VERSION ""

NS_ :

BS_:

BU_: Bat1 OpticalSensor EMUS_BMS SCIMO_PE TelemetryNode Master SensorF SensorR BrakeF BrakeR PDU HVCU HVTU TestBench MDB1 MDB2 MDB3 MDB4 MDB5 MDB6 Track CLU

BO_ 302 MDB6_TX_CurrentDC: 4 Vector__XXX
 SG_ MDB6_TX_CurrentDC : 0|32@1- (0.0001,0) [-214748.3648|214748.3647] "A"  CLU

BO_ 299 MDB5_TX_CurrentDC: 4 Vector__XXX
 SG_ MDB5_TX_CurrentDC : 0|32@1- (0.0001,0) [-214748.3648|214748.3647] "A"  CLU

BO_ 286 MDB4_TX_CurrentDC: 4 Vector__XXX
 SG_ MDB4_TX_CurrentDC : 0|32@1- (0.0001,0) [-214748.3648|214748.3647] "A"  CLU

BO_ 283 MDB3_TX_CurrentDC: 4 Vector__XXX
 SG_ MDB3_TX_CurrentDC : 0|32@1- (0.0001,0) [-214748.3648|214748.3647] "A"  CLU

BO_ 270 MDB2_TX_CurrentDC: 4 Vector__XXX
 SG_ MDB2_TX_CurrentDC : 0|32@1- (0.0001,0) [-214748.3648|214748.3647] "A"  CLU

BO_ 267 MDB1_TX_CurrentDC: 4 Vector__XXX
 SG_ MDB1_TX_CurrentDC : 0|32@1- (0.0001,0) [-214748.3648|214748.3647] "A"  CLU

BO_ 269 MDB2_TX_CurrentTarget: 4 MDB2
 SG_ MDB2_CurrentTarget : 0|32@1- (0.0001,0) [-214748.3648|214748.3647] "A" Vector__XXX

BO_ 266 MDB1_TX_CurrentTarget: 4 MDB1
 SG_ MDB1_CurrentTarget : 0|32@1- (0.0001,0) [-214748.3648|214748.3647] "A" Vector__XXX

BO_ 155 CLU_RX_ConfigureAirGap: 4 Vector__XXX
 SG_ CLU_RX_ConfigureAirGap : 0|32@1- (0.0001,0) [-214748.3648|214748.3647] ""  CLU

BO_ 1072 SensorF_RX_IgnoreLevel: 2 Vector__XXX
 SG_ SensorF_EmergencyLevel : 8|8@1+ (1,0) [0|255] "" Vector__XXX
 SG_ SensorF_IgnoreLevel : 0|8@1+ (1,0) [0|255] ""  SensorF

BO_ 5 PDU_TX_Error: 8 PDU
 SG_ PDU_TX_ErrorPrio : 0|8@1+ (1,0) [0|255] ""  SensorF

BO_ 4 CLU_TX_Error: 8 CLU
 SG_ CLU_TX_ErrorPrio : 0|8@1+ (1,0) [0|255] ""  SensorF

BO_ 3 BrakeF_TX_Error: 8 BrakeF
 SG_ BrakeF_TX_ErrorPrio : 0|8@1+ (1,0) [0|255] ""  SensorF

BO_ 57 CLU_TX_ActionRequest: 5 CLU
 SG_ CLU_TX_TargetAirGap : 8|32@1- (0.0001,0) [-214748.3648|214748.3647] "mm" Vector__XXX
 SG_ CLU_TX_ActionRequest : 0|8@1+ (1,0) [0|255] "" Vector__XXX

BO_ 564 CLU_RX_ActionRequest: 1 SensorF
 SG_ CLU_RX_ActionRequest : 0|8@1+ (1,0) [0|255] ""  SensorF

BO_ 2165346838 BMS44_2_Frame: 8 Vector__XXX
 SG_ BMS44_2_FramePayload : 0|64@1+ (1,0) [0|0] ""  SensorF

BO_ 1792 CLU_RX_StatusLedControll: 1 SensorF
 SG_ CLU_RX_ErrorStatus : 0|1@1+ (1,0) [0|1] ""  CLU

BO_ 592 CLU_TX_LevitationState: 1 CLU
 SG_ CLU_LevitationState : 0|8@1+ (1,0) [0|255] ""  SensorF

BO_ 768 CLU_TX_CoolingState: 1 Vector__XXX
 SG_ CLU_RequiresCooling : 0|1@1+ (1,0) [0|1] ""  SensorF

BO_ 274 MDB3_TX_CurrentMagnet: 4 MDB3
 SG_ MDB3_Current : 0|32@1- (0.0001,0) [-214748.3648|214748.3647] "A"  CLU

BO_ 295 MDB6_TX_CurrentMagnet: 4 MDB6
 SG_ MDB6_Current : 0|32@1- (0.0001,0) [-214748.3648|214748.3647] "A"  CLU

BO_ 297 MDB6_TX_Temperature: 4 MDB6
 SG_ MDB6_Temperature : 0|32@1- (0.0001,0) [-214748.3648|214748.3647] "C"  CLU

BO_ 294 MDB6_TX_AirGap: 4 MDB6
 SG_ MDB6_AirGap : 0|32@1- (0.0001,0) [-214748.3648|214748.3647] "mm"  CLU

BO_ 293 MDB6_TX_State: 1 MDB6
 SG_ MDB6_State : 0|8@1+ (1,0) [0|255] ""  CLU

BO_ 292 MDB5_TX_Temperature: 4 MDB5
 SG_ MDB5_Temperature : 0|32@1- (0.0001,0) [-214748.3648|214748.3647] "C"  CLU

BO_ 290 MDB5_TX_CurrentMagnet: 4 MDB5
 SG_ MDB5_Current : 0|32@1- (0.0001,0) [-214748.3648|214748.3647] "A"  CLU

BO_ 289 MDB5_TX_AirGap: 4 MDB5
 SG_ MDB5_AirGap : 0|32@1- (0.0001,0) [-214748.3648|214748.3647] "mm"  CLU

BO_ 288 MDB5_TX_State: 1 MDB5
 SG_ MDB5_State : 0|8@1+ (1,0) [0|255] ""  CLU

BO_ 281 MDB4_TX_Temperature: 4 MDB4
 SG_ MDB4_Temperature : 0|32@1- (0.0001,0) [-214748.3648|214748.3647] "C"  CLU

BO_ 279 MDB4_TX_CurrentMagnet: 4 MDB4
 SG_ MDB4_Current : 0|32@1- (0.0001,0) [-214748.3648|214748.3647] "mm"  CLU

BO_ 278 MDB4_TX_AirGap: 4 MDB4
 SG_ MDB4_AirGap : 0|32@1- (0.0001,0) [-214748.3648|214748.3647] "mm"  CLU

BO_ 277 MDB4_TX_State: 1 MDB4
 SG_ MDB4_State : 0|8@1+ (1,0) [0|255] ""  CLU

BO_ 276 MDB3_TX_Temperature: 4 MDB3
 SG_ MDB3_Temperature : 0|32@1- (0.0001,0) [-214748.3648|214748.3647] "C"  CLU

BO_ 273 MDB3_TX_AirGap: 4 MDB3
 SG_ MDB3_AirGap : 0|32@1- (0.0001,0) [-214748.3648|214748.3647] "mm"  CLU

BO_ 272 MDB3_TX_State: 1 MDB3
 SG_ MDB3_State : 0|8@1+ (1,0) [0|255] ""  CLU

BO_ 265 MDB2_TX_Temperature: 4 MDB2
 SG_ MDB2_Temperature : 0|32@1- (0.0001,0) [-214748.3648|214748.3647] "C"  CLU

BO_ 263 MDB2_TX_CurrentMagnet: 4 MDB2
 SG_ MDB2_Current : 0|32@1- (0.0001,0) [-214748.3648|214748.3647] "A"  CLU

BO_ 262 MDB2_TX_AirGap: 4 MDB2
 SG_ MDB2_AirGap : 0|32@1- (0.0001,0) [-214748.3648|214748.3647] "mm"  CLU

BO_ 261 MDB2_TX_State: 1 MDB2
 SG_ MDB2_State : 0|8@1+ (1,0) [0|255] ""  CLU

BO_ 258 MDB1_TX_CurrentMagnet: 4 MDB1
 SG_ MDB1_Current : 0|32@1- (0.0001,0) [0|0] "A"  CLU

BO_ 260 MDB1_TX_Temperature: 4 MDB1
 SG_ MDB1_Temperature : 0|32@1- (0.0001,0) [-214748.3648|214748.3647] "C"  CLU,SensorF

BO_ 257 MDB1_TX_AirGap: 4 MDB1
 SG_ MDB1_AirGap : 0|32@1- (0.0001,0) [-214748.3648|214748.3647] "mm"  CLU

BO_ 1041 BrakeF_TX_PressureCooling: 2 BrakeF
 SG_ BrakeF_TX_Pressure_Reservoir : 0|12@1+ (0.005,-2) [-2|18.475] "bar"  SensorF

BO_ 523 PDU_RX_LP_Enable: 1 PDU
 SG_ PDU_RX_LPCh7_Enable : 3|1@1+ (1,0) [0|1] ""  PDU,SensorF
 SG_ PDU_RX_LPCh6_Enable : 2|1@1+ (1,0) [0|1] ""  PDU,SensorF
 SG_ PDU_RX_LPCh5_Enable : 1|1@1+ (1,0) [0|1] ""  PDU,SensorF
 SG_ PDU_RX_LPCh4_Enable : 0|1@1+ (1,0) [0|1] ""  PDU,SensorF

BO_ 2148592864 BMS44_1_Frame: 8 Bat1
 SG_ BMS44_1_FramePayload : 0|64@1+ (1,0) [0|0] ""  SensorF

BO_ 1 Track_TX_Respond: 1 Track
 SG_ Track_TX_Response : 0|8@1+ (1,0) [0|255] ""  SensorF

BO_ 0 Track_RX_Controll: 1 SensorF
 SG_ Track_RX_Command : 0|8@1+ (1,0) [0|255] "" Vector__XXX

BO_ 512 TEST_GROUND_STATION_CONTROLL: 1 Vector__XXX
 SG_ TEST_GROUND_STATION_COMMAND : 0|8@1+ (1,0) [0|255] ""  SensorF

BO_ 256 MDB1_TX_State: 1 MDB1
 SG_ MDB1_State : 0|8@1+ (1,0) [0|255] ""  CLU,SensorF

BO_ 450 SensorR_RX_POD1: 8 Vector__XXX

BO_ 2684354555 OpticalSensor_TX_DetailData: 6 OpticalSensor
 SG_ OpticalSensor_TX_Angle : 32|16@1- (0.01,0) [-45|45] "�" Vector__XXX
 SG_ OpticalSensor_TX_VelTrans : 16|16@1- (0.036,0) [-200|200] "km/h" Vector__XXX
 SG_ OpticalSensor_TX_VelLong : 0|16@1+ (0.036,0) [0|400] "km/h" Vector__XXX

BO_ 2684354554 OpticalSensor_TX_MainData: 8 OpticalSensor
 SG_ OpticalSensor_TX_Distance : 32|32@1+ (0.001,0) [0|4294970] "m"  SensorF,SensorR
 SG_ OpticalSensor_TX_Vel : 16|16@1+ (0.036,0) [0|400] "km/h"  SensorF,SensorR
 SG_ OpticalSensor_TX_Timestamp : 0|16@1+ (1,0) [0|65535] ""  SensorF,SensorR

BO_ 2684354556 OpticalSensor_TX_Status: 8 OpticalSensor
 SG_ OpticalSensor_TX_VddOK : 62|1@1+ (1,0) [0|0] ""  SensorF
 SG_ OpticalSensor_TX_VeeOK : 61|1@1+ (1,0) [0|0] ""  SensorF
 SG_ OpticalSensor_TX_V33OK : 60|1@1+ (1,0) [0|0] ""  SensorF
 SG_ OpticalSensor_TX_V25OK : 59|1@1+ (1,0) [0|0] ""  SensorF
 SG_ OpticalSensor_TX_LEDStatus : 57|2@1+ (1,0) [0|0] ""  SensorF
 SG_ OpticalSensor_TX_LED_Cal : 56|1@1+ (1,0) [0|0] ""  SensorF
 SG_ OpticalSensor_TX_PowerOK : 55|1@1+ (1,0) [0|0] ""  SensorF
 SG_ OpticalSensor_TX_CurrentOK : 54|1@1+ (1,0) [0|0] ""  SensorF
 SG_ OpticalSensor_TX_CurrentLowHigh : 53|1@1+ (1,0) [0|0] ""  SensorF
 SG_ OpticalSensor_TX_OpticOK : 52|1@1+ (1,0) [0|0] ""  SensorF
 SG_ OpticalSensor_TX_TempOK : 51|1@1+ (1,0) [0|0] ""  SensorF
 SG_ OpticalSensor_TX_SensorOK : 50|1@1+ (1,0) [0|0] ""  SensorF
 SG_ OpticalSensor_TX_SelfTest : 49|1@1+ (1,0) [0|0] ""  SensorF
 SG_ OpticalSensor_TX_STST : 48|1@1+ (1,0) [0|0] ""  SensorF
 SG_ OpticalSensor_TX_LEDCurrent : 40|8@1+ (0.01,0) [0|2.55] "A"  SensorF
 SG_ OpticalSensor_TX_Temp : 32|8@1- (1,0) [-128|127] "�C"  SensorF
 SG_ OpticalSensor_TX_SensorNo : 24|8@1+ (1,0) [0|0] ""  SensorF
 SG_ OpticalSensor_TX_SerialNo : 0|24@1+ (1,0) [0|0] ""  SensorF

BO_ 2 CANzero_NMT: 4 Master
 SG_ CANzero_NMT_Node : 16|16@1+ (1,0) [0|63] ""  SensorF,SensorR,BrakeF,BrakeR,PDU,HVCU,HVTU,TelemetryNode,MDB1,MDB2,MDB3,MDB4,MDB5,MDB6,Track,CLU
 SG_ CANzero_NMT_State : 0|16@1+ (1,0) [0|0] ""  SensorF,SensorR,BrakeF,BrakeR,PDU,HVCU,HVTU,TelemetryNode,MDB1,MDB2,MDB3,MDB4,MDB5,MDB6,Track,CLU

BO_ 122 CANzero_Sync: 0 Master

BO_ 123 CANzero_Timestamp: 0 Master

BO_ 129 SensorF_EMCY: 4 SensorF

BO_ 385 SensorF_TX_StatePod: 1 SensorF
 SG_ SensorF_TX_PodState : 0|8@1+ (1,0) [0|0] ""  CLU,Track,BrakeF,PDU

BO_ 449 SensorF_RX_PDO1: 0 Vector__XXX

BO_ 513 SensorF_TX_FSMTransitions: 4 SensorF
 SG_ SensorF_TX_PreopHVCUT : 24|1@1+ (1,0) [0|0] "" Vector__XXX
 SG_ SensorF_TX_PreopPDUT : 16|1@1+ (1,0) [0|0] "" Vector__XXX
 SG_ SensorF_TX_PreopBrakeRT : 15|1@1+ (1,0) [0|0] "" Vector__XXX
 SG_ SensorF_TX_PreopBrakeFT : 14|1@1+ (1,0) [0|0] "" Vector__XXX
 SG_ SensorF_TX_PreopSensorRT : 13|1@1+ (1,0) [0|0] "" Vector__XXX
 SG_ SensorF_TX_EnableSensorRT : 12|1@1+ (1,0) [0|0] "" Vector__XXX
 SG_ SensorF_TX_EnablePDUT : 11|1@1+ (1,0) [0|0] "" Vector__XXX
 SG_ SensorF_TX_EnableHVCUT : 10|1@1+ (1,0) [0|0] "" Vector__XXX
 SG_ SensorF_TX_EnableBrakeRT : 9|1@1+ (1,0) [0|0] "" Vector__XXX
 SG_ SensorF_TX_EnableBrakeFT : 8|1@1+ (1,0) [0|0] "" Vector__XXX
 SG_ SensorF_TX_SetHVTransition : 7|1@1+ (1,0) [0|0] "" Vector__XXX
 SG_ SensorF_TX_PreopTransition : 6|1@1+ (1,0) [0|0] "" Vector__XXX
 SG_ SensorF_TX_LaunchStartTransition : 5|1@1+ (1,0) [0|0] "" Vector__XXX
 SG_ SensorF_TX_LaunchSetupTransition : 4|1@1+ (1,0) [0|0] "" Vector__XXX
 SG_ SensorF_TX_HWEnableTransition : 3|1@1+ (1,0) [0|0] "" Vector__XXX
 SG_ SensorF_TX_ErrorResetTransition : 2|1@1+ (1,0) [0|0] "" Vector__XXX
 SG_ SensorF_TX_EnableTransition : 1|1@1+ (1,0) [0|0] "" Vector__XXX
 SG_ SensorF_TX_BrakesTransition : 0|1@1+ (1,0) [0|0] "" Vector__XXX

BO_ 577 SensorF_RX_PDO2: 0 Vector__XXX

BO_ 641 SensorF_TX_PDO3: 0 SensorF

BO_ 705 SensorF_RX_PDO3: 0 Vector__XXX

BO_ 769 SensorF_TX_PDO4: 0 SensorF

BO_ 833 SensorF_RX_PDO4: 0 Vector__XXX

BO_ 897 SensorF_TX_PDO5: 0 SensorF

BO_ 961 SensorF_TX_PDO6: 0 SensorF

BO_ 1025 SensorF_TX_EncoderFront: 7 SensorF
 SG_ SensorF_GyroFront_X : 40|16@1- (0.017,0) [-557.056|557.039] "°/s"  SensorR
 SG_ SensorF_Vel_EncoderFront : 24|16@1- (0.002,0) [-65.536|65.534] "m/s"  SensorR
 SG_ SensorF_Pos_EncoderFront : 0|18@1- (0.005,0) [-655.36|655.355] "m"  SensorR

BO_ 1089 SensorF_TX_BMS: 2 SensorF
 SG_ SensorF_TX_BatteryTemp : 0|12@1+ (0.05,-30) [-30|174.75] "C"  PDU

BO_ 1153 SensorF_TX_Temperature: 8 SensorF
 SG_ SensorF_Cooling_Temp : 48|12@1+ (0.05,-30) [-30|174.75] "C"  PDU
 SG_ SensorF_LIMT_Stator_4 : 36|12@1+ (0.075,-20) [-20|287.125] "�C" Vector__XXX
 SG_ SensorF_LIMT_Stator_3 : 24|12@1+ (0.075,-20) [-20|287.125] "�C" Vector__XXX
 SG_ SensorF_LIMT_Stator_2 : 12|12@1+ (0.075,-20) [-20|287.125] "�C" Vector__XXX
 SG_ SensorF_LIMT_Stator_1 : 0|12@1+ (0.075,-20) [-20|287.125] "�C" Vector__XXX

BO_ 1217 SensorF_TX_AccFront: 8 SensorF
 SG_ SensorF_GyroFront_Z : 48|16@1- (0.017,0) [-557.056|557.039] "°/s"  SensorR
 SG_ SensorF_AccFront_Z : 32|16@1- (0.00125,0) [-40.96|40.95875] "m/s^2"  SensorR
 SG_ SensorF_AccFront_Y : 16|16@1- (0.00125,0) [-40.96|40.95875] "m/s^2"  SensorR
 SG_ SensorF_AccFront_X : 0|16@1- (0.00125,0) [-40.96|40.95875] "m/s^2"  SensorR

BO_ 1281 SensorF_TX_PDO11: 0 SensorF

BO_ 1345 SensorF_TX_PDO12: 0 SensorF

BO_ 1409 SensorF_SDO_Resp: 8 SensorF
 SG_ SensorF_SDO_RespCode : 12|4@1+ (1,0) [0|0] ""  TelemetryNode
 SG_ SensorF_SDO_ID M : 0|12@1+ (1,0) [0|4095] ""  TelemetryNode

BO_ 1473 SensorF_SDO_Req_Up: 8 TelemetryNode
 SG_ SensorF_SDO_ID M : 0|12@1+ (1,0) [0|4095] ""  SensorF

BO_ 1537 SensorF_SDO_Req_Down: 2 TelemetryNode
 SG_ SensorF_SDO_ID M : 0|12@1+ (1,0) [0|4095] ""  SensorF

BO_ 1793 SensorF_Heartbeat: 1 SensorF
 SG_ SensorF_NodeState : 0|8@1+ (1,0) [0|0] ""  SensorF,Master,TelemetryNode

BO_ 1857 SensorF_BTL_TX: 8 SensorF

BO_ 1921 SensorF_BTL_RX: 8 TelemetryNode

BO_ 130 SensorR_EMCY: 4 SensorR

BO_ 386 SensorR_TX_AccFront: 8 SensorR
 SG_ SensorR_TX_GyroFront_Z : 48|16@1- (0.017,0) [-557.056|557.039] "°/s" Vector__XXX
 SG_ SensorR_TX_AccFront_Z : 32|16@1- (0.00125,0) [-40.96|40.95875] "m/s^2" Vector__XXX
 SG_ SensorR_TX_AccFront_Y : 16|16@1- (0.00125,0) [-40.96|40.95875] "m/s^2" Vector__XXX
 SG_ SensorR_TX_AccFront_X : 0|16@1- (0.00125,0) [-40.96|40.95875] "m/s^2" Vector__XXX

BO_ 514 SensorR_TX_RunStatus: 1 SensorR
 SG_ SensorR_TX_ErrorFlag : 6|1@1+ (1,0) [0|0] "" Vector__XXX
 SG_ SensorR_TX_Enabled : 5|1@1+ (1,0) [0|0] "" Vector__XXX
 SG_ SensorR_TX_TrajectorySet : 4|1@1+ (1,0) [0|0] "" Vector__XXX
 SG_ SensorR_TX_RunState : 0|2@1+ (1,0) [0|0] ""  PDU

BO_ 578 SensorR_RX_PDO2: 0 Vector__XXX

BO_ 642 SensorR_TX_SE: 7 SensorR
 SG_ SensorR_TX_Pos : 32|20@1- (0.001,0) [-524.288|524.287] "m"  PDU,TelemetryNode
 SG_ SensorR_TX_Vel : 16|16@1- (0.002,0) [-65.536|65.534] "m/s"  PDU,TelemetryNode
 SG_ SensorR_TX_Acc : 0|16@1- (0.00125,0) [-40.96|40.95875] "m/s^2"  PDU,TelemetryNode

BO_ 706 SensorR_RX_RunControl: 1 SensorF
 SG_ SensorR_RX_ErrorReset : 3|1@1+ (1,0) [0|0] "" Vector__XXX
 SG_ SensorR_RX_Enable : 2|1@1+ (1,0) [0|0] "" Vector__XXX
 SG_ SensorR_RX_LaunchComm : 0|2@1+ (1,0) [0|0] "" Vector__XXX

BO_ 770 SensorR_TX_Vel: 6 SensorR
 SG_ SensorR_TX_Vel_Optical : 32|16@1- (0.002,0) [-65.536|65.534] "m/s" Vector__XXX
 SG_ SensorR_TX_Vel_EncoderRear : 16|16@1- (0.002,0) [-65.536|65.534] "m/s" Vector__XXX
 SG_ SensorR_TX_Vel_EncoderFront : 0|16@1- (0.002,0) [-65.536|65.534] "m/s" Vector__XXX

BO_ 834 SensorR_RX_PDO4: 0 Vector__XXX

BO_ 898 SensorR_TX_Gyro_XY: 8 SensorR
 SG_ SensorR_TX_GyroRear_Y : 48|16@1- (0.017,0) [-557.056|557.039] "°/s" Vector__XXX
 SG_ SensorR_TX_GyroRear_X : 32|16@1- (0.017,0) [-557.056|557.039] "°/s" Vector__XXX
 SG_ SensorR_TX_GyroFront_Y : 16|16@1- (0.017,0) [-557.056|557.039] "°/s" Vector__XXX
 SG_ SensorR_TX_GyroFront_X : 0|16@1- (0.017,0) [-557.056|557.039] "°/s" Vector__XXX

BO_ 962 SensorR_TX_TargetValues: 2 SensorR
 SG_ SensorR_TX_TargetVelocity : 0|14@1- (0.01,0) [-81.92|81.91] "m/s" Vector__XXX

BO_ 1026 SensorR_TX_GapHeight: 4 SensorR
 SG_ SensorR_TX_GapHeight_Right : 12|12@1- (0.0125,0) [-25.6|25.5875] "mm" Vector__XXX
 SG_ SensorR_TX_GapHeight_Left : 0|12@1- (0.0125,0) [-25.6|25.5875] "mm" Vector__XXX

BO_ 1090 SensorR_TX_PDO8: 0 SensorR

BO_ 1154 SensorR_TX_Temperature: 6 SensorR
 SG_ SensorR_LIMT_Coil_3 : 32|11@1+ (0.1,-5) [-5|199.7] "�C"  PDU
 SG_ SensorR_LIMT_Coil_2 : 16|11@1+ (0.1,-5) [-5|199.7] "�C"  PDU
 SG_ SensorR_LIMT_Coil_1 : 0|11@1+ (0.1,-5) [-5|199.7] "�C"  PDU

BO_ 1218 SensorR_TX_AccRear: 8 SensorR
 SG_ SensorR_TX_GyroRear_Z : 48|16@1- (0.017,0) [-557.056|557.039] "°/s" Vector__XXX
 SG_ SensorR_TX_AccRear_Z : 32|16@1- (0.00125,0) [-40.96|40.95875] "m/s^2" Vector__XXX
 SG_ SensorR_TX_AccRear_Y : 16|16@1- (0.00125,0) [-40.96|40.95875] "m/s^2" Vector__XXX
 SG_ SensorR_TX_AccRear_X : 0|16@1- (0.00125,0) [-40.96|40.95875] "m/s^2" Vector__XXX

BO_ 1282 SensorR_TX_Pos: 8 SensorR
 SG_ SensorR_TX_StripeCounter_Right : 59|5@1+ (1,0) [0|31] "" Vector__XXX
 SG_ SensorR_TX_StripeCounter_Left : 54|5@1+ (1,0) [0|31] "" Vector__XXX
 SG_ SensorR_TX_Pos_Optical : 36|18@1- (0.005,0) [-655.36|655.355] "m" Vector__XXX
 SG_ SensorR_TX_Pos_EncoderRear : 18|18@1- (0.005,0) [-655.36|655.355] "m" Vector__XXX
 SG_ SensorR_TX_Pos_EncoderFront : 0|18@1- (0.005,0) [-655.36|655.355] "m" Vector__XXX

BO_ 1346 SensorR_TX_PDO12: 0 SensorR

BO_ 1410 SensorR_SDO_Resp: 8 SensorR
 SG_ SensorR_SDO_RespCode : 12|4@1+ (1,0) [0|0] ""  TelemetryNode
 SG_ SensorR_SDO_ID M : 0|12@1+ (1,0) [0|4095] ""  PDU,TelemetryNode

BO_ 1474 SensorR_SDO_Req_Up: 8 TelemetryNode
 SG_ SensorR_SDO_ID M : 0|12@1+ (1,0) [0|4095] ""  SensorR

BO_ 1538 SensorR_SDO_Req_Down: 2 TelemetryNode
 SG_ SensorR_SDO_ID M : 0|12@1+ (1,0) [0|4095] ""  SensorR

BO_ 1794 SensorR_Heartbeat: 1 SensorR
 SG_ SensorR_NodeState : 0|8@1+ (1,0) [0|0] ""  Master,TelemetryNode

BO_ 1858 SensorR_BTL_TX: 8 SensorR

BO_ 1922 SensorR_BTL_RX: 8 TelemetryNode

BO_ 145 BrakeF_EMCY: 4 BrakeF

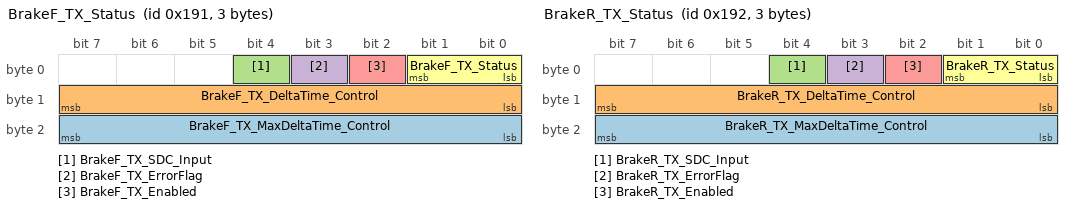
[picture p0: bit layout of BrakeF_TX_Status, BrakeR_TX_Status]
BO_ 401 BrakeF_TX_Status: 3 BrakeF
 SG_ BrakeF_TX_MaxDeltaTime_Control : 16|8@1+ (1,0) [0|255] "ms" Vector__XXX
 SG_ BrakeF_TX_DeltaTime_Control : 8|8@1+ (1,0) [0|255] "ms" Vector__XXX
 SG_ BrakeF_TX_SDC_Input : 4|1@1+ (1,0) [0|0] "" Vector__XXX
 SG_ BrakeF_TX_ErrorFlag : 3|1@1+ (1,0) [0|0] ""  SensorF
 SG_ BrakeF_TX_Enabled : 2|1@1+ (1,0) [0|0] ""  SensorF
 SG_ BrakeF_TX_Status : 0|2@1+ (1,0) [0|0] ""  SensorF

BO_ 465 BrakeF_RX_Control: 1 SensorF
 SG_ BrakeF_RX_Engage : 2|2@1+ (1,0) [0|0] "" Vector__XXX
 SG_ BrakeF_RX_Enable : 1|1@1+ (1,0) [0|0] "" Vector__XXX
 SG_ BrakeF_RX_ErrorReset : 0|1@1+ (1,0) [0|0] "" Vector__XXX

BO_ 529 BrakeF_TX_PDO2: 0 BrakeF

BO_ 593 BrakeF_RX_PDO2: 0 Vector__XXX

BO_ 657 BrakeF_TX_PDO3: 0 BrakeF

BO_ 721 BrakeF_RX_PDO3: 0 Vector__XXX

BO_ 785 BrakeF_TX_PDO4: 0 BrakeF

BO_ 849 BrakeF_RX_PDO4: 0 Vector__XXX

BO_ 913 BrakeF_TX_PDO5: 0 BrakeF

BO_ 977 BrakeF_TX_PDO6: 0 BrakeF

BO_ 1105 BrakeF_TX_PDO8: 0 BrakeF

BO_ 1169 BrakeF_TX_PDO9: 0 BrakeF

BO_ 1233 BrakeF_TX_PDO10: 0 BrakeF

BO_ 1297 BrakeF_TX_PDO11: 0 BrakeF

BO_ 1361 BrakeF_TX_PDO12: 0 BrakeF

BO_ 1425 BrakeF_SDO_Resp: 8 BrakeF
 SG_ BrakeF_SDO_RespCode : 12|4@1+ (1,0) [0|0] ""  TelemetryNode
 SG_ BrakeF_SDO_ID M : 0|12@1+ (1,0) [0|4095] ""  TelemetryNode

BO_ 1489 BrakeF_SDO_Req_Up: 8 TelemetryNode
 SG_ BrakeF_SDO_ID M : 0|12@1+ (1,0) [0|4095] ""  BrakeF

BO_ 1553 BrakeF_SDO_Req_Down: 2 TelemetryNode
 SG_ BrakeF_SDO_ID M : 0|12@1+ (1,0) [0|4095] ""  BrakeF

BO_ 1809 BrakeF_Heartbeat: 1 BrakeF
 SG_ BrakeF_NodeState : 0|8@1+ (1,0) [0|0] ""  SensorF,Master,TelemetryNode

BO_ 1873 BrakeF_BTL_TX: 8 BrakeF

BO_ 1937 BrakeF_BTL_RX: 8 TelemetryNode

BO_ 146 BrakeR_EMCY: 4 BrakeR

BO_ 402 BrakeR_TX_Status: 3 BrakeR
 SG_ BrakeR_TX_MaxDeltaTime_Control : 16|8@1+ (1,0) [0|255] "ms" Vector__XXX
 SG_ BrakeR_TX_DeltaTime_Control : 8|8@1+ (1,0) [0|255] "ms" Vector__XXX
 SG_ BrakeR_TX_SDC_Input : 4|1@1+ (1,0) [0|0] "" Vector__XXX
 SG_ BrakeR_TX_ErrorFlag : 3|1@1+ (1,0) [0|0] "" Vector__XXX
 SG_ BrakeR_TX_Enabled : 2|1@1+ (1,0) [0|0] "" Vector__XXX
 SG_ BrakeR_TX_Status : 0|2@1+ (1,0) [0|0] "" Vector__XXX

BO_ 466 BrakeR_RX_Control: 1 SensorF
 SG_ BrakeR_RX_Engage : 2|2@1+ (1,0) [0|0] "" Vector__XXX
 SG_ BrakeR_RX_Enable : 1|1@1+ (1,0) [0|0] "" Vector__XXX
 SG_ BrakeR_RX_ErrorReset : 0|1@1+ (1,0) [0|0] "" Vector__XXX

BO_ 530 BrakeR_TX_PDO2: 0 BrakeR

BO_ 594 BrakeR_RX_PDO2: 0 Vector__XXX

BO_ 658 BrakeR_TX_PDO3: 0 BrakeR

BO_ 722 BrakeR_RX_PDO3: 0 Vector__XXX

BO_ 786 BrakeR_TX_PDO4: 0 BrakeR

BO_ 850 BrakeR_RX_PDO4: 0 Vector__XXX

BO_ 914 BrakeR_TX_PDO5: 0 BrakeR

BO_ 978 BrakeR_TX_PDO6: 0 BrakeR

BO_ 1042 BrakeR_TX_PDO7: 0 BrakeR

BO_ 1106 BrakeR_TX_Pressure: 5 BrakeR
 SG_ BrakeR_TX_Pressure_Tank : 24|12@1+ (0.005,-2) [-2|18.475] "bar" Vector__XXX
 SG_ BrakeR_TX_Pressure_Retract : 12|12@1+ (0.005,-2) [-2|18.475] "bar" Vector__XXX
 SG_ BrakeR_TX_Pressure_Act : 0|12@1+ (0.005,-2) [-2|18.475] "bar" Vector__XXX

BO_ 1170 BrakeR_TX_PDO9: 0 BrakeR

BO_ 1234 BrakeR_TX_PDO10: 0 BrakeR

BO_ 1298 BrakeR_TX_PDO11: 0 BrakeR

BO_ 1362 BrakeR_TX_PDO12: 0 BrakeR

BO_ 1426 BrakeR_SDO_Resp: 8 BrakeR
 SG_ BrakeR_SDO_RespCode : 12|4@1+ (1,0) [0|0] ""  TelemetryNode
 SG_ BrakeR_SDO_ID M : 0|12@1+ (1,0) [0|4095] ""  TelemetryNode

BO_ 1490 BrakeR_SDO_Req_Up: 8 TelemetryNode
 SG_ BrakeR_SDO_ID M : 0|12@1+ (1,0) [0|4095] ""  BrakeR

BO_ 1554 BrakeR_SDO_Req_Down: 2 TelemetryNode
 SG_ BrakeR_SDO_ID M : 0|12@1+ (1,0) [0|4095] ""  BrakeR

BO_ 1810 BrakeR_Heartbeat: 1 BrakeR
 SG_ BrakeR_NodeState : 0|8@1+ (1,0) [0|0] ""  Master,TelemetryNode

BO_ 1874 BrakeR_BTL_TX: 8 BrakeR

BO_ 1938 BrakeR_BTL_RX: 8 TelemetryNode

BO_ 154 PDU_EMCY: 4 PDU

BO_ 410 PDU_TX_Status: 1 PDU
 SG_ PDU_TX_PEHWEnabled : 2|1@1+ (1,0) [0|0] ""  SensorF
 SG_ PDU_TX_ErrorFlag : 1|1@1+ (1,0) [0|0] ""  SensorF
 SG_ PDU_TX_Enabled : 0|1@1+ (1,0) [0|0] ""  SensorF

BO_ 474 PDU_RX_Control: 1 SensorF
 SG_ PDU_RX_PEHWEnable : 2|1@1+ (1,0) [0|0] ""  PDU
 SG_ PDU_RX_ErrorReset : 1|1@1+ (1,0) [0|0] ""  PDU
 SG_ PDU_RX_Enable : 0|1@1+ (1,0) [0|0] ""  PDU

BO_ 538 PDU_TX_HP_Current: 8 PDU
 SG_ PDU_HPCh4_Current : 48|12@1+ (0.004,0) [0|16.38] "A"  SensorF
 SG_ PDU_HPCh3_Current : 32|12@1+ (0.004,0) [0|16.38] "A"  SensorF
 SG_ PDU_HPCh2_Current : 16|12@1+ (0.004,0) [0|16.38] "A"  SensorF
 SG_ PDU_HPCh1_Current : 0|12@1+ (0.004,0) [0|16.38] "A"  SensorF

BO_ 602 PDU_RX_LP_Dutycycle: 6 SensorF
 SG_ PDU_LPCh9_Dutycycle : 40|8@1+ (0.5,0) [0|100] "%" Vector__XXX
 SG_ PDU_LPCh8_Dutycycle : 32|8@1+ (0.5,0) [0|100] "%" Vector__XXX
 SG_ PDU_LPCh3_Dutycycle : 24|8@1+ (0.5,0) [0|100] "%" Vector__XXX
 SG_ PDU_LPCh2_Dutycycle : 16|8@1+ (0.5,0) [0|100] "%" Vector__XXX
 SG_ PDU_LPCh10_Dutycycle : 8|8@1+ (0.5,0) [0|100] "%" Vector__XXX
 SG_ PDU_LPCh1_Dutycycle : 0|8@1+ (0.5,0) [0|100] "%" Vector__XXX

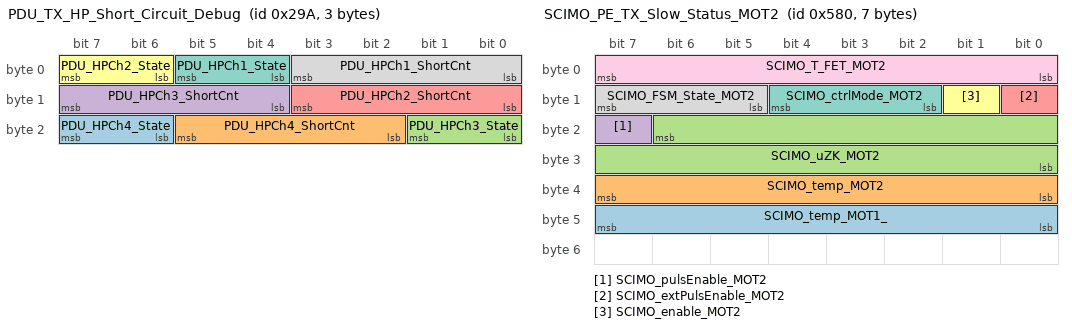
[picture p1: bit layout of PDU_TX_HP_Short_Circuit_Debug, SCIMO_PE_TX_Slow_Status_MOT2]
BO_ 666 PDU_TX_HP_Short_Circuit_Debug: 3 PDU
 SG_ PDU_HPCh4_State : 22|2@1+ (1,0) [0|3] "" Vector__XXX
 SG_ PDU_HPCh4_ShortCnt : 18|4@1+ (1,0) [0|15] "" Vector__XXX
 SG_ PDU_HPCh3_State : 16|2@1+ (1,0) [0|3] "" Vector__XXX
 SG_ PDU_HPCh3_ShortCnt : 12|4@1+ (1,0) [0|15] "" Vector__XXX
 SG_ PDU_HPCh2_ShortCnt : 8|4@1+ (1,0) [0|15] "" Vector__XXX
 SG_ PDU_HPCh2_State : 6|2@1+ (1,0) [0|3] "" Vector__XXX
 SG_ PDU_HPCh1_State : 4|2@1+ (1,0) [0|3] "" Vector__XXX
 SG_ PDU_HPCh1_ShortCnt : 0|4@1+ (1,0) [0|15] "" Vector__XXX

BO_ 730 PDU_RX_HP_Dutycycle: 4 SensorF
 SG_ PDU_HPCh4_Dutycycle : 24|8@1+ (0.5,0) [0|100] "%" Vector__XXX
 SG_ PDU_HPCh3_Dutycycle : 16|8@1+ (0.5,0) [0|100] "%" Vector__XXX
 SG_ PDU_HPCh2_Dutycycle : 8|8@1+ (0.5,0) [0|100] "%"  PDU
 SG_ PDU_HPCh1_Dutycycle : 0|8@1+ (0.5,0) [0|100] "%"  PDU

BO_ 794 PDU_TX_PDO4: 0 PDU

BO_ 858 PDU_RX_Manual_Control: 3 Vector__XXX
 SG_ PDU_SDC_Enable : 18|1@1+ (1,0) [0|0] "" Vector__XXX
 SG_ PDU_D4_Enable : 17|1@1+ (1,0) [0|1] "" Vector__XXX
 SG_ PDU_D3_Enable : 16|1@1+ (1,0) [0|1] "" Vector__XXX
 SG_ PDU_D2_Enable : 15|1@1+ (1,0) [0|1] "" Vector__XXX
 SG_ PDU_D1_Enable : 14|1@1+ (1,0) [0|1] "" Vector__XXX
 SG_ PDU_HPCh4_Enable : 13|1@1+ (1,0) [0|1] "" Vector__XXX
 SG_ PDU_HPCh3_Enable : 12|1@1+ (1,0) [0|1] "" Vector__XXX
 SG_ PDU_HPCh2_Enable : 11|1@1+ (1,0) [0|1] "" Vector__XXX
 SG_ PDU_HPCh1_Enable : 10|1@1+ (1,0) [0|1] "" Vector__XXX
 SG_ PDU_LPCh10_Enable : 9|1@1+ (1,0) [0|1] "" Vector__XXX
 SG_ PDU_LPCh9_Enable : 8|1@1+ (1,0) [0|1] "" Vector__XXX
 SG_ PDU_LPCh8_Enable : 7|1@1+ (1,0) [0|1] "" Vector__XXX
 SG_ PDU_LPCh7_Enable : 6|1@1+ (1,0) [0|1] "" Vector__XXX
 SG_ PDU_LPCh6_Enable : 5|1@1+ (1,0) [0|1] "" Vector__XXX
 SG_ PDU_LPCh5_Enable : 4|1@1+ (1,0) [0|1] "" Vector__XXX
 SG_ PDU_LPCh4_Enable : 3|1@1+ (1,0) [0|1] "" Vector__XXX
 SG_ PDU_LPCh3_Enable : 2|1@1+ (1,0) [0|1] "" Vector__XXX
 SG_ PDU_LPCh2_Enable : 1|1@1+ (1,0) [0|1] "" Vector__XXX
 SG_ PDU_LPCh1_Enable : 0|1@1+ (1,0) [0|1] "" Vector__XXX

BO_ 922 PDU_TX_PDO5: 0 PDU

BO_ 986 PDU_TX_PDO6: 0 PDU

BO_ 1050 PDU_TX_PDO7: 0 PDU

BO_ 1114 PDU_TX_PDO8: 0 PDU

BO_ 1178 PDU_TX_LP_Short_Circuit_Debug: 8 PDU
 SG_ PDU_LPCh9_State : 58|2@1+ (1,0) [0|3] "" Vector__XXX
 SG_ PDU_LPCh8_State : 56|2@1+ (1,0) [0|3] "" Vector__XXX
 SG_ PDU_LPCh7_State : 54|2@1+ (1,0) [0|3] "" Vector__XXX
 SG_ PDU_LPCh6_State : 52|2@1+ (1,0) [0|3] "" Vector__XXX
 SG_ PDU_LPCh5_State : 50|2@1+ (1,0) [0|3] "" Vector__XXX
 SG_ PDU_LPCh4_State : 48|2@1+ (1,0) [0|3] "" Vector__XXX
 SG_ PDU_LPCh3_State : 46|2@1+ (1,0) [0|3] "" Vector__XXX
 SG_ PDU_LPCh2_State : 44|2@1+ (1,0) [0|3] "" Vector__XXX
 SG_ PDU_LPCh1_State : 42|2@1+ (1,0) [0|3] "" Vector__XXX
 SG_ PDU_LPCh10_State : 40|2@1+ (1,0) [0|3] "" Vector__XXX
 SG_ PDU_LPCh9_ShortCnt : 36|4@1+ (1,0) [0|15] "" Vector__XXX
 SG_ PDU_LPCh8_ShortCnt : 32|4@1+ (1,0) [0|15] "" Vector__XXX
 SG_ PDU_LPCh7_ShortCnt : 28|4@1+ (1,0) [0|15] "" Vector__XXX
 SG_ PDU_LPCh6_ShortCnt : 24|4@1+ (1,0) [0|15] "" Vector__XXX
 SG_ PDU_LPCh5_ShortCnt : 20|4@1+ (1,0) [0|15] "" Vector__XXX
 SG_ PDU_LPCh4_ShortCnt : 16|4@1+ (1,0) [0|15] "" Vector__XXX
 SG_ PDU_LPCh3_ShortCnt : 12|4@1+ (1,0) [0|15] "" Vector__XXX
 SG_ PDU_LPCh2_ShortCnt : 8|4@1+ (1,0) [0|15] "" Vector__XXX
 SG_ PDU_LPCh1_ShortCnt : 4|4@1+ (1,0) [0|15] "" Vector__XXX
 SG_ PDU_LPCh10_ShortCnt : 0|4@1+ (1,0) [0|15] "" Vector__XXX

BO_ 1242 PDU_TX_LV_BMS: 4 PDU
 SG_ PDU_LV_SOC : 24|8@1- (1,0) [0|100] "%" Vector__XXX
 SG_ PDU_LV_Voltage : 12|12@1+ (0.01,0) [0|40.95] "V" Vector__XXX
 SG_ PDU_LV_Current : 0|12@1+ (0.01,0) [0|40.95] "A" Vector__XXX

BO_ 1306 PDU_TX_LP_Current1: 8 PDU
 SG_ PDU_LPCh5_Current : 48|12@1+ (0.002,0) [0|8.19] "A"  SensorF
 SG_ PDU_LPCh4_Current : 36|12@1+ (0.002,0) [0|8.19] "A"  SensorF
 SG_ PDU_LPCh3_Current : 24|12@1+ (0.002,0) [0|8.19] "A"  SensorF
 SG_ PDU_LPCh2_Current : 12|12@1+ (0.002,0) [0|8.19] "A"  SensorF
 SG_ PDU_LPCh1_Current : 0|12@1+ (0.002,0) [0|8.19] "A"  SensorF

BO_ 1370 PDU_TX_LP_Current2: 8 PDU
 SG_ PDU_LPCh9_Current : 48|12@1+ (0.002,0) [0|8.19] "A"  SensorF
 SG_ PDU_LPCh8_Current : 36|12@1+ (0.002,0) [0|8.19] "A"  SensorF
 SG_ PDU_LPCh7_Current : 24|12@1+ (0.002,0) [0|8.19] "A"  SensorF
 SG_ PDU_LPCh6_Current : 12|12@1+ (0.002,0) [0|8.19] "A"  SensorF
 SG_ PDU_LPCh10_Current : 0|12@1+ (0.002,0) [0|8.19] "A"  SensorF

BO_ 1434 PDU_SDO_Resp: 8 PDU
 SG_ PDU_SDO_RespCode : 12|4@1+ (1,0) [0|0] ""  TelemetryNode
 SG_ PDU_SDO_ID M : 0|12@1+ (1,0) [0|4095] ""  TelemetryNode

BO_ 1498 PDU_SDO_Req_Up: 8 TelemetryNode
 SG_ PDU_SDO_ID M : 0|12@1+ (1,0) [0|4095] ""  PDU

BO_ 1562 PDU_SDO_Req_Down: 2 TelemetryNode
 SG_ PDU_SDO_ID M : 0|12@1+ (1,0) [0|4095] ""  PDU

BO_ 1818 PDU_Heartbeat: 1 PDU
 SG_ PDU_NodeState : 0|8@1+ (1,0) [0|0] ""  SensorF,Master,TelemetryNode

BO_ 1882 PDU_BTL_TX: 8 PDU

BO_ 1946 PDU_BTL_RX: 8 TelemetryNode

BO_ 138 HVCU_EMCY: 4 HVCU

BO_ 394 HVCU_TX_Status: 1 HVCU
 SG_ HVCU_TX_Enabled : 7|1@1+ (1,0) [0|0] "" Vector__XXX
 SG_ HVCU_TX_ErrorFlag : 6|1@1+ (1,0) [0|0] "" Vector__XXX
 SG_ HVCU_TX_Status : 3|3@1+ (1,0) [0|0] "" Vector__XXX
 SG_ HVCU_TX_InternalStatus : 0|3@1+ (1,0) [0|0] "" Vector__XXX

BO_ 458 HVCU_RX_Control: 1 SensorF
 SG_ HVCU_RX_Charging : 3|1@1+ (1,0) [0|0] "" Vector__XXX
 SG_ HVCU_RX_ErrorReset : 2|1@1+ (1,0) [0|0] "" Vector__XXX
 SG_ HVCU_RX_Activate : 1|1@1+ (1,0) [0|0] "" Vector__XXX
 SG_ HVCU_RX_Enable : 0|1@1+ (1,0) [0|0] "" Vector__XXX

BO_ 522 HVCU_TX_PDO2: 0 HVCU

BO_ 586 HVCU_RX_PDO2: 0 Vector__XXX

BO_ 650 HVCU_TX_IMD: 4 HVCU
 SG_ HVCU_IMD_Isolation_Resistance : 16|16@1+ (1,0) [0|65535] "kOhm" Vector__XXX
 SG_ HVCU_IMD_Frequency : 8|8@1+ (1,0) [0|60] "Hz" Vector__XXX
 SG_ HVCU_IMD_DutyCycle : 0|8@1+ (1,0) [0|100] "%" Vector__XXX

BO_ 714 HVCU_RX_PDO3: 0 Vector__XXX

BO_ 778 HVCU_TX_PDO4: 0 HVCU

BO_ 842 HVCU_RX_PDO4: 0 Vector__XXX

BO_ 906 HVCU_TX_PDO5: 0 HVCU

BO_ 970 HVCU_TX_PDO6: 0 HVCU

BO_ 1034 HVCU_TX_PDO7: 0 HVCU

BO_ 1098 HVCU_TX_PDO8: 0 HVCU

BO_ 1162 HVCU_TX_PDO9: 0 HVCU

BO_ 1226 HVCU_TX_PDO10: 0 HVCU

BO_ 1290 HVCU_TX_PDO11: 0 HVCU

BO_ 1354 HVCU_TX_PDO12: 0 HVCU

BO_ 1418 HVCU_SDO_Resp: 8 HVCU
 SG_ HVCU_SDO_RespCode : 12|4@1+ (1,0) [0|0] ""  TelemetryNode
 SG_ HVCU_SDO_ID M : 0|12@1+ (1,0) [0|4095] ""  TelemetryNode

BO_ 1482 HVCU_SDO_Req_Up: 8 TelemetryNode
 SG_ HVCU_SDO_ID M : 0|12@1+ (1,0) [0|4095] ""  HVCU

BO_ 1546 HVCU_SDO_Req_Down: 2 TelemetryNode
 SG_ HVCU_SDO_ID M : 0|12@1+ (1,0) [0|4095] ""  HVCU

BO_ 1802 HVCU_Heartbeat: 1 HVCU
 SG_ HVCU_NodeState : 0|8@1+ (1,0) [0|0] ""  Master,TelemetryNode

BO_ 1866 HVCU_BTL_TX: 8 HVCU

BO_ 1930 HVCU_BTL_RX: 8 TelemetryNode

BO_ 153 HVTU_EMCY: 4 HVTU

BO_ 2684289024 EMUS_Internal_01: 8 EMUS_BMS

BO_ 2684289025 EMUS_Internal_02: 8 EMUS_BMS

BO_ 2684289026 EMUS_Internal_03: 8 EMUS_BMS

BO_ 2684289027 EMUS_Internal_04: 8 EMUS_BMS

BO_ 2684289028 EMUS_Internal_05: 8 EMUS_BMS

BO_ 2684289029 EMUS_Internal_06: 8 EMUS_BMS

BO_ 2684289030 EMUS_Internal_07: 8 EMUS_BMS

BO_ 2684289031 EMUS_Internal_08: 8 EMUS_BMS

BO_ 2684289032 EMUS_Internal_09: 8 EMUS_BMS

BO_ 2684289033 EMUS_Internal_10: 8 EMUS_BMS

BO_ 2684289034 EMUS_Internal_11: 8 EMUS_BMS

BO_ 2684289035 EMUS_Internal_12: 8 EMUS_BMS

BO_ 2684289036 EMUS_Internal_13: 8 EMUS_BMS

BO_ 2684289037 EMUS_Internal_14: 8 EMUS_BMS

BO_ 2684289038 EMUS_Internal_15: 8 EMUS_BMS

BO_ 2684289039 EMUS_Internal_16: 8 EMUS_BMS

BO_ 2684289040 EMUS_Internal_17: 8 EMUS_BMS

BO_ 2684289041 EMUS_Internal_18: 8 EMUS_BMS

BO_ 2684289042 EMUS_Internal_19: 8 EMUS_BMS

BO_ 2684289043 EMUS_Internal_20: 8 EMUS_BMS

BO_ 2684289044 EMUS_Internal_21: 8 EMUS_BMS

BO_ 2684289045 EMUS_Internal_22: 8 EMUS_BMS

BO_ 2684289046 EMUS_Internal_23: 8 EMUS_BMS

BO_ 2684289047 EMUS_Internal_24: 8 EMUS_BMS

BO_ 2684289048 EMUS_Internal_25: 8 EMUS_BMS

BO_ 2684289049 EMUS_Internal_26: 8 EMUS_BMS

BO_ 2684289050 EMUS_Internal_27: 8 EMUS_BMS

BO_ 2684289051 EMUS_Internal_28: 8 EMUS_BMS

BO_ 2684289052 EMUS_Internal_29: 8 EMUS_BMS

BO_ 2684289053 EMUS_Internal_30: 8 EMUS_BMS

BO_ 2684289054 EMUS_Internal_31: 8 EMUS_BMS

BO_ 2684289055 EMUS_Internal_32: 8 EMUS_BMS

BO_ 2684289056 EMUS_Internal_33: 8 EMUS_BMS

BO_ 2684289057 EMUS_Internal_34: 8 EMUS_BMS

BO_ 2684289058 EMUS_Internal_35: 8 EMUS_BMS

BO_ 2684289059 EMUS_Internal_36: 8 EMUS_BMS

BO_ 2684289060 EMUS_Internal_37: 8 EMUS_BMS

BO_ 2684289061 EMUS_Internal_38: 8 EMUS_BMS

BO_ 2684289062 EMUS_Internal_39: 8 EMUS_BMS

BO_ 2684289063 EMUS_Internal_40: 8 EMUS_BMS

BO_ 2684289064 EMUS_Internal_41: 8 EMUS_BMS

BO_ 2684289065 EMUS_Internal_42: 8 EMUS_BMS

BO_ 2684289066 EMUS_Internal_43: 8 EMUS_BMS

BO_ 2684289067 EMUS_Internal_44: 8 EMUS_BMS

BO_ 2684289068 EMUS_Internal_45: 8 EMUS_BMS

BO_ 2684289069 EMUS_Internal_46: 8 EMUS_BMS

BO_ 2684289070 EMUS_Internal_47: 8 EMUS_BMS

BO_ 2684289071 EMUS_Internal_48: 8 EMUS_BMS

BO_ 1509 SCIMO_PE_TX_Electric_MZ_V_FAST: 6 SCIMO_PE
 SG_ SCIMO_V_SET_W_MOT2 : 39|16@0- (0.02,0) [-655.36|655.34] "" Vector__XXX
 SG_ SCIMO_V_SET_V_MOT2 : 23|16@0- (0.02,0) [-655.36|655.34] "" Vector__XXX
 SG_ SCIMO_V_SET_U_MOT2 : 7|16@0- (0.02,0) [-655.36|655.34] "" Vector__XXX

BO_ 1508 SCIMO_PE_TX_Electric_MZ_I_FAST: 6 SCIMO_PE
 SG_ SCIMO_I_MES_W_MOT2 : 39|16@0- (0.02,0) [-655.36|655.34] "" Vector__XXX
 SG_ SCIMO_I_MES_V_MOT2 : 23|16@0- (0.02,0) [-655.36|655.34] "" Vector__XXX
 SG_ SCIMO_I_MES_U_MOT2 : 7|16@0- (0.02,0) [-655.36|655.34] "" Vector__XXX

BO_ 1488 SCIMO_PE_TX_AmbientTemp_MOT2: 8 SensorR
 SG_ SCIMO_Temp_ThermocoupleJ_MOT2 : 55|16@0- (0.005,150) [-13.84|313.835] ""  TestBench
 SG_ SCIMO_Temp_ThermocoupleK_MOT2 : 39|16@0- (0.005,150) [-13.84|313.835] ""  TestBench
 SG_ SCIMO_Temp_ADS_Ambient_MOT2 : 23|16@0- (0.005,150) [-13.84|313.835] ""  TestBench
 SG_ SCIMO_Temp_RotorAmbient_MOT2 : 7|16@0- (0.005,150) [-13.84|313.835] ""  TestBench

BO_ 1472 SCIMO_PE_TX_AmbientTemp_MOT1: 8 SensorR
 SG_ SCIMO_Temp_ThermocoupleJ_MOT1 : 55|16@0- (0.005,150) [-13.84|313.835] ""  TestBench
 SG_ SCIMO_Temp_ThermocoupleK_MOT1 : 39|16@0- (0.005,150) [-13.84|313.835] ""  TestBench
 SG_ SCIMO_Temp_ADS_Ambient_MOT1 : 23|16@0- (0.005,150) [-13.84|313.835] ""  TestBench
 SG_ SCIMO_Temp_RotorAmbient_MOT1 : 7|16@0- (0.005,150) [-13.84|313.835] ""  TestBench

BO_ 1456 SCIMO_MS_RX_RequestData: 2 SensorR
 SG_ SCIMO_NumOfSamples : 7|16@0+ (1,0) [0|65535] ""  TestBench

BO_ 1440 SCIMO_MS_TX_Electric: 8 SCIMO_PE
 SG_ SCIMO_U_Q_MOT : 55|16@0- (0.025,0) [-819.2|819.175] ""  TestBench
 SG_ SCIMO_U_D_MOT : 39|16@0- (0.025,0) [-819.2|819.175] ""  TestBench
 SG_ SCIMO_I_Q_MOT : 23|16@0- (0.025,0) [-819.2|819.175] ""  TestBench
 SG_ SCIMO_I_D_MOT : 7|16@0- (0.025,0) [-819.2|819.175] ""  TestBench

BO_ 1344 SCIMO_PE_TX_MotorTemp_MOT2: 6 SensorR
 SG_ SCIMO_Temp_PT100B_MOT2 : 39|16@0- (0.005,150) [-13.84|313.835] ""  TestBench
 SG_ SCIMO_Temp_PT100A_MOT2 : 23|16@0- (0.005,150) [-13.84|313.835] ""  TestBench
 SG_ SCIMO_Temp_Rotor_MOT2 : 7|16@0- (0.005,150) [-13.84|313.835] ""  TestBench

BO_ 1328 SCIMO_PE_TX_MotorTemp_MOT1: 6 SensorR
 SG_ SCIMO_Temp_PT100B_MOT1 : 39|16@0- (0.005,150) [-13.84|313.835] ""  TestBench
 SG_ SCIMO_Temp_PT100A_MOT1 : 23|16@0- (0.005,150) [-13.84|313.835] ""  TestBench
 SG_ SCIMO_Temp_Rotor_MOT1 : 7|16@0- (0.005,150) [-13.84|313.835] ""  TestBench

BO_ 1520 SCIMO_PE_TX_Status: 6 SCIMO_PE
 SG_ SCIMO_tempCPU : 47|8@0+ (0.5,0) [0|127.5] ""  TestBench,SensorR
 SG_ SCIMO_VCC_LV : 39|8@0+ (0.25,6) [6|69.75] ""  TestBench,SensorR
 SG_ SCIMO_I_LV : 31|8@0+ (0.01,0) [0|2.55] ""  TestBench,SensorR
 SG_ SCIMO_tempAUX2 : 23|8@0+ (1,0) [0|255] ""  TestBench,SensorR
 SG_ SCIMO_tempAUX1 : 15|8@0+ (1,0) [0|255] ""  TestBench,SensorR
 SG_ SCIMO_tempPCB : 7|8@0+ (1,0) [0|255] ""  TestBench,SensorR

BO_ 1408 SCIMO_PE_TX_Slow_Status_MOT2: 7 SCIMO_PE
 SG_ SCIMO_temp_MOT1_ : 47|8@0+ (1,0) [0|0] ""  TestBench,SensorR
 SG_ SCIMO_temp_MOT2 : 39|8@0+ (1,0) [0|0] ""  TestBench,SensorR
 SG_ SCIMO_uZK_MOT2 : 22|15@0- (0.1,0) [0|0] ""  TestBench,SensorR
 SG_ SCIMO_pulsEnable_MOT2 : 23|1@0+ (1,0) [0|0] ""  TestBench,SensorR
 SG_ SCIMO_extPulsEnable_MOT2 : 8|1@0+ (1,0) [0|0] ""  TestBench,SensorR
 SG_ SCIMO_enable_MOT2 : 9|1@0+ (1,0) [0|0] ""  TestBench,SensorR
 SG_ SCIMO_ctrlMode_MOT2 : 12|3@0+ (1,0) [0|0] ""  TestBench,SensorR
 SG_ SCIMO_FSM_State_MOT2 : 15|3@0+ (1,0) [0|0] ""  TestBench,SensorR
 SG_ SCIMO_T_FET_MOT2 : 7|8@0+ (1,0) [0|0] ""  TestBench,SensorR

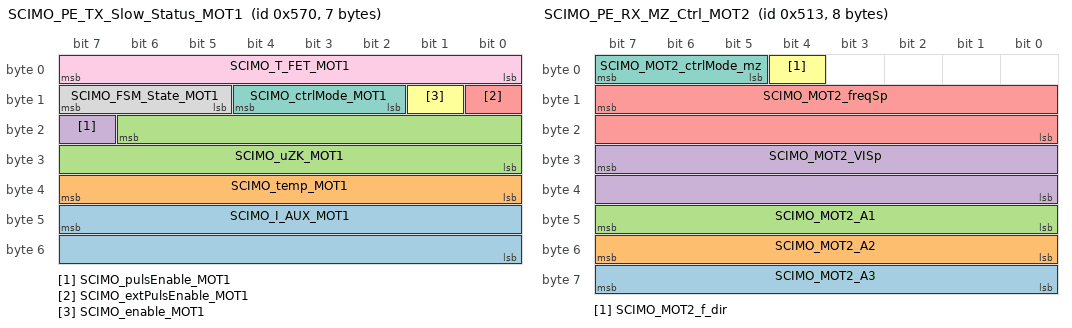
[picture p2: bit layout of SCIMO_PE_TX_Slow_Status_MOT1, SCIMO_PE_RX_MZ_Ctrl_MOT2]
BO_ 1392 SCIMO_PE_TX_Slow_Status_MOT1: 7 SCIMO_PE
 SG_ SCIMO_I_AUX_MOT1 : 47|16@0- (1,0) [-32768|32767] ""  TestBench
 SG_ SCIMO_temp_MOT1 : 39|8@0+ (1,0) [0|0] ""  TestBench,SensorR
 SG_ SCIMO_uZK_MOT1 : 22|15@0- (0.1,0) [0|0] ""  TestBench,SensorR
 SG_ SCIMO_pulsEnable_MOT1 : 23|1@0+ (1,0) [0|0] ""  TestBench,SensorR
 SG_ SCIMO_extPulsEnable_MOT1 : 8|1@0+ (1,0) [0|0] ""  TestBench,SensorR
 SG_ SCIMO_enable_MOT1 : 9|1@0+ (1,0) [0|0] ""  TestBench,SensorR
 SG_ SCIMO_ctrlMode_MOT1 : 12|3@0+ (1,0) [0|0] ""  TestBench,SensorR
 SG_ SCIMO_FSM_State_MOT1 : 15|3@0+ (1,0) [0|0] ""  TestBench,SensorR
 SG_ SCIMO_T_FET_MOT1 : 7|8@0+ (1,0) [0|0] ""  TestBench,SensorR

BO_ 1504 SCIMO_PE_TX_Electric: 8 SCIMO_PE
 SG_ I_Q_MOT2 : 55|16@0- (1,0) [0|0] ""  TestBench,SensorR
 SG_ I_D_MOT2 : 39|16@0- (1,0) [0|0] ""  TestBench,SensorR
 SG_ I_Q_MOT1 : 23|16@0- (1,0) [0|0] ""  TestBench,SensorR
 SG_ I_D_MOT1 : 7|16@0- (1,0) [0|0] ""  TestBench,SensorR

BO_ 1510 SCIMO_PE_TX_MZ_Electric: 8 SCIMO_PE
 SG_ SCIMO_I_Q_MOT2 : 55|16@0- (0.05,0) [-1638.4|1638.35] ""  TestBench,SensorR
 SG_ SCIMO_I_D_MOT2 : 39|16@0- (0.05,0) [-1638.4|1638.35] ""  TestBench,SensorR
 SG_ SCIMO_f_REQ_LOWPASS_MOT2 : 23|13@0+ (0.05,0) [0|409.55] ""  TestBench,SensorR
 SG_ SCIMO_I_REQ_LOWPASS_MOT2 : 7|13@0+ (0.05,0) [0|409.55] ""  TestBench,SensorR

BO_ 1312 SCIMO_PE_TX_Errors: 5 SCIMO_PE
 SG_ SCIMO_warnNum_MOT2 : 25|10@0+ (1,0) [0|0] ""  TestBench,SensorR
 SG_ SCIMO_warnNum_MOT1 : 19|10@0+ (1,0) [0|1023] ""  TestBench,SensorR
 SG_ SCIMO_errNum_MOT2 : 15|8@0+ (1,0) [0|0] ""  TestBench,SensorR
 SG_ SCIMO_errNum_MOT1 : 7|8@0+ (1,0) [0|0] ""  TestBench,SensorR

BO_ 1360 SCIMO_PE_TX_Mech_fast: 8 SCIMO_PE
 SG_ SCIMO_M_ist_gw_MOT2 : 55|16@0- (1,0) [0|0] ""  TestBench,SensorR
 SG_ SCIMO_n_gw_MOT2 : 39|16@0- (1,0) [0|0] ""  TestBench,SensorR
 SG_ SCIMO_M_ist_gw_MOT1 : 23|16@0- (1,0) [0|0] ""  TestBench,SensorR
 SG_ SCIMO_n_gw_MOT1 : 7|16@0- (1,0) [0|0] ""  TestBench,SensorR

BO_ 1299 SCIMO_PE_RX_MZ_Ctrl_MOT2: 8 SensorR
 SG_ SCIMO_MOT2_A3 : 56|8@1+ (0.01,0) [0|2.55] ""  SCIMO_PE
 SG_ SCIMO_MOT2_A2 : 48|8@1+ (0.01,0) [0|2.55] ""  SCIMO_PE
 SG_ SCIMO_MOT2_A1 : 40|8@1+ (0.01,0) [0|2.55] ""  SCIMO_PE
 SG_ SCIMO_MOT2_VISp : 31|16@0+ (0.01,0) [0|655.35] ""  TestBench,SCIMO_PE
 SG_ SCIMO_MOT2_freqSp : 15|16@0+ (0.02,0) [0|1310.7] ""  TestBench,SCIMO_PE
 SG_ SCIMO_MOT2_f_dir : 4|1@0+ (1,0) [0|0] ""  SCIMO_PE
 SG_ SCIMO_MOT2_ctrlMode_mz : 7|3@0+ (1,0) [0|0] ""  TestBench,SCIMO_PE

BO_ 1280 SCIMO_PE_RX_Ctrl_MOT1: 5 SensorR
 SG_ SCIMO_MOT1_limitSp : 31|16@0- (1,0) [0|0] ""  TestBench,SCIMO_PE
 SG_ SCIMO_MOT1_targetSp : 15|16@0- (1,0) [0|0] ""  TestBench,SCIMO_PE
 SG_ SCIMO_MOT1_reset : 3|1@0+ (1,0) [0|0] ""  TestBench,SCIMO_PE
 SG_ SCIMO_MOT1_ctrlMode : 6|3@0+ (1,0) [0|0] ""  TestBench,SCIMO_PE
 SG_ SCIMO_MOT1_enable : 7|1@0+ (1,0) [0|0] ""  TestBench,SCIMO_PE

BO_ 1296 SCIMO_PE_RX_Ctrl_MOT2: 5 SensorR
 SG_ SCIMO_MOT2_limitSp : 31|16@0- (1,0) [0|0] ""  TestBench,SCIMO_PE
 SG_ SCIMO_MOT2_targetSp : 15|16@0- (1,0) [0|0] ""  TestBench,SCIMO_PE
 SG_ SCIMO_MOT2_reset : 3|1@0+ (1,0) [0|0] ""  TestBench,SCIMO_PE
 SG_ SCIMO_MOT2_ctrlMode : 6|3@0+ (1,0) [0|0] ""  TestBench,SCIMO_PE
 SG_ SCIMO_MOT2_enable : 7|1@0+ (1,0) [0|0] ""  TestBench,SCIMO_PE

BO_ 2578776065 EMUS_Battery_Volt_Overall_Param_: 8 EMUS_BMS
 SG_ EMUS_VoltOverallParams_TVoltThir : 48|8@1+ (1,0) [0|255] ""  HVCU,HVTU
 SG_ EMUS_VoltOverallParams_TVoltMSB : 40|8@1+ (1,0) [0|255] ""  HVCU,HVTU
 SG_ EMUS_VoltOverallParams_TVoltLSB : 32|8@1+ (1,0) [0|255] ""  HVCU,HVTU
 SG_ EMUS_VoltOverallParams_TVoltSecB : 24|8@1+ (1,0) [0|255] ""  HVCU,HVTU
 SG_ EMUS_VoltOverallParam_AvrgCellVo : 16|8@1+ (0.01,2) [2|4.55] "V"  HVCU,HVTU
 SG_ EMUS_VoltOverallParam_MaxCellVol : 8|8@1+ (0.01,2) [2|4.55] "V"  HVCU,HVTU
 SG_ EMUS_VoltOverallParam_MinCellVol : 0|8@1+ (0.01,2) [2|4.55] "V"  HVCU,HVTU

BO_ 2578776064 EMUS_Overall_Parameters_Ext: 8 EMUS_BMS
 SG_ EMUS_OverallParams_NumberOf_0000 : 56|8@1+ (1,0) [0|255] ""  HVCU
 SG_ EMUS_OverallParams_LastChargingE : 48|8@1+ (1,0) [0|255] ""  HVCU
 SG_ EMUS_OverallParams_ChrgStag_0000 : 40|8@1+ (1,0) [0|255] ""  HVCU
 SG_ EMUS_OverallParams_ChrgStageDura : 32|8@1+ (1,0) [0|255] ""  HVCU
 SG_ EMUS_OverallParams_ChargingStage : 24|8@1+ (1,0) [0|255] ""  HVCU
 SG_ EMUS_OverallParams_NumberOfCells : 16|8@1+ (1,0) [0|255] ""  HVCU
 SG_ EMUS_OverallParams_ContactorPreC : 15|1@1+ (1,0) [0|1] ""  HVCU
 SG_ EMUS_OverallParams_DCDC_Control : 14|1@1+ (1,0) [0|1] ""  HVCU
 SG_ EMUS_OverallParams_ChargingInter : 13|1@1+ (1,0) [0|1] ""  HVCU
 SG_ EMUS_OverallParams_PowerReductio : 12|1@1+ (1,0) [0|1] ""  HVCU
 SG_ EMUS_OverallParams_BatteryFan : 11|1@1+ (1,0) [0|1] ""  HVCU
 SG_ EMUS_OverallParams_BatteryContac : 10|1@1+ (1,0) [0|1] ""  HVCU
 SG_ EMUS_OverallParams_HeaterEnable : 9|1@1+ (1,0) [0|1] ""  HVCU
 SG_ EMUS_OverallParams_ChargerEnable : 8|1@1+ (1,0) [0|1] ""  HVCU
 SG_ EMUS_OverallParams_LeakageSensor : 3|1@1+ (1,0) [0|1] ""  HVCU
 SG_ EMUS_OverallParams_FastCharge : 2|1@1+ (1,0) [0|1] ""  HVCU
 SG_ EMUS_OverallParams_ChargerMains : 1|1@1+ (1,0) [0|1] ""  HVCU
 SG_ EMUS_OverallParams_IgnitionKey : 0|1@1+ (1,0) [0|1] ""  HVCU

BO_ 2578776071 EMUS_Diagnostic_Codes_Ext: 8 EMUS_BMS
 SG_ EMUS_DiagnosticCodes_CellTempVal : 29|1@1+ (1,0) [0|1] ""  HVCU,HVTU
 SG_ EMUS_DiagnosticCodes_BatChrgFini : 28|1@1+ (1,0) [0|1] ""  HVCU,HVTU
 SG_ EMUS_DiagnosticCodes_NumOfCellsV : 27|1@1+ (1,0) [0|1] ""  HVCU,HVTU
 SG_ EMUS_DiagnosticCodes_CellBalancV : 26|1@1+ (1,0) [0|1] ""  HVCU,HVTU
 SG_ EMUS_DiagnosticCodes_CellModTemp : 25|1@1+ (1,0) [0|1] ""  HVCU,HVTU
 SG_ EMUS_DiagnosticCodes_CellVoltVal : 24|1@1+ (1,0) [0|1] ""  HVCU,HVTU
 SG_ EMUS_DiagnosticCodes_PackUnderVo : 21|1@1+ (1,0) [0|1] ""  HVCU,HVTU
 SG_ EMUS_DiagnosticCodes_NoCurrentSe : 20|1@1+ (1,0) [0|1] ""  HVCU,HVTU
 SG_ EMUS_DiagnosticCodes_CellOverHea : 19|1@1+ (1,0) [0|1] ""  HVCU,HVTU
 SG_ EMUS_DiagnosticCodes_HighTempera : 10|1@1+ (1,0) [0|1] ""  HVCU,HVTU
 SG_ EMUS_DiagnosticCodes_HighCurrent : 9|1@1+ (1,0) [0|1] ""  HVCU,HVTU
 SG_ EMUS_DiagnosticCodes_LowVoltage : 8|1@1+ (1,0) [0|1] ""  HVCU,HVTU
 SG_ EMUS_DiagnosticCodes_NoCellComm : 6|1@1+ (1,0) [0|1] ""  HVCU,HVTU
 SG_ EMUS_DiagnosticCodes_Leakage : 5|1@1+ (1,0) [0|1] ""  HVCU,HVTU
 SG_ EMUS_DiagnosticCodes_CellModOver : 4|1@1+ (1,0) [0|1] ""  HVCU,HVTU
 SG_ EMUS_DiagnosticCodes_ChrgOverCur : 3|1@1+ (1,0) [0|1] ""  HVCU,HVTU
 SG_ EMUS_DiagnosticCodes_DchrgOvrCur : 2|1@1+ (1,0) [0|1] ""  HVCU,HVTU
 SG_ EMUS_DiagnosticCodes_OverVoltage : 1|1@1+ (1,0) [0|1] ""  HVCU,HVTU
 SG_ EMUS_DiagnosticCodes_UnderVoltag : 0|1@1+ (1,0) [0|1] ""  HVCU,HVTU

BO_ 2578776066 EMUS_Cell_Mod_Temp_Overall_Param: 8 EMUS_BMS
 SG_ EMUS_CellModOverallPar_AvgCellMo : 16|8@1+ (1,-100) [-100|155] "°C"  HVTU
 SG_ EMUS_CellModOverallPar_MaxCellMo : 8|8@1+ (1,-100) [-100|155] "°C"  HVTU
 SG_ EMUS_CellModOverallPar_MinCellMo : 0|8@1+ (1,-100) [-100|155] "°C"  HVTU

BO_ 2578776072 EMUS_Cell_Temp_Overall_Params_Ex: 8 EMUS_BMS
 SG_ EMUS_CellOverallPar_AvgCellTemp : 16|8@1+ (1,-100) [-100|155] "°C"  HVTU
 SG_ EMUS_CellOverallPar_MaxCellTemp : 8|8@1+ (1,-100) [-100|155] "°C"  HVTU
 SG_ EMUS_CellOverallPar_MinCellTemp : 0|8@1+ (1,-100) [-100|155] "°C"  HVTU

BO_ 2578776067 EMUS_Cell_Balanc_Rate_Overall_Pa: 8 EMUS_BMS
 SG_ EMUS_CellBalancPar_AvgCellBalanc : 16|8@1+ (0.392156862745098,0) [0|100] "%"  HVTU
 SG_ EMUS_CellBalancPar_MaxCellBalanc : 8|8@1+ (0.392156862745098,0) [0|100] "%"  HVTU
 SG_ EMUS_CellBalancPar_MinCellBalanc : 0|8@1+ (0.392156862745098,0) [0|100] "%"  HVTU

BO_ 2578777088 EMUS_Configuration_Parameters_Ex: 8 EMUS_BMS
 SG_ EMUS_ConfigParams_Parameter_0000 : 48|8@1+ (1,0) [0|255] "" Vector__XXX
 SG_ EMUS_ConfigParams_ParamData_SecB : 40|8@1+ (1,0) [0|255] "" Vector__XXX
 SG_ EMUS_ConfigParams_ParamData_Thir : 32|8@1+ (1,0) [0|255] "" Vector__XXX
 SG_ EMUS_ConfigParams_ParameterData_ : 24|8@1+ (1,0) [0|255] "" Vector__XXX
 SG_ EMUS_ConfigParams_ParameterSize : 16|8@1+ (1,0) [0|255] "" Vector__XXX
 SG_ EMUS_ConfigParams_ParameterID_LS : 8|8@1+ (1,0) [0|255] "" Vector__XXX
 SG_ EMUS_ConfigParams_ParameterID_MS : 0|8@1+ (1,0) [0|255] "" Vector__XXX

BO_ 2578777090 EMUS_Login_Level_Ext: 8 EMUS_BMS
 SG_ EMUS_LoginLevel : 0|8@1+ (1,0) [0|255] "" Vector__XXX

BO_ 2578777089 EMUS_Contactor_Control_Ext: 1 HVCU
 SG_ EMUS_ContactorControl_ContactorS : 0|8@1+ (1,0) [0|255] ""  HVTU,EMUS_BMS

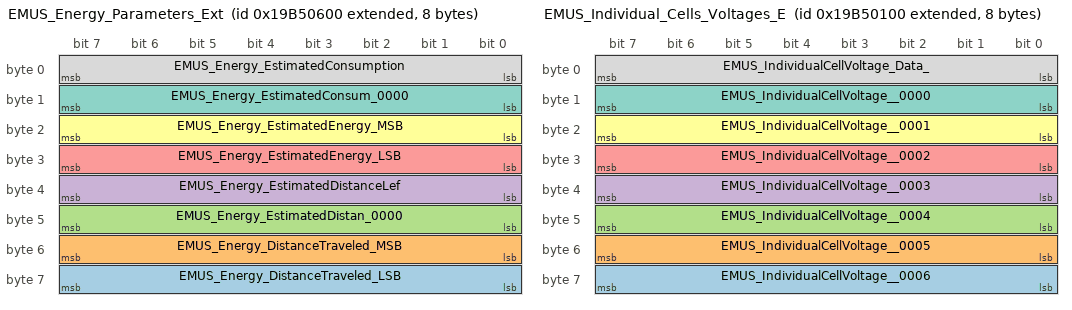
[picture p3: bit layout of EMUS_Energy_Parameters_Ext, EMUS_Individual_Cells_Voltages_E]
BO_ 2578777600 EMUS_Energy_Parameters_Ext: 8 EMUS_BMS
 SG_ EMUS_Energy_DistanceTraveled_LSB : 56|8@1+ (1,0) [0|255] "" Vector__XXX
 SG_ EMUS_Energy_DistanceTraveled_MSB : 48|8@1+ (1,0) [0|255] "" Vector__XXX
 SG_ EMUS_Energy_EstimatedDistan_0000 : 40|8@1+ (1,0) [0|255] "" Vector__XXX
 SG_ EMUS_Energy_EstimatedDistanceLef : 32|8@1+ (1,0) [0|255] "" Vector__XXX
 SG_ EMUS_Energy_EstimatedEnergy_LSB : 24|8@1+ (1,0) [0|255] "" Vector__XXX
 SG_ EMUS_Energy_EstimatedEnergy_MSB : 16|8@1+ (1,0) [0|255] "" Vector__XXX
 SG_ EMUS_Energy_EstimatedConsum_0000 : 8|8@1+ (1,0) [0|255] "" Vector__XXX
 SG_ EMUS_Energy_EstimatedConsumption : 0|8@1+ (1,0) [0|255] "" Vector__XXX

BO_ 2578777344 EMUS_State_Of_Charge_Param_Ext: 8 EMUS_BMS
 SG_ EMUS_SOCParams_EstimatedSOC : 48|8@1+ (1,0) [0|255] ""  HVTU
 SG_ EMUS_SOCParams_EstimatedCharge_L : 24|8@1+ (1,0) [0|255] ""  HVTU
 SG_ EMUS_SOCParams_EstimatedCharge_M : 16|8@1+ (1,0) [0|255] ""  HVTU
 SG_ EMUS_SOCParams_Current_LSB : 8|8@1+ (1,0) [0|255] ""  HVTU
 SG_ EMUS_SOCParams_Current_MSB : 0|8@1+ (1,0) [0|255] ""  HVTU

BO_ 2578777092 EMUS_Statistics_Ext: 8 EMUS_BMS
 SG_ EMUS_Statistics_Data_LSB : 40|8@1+ (1,0) [0|255] "" Vector__XXX
 SG_ EMUS_Statistics_Data_SecondByte : 32|8@1+ (1,0) [0|255] "" Vector__XXX
 SG_ EMUS_Statistics_Data_ThirdByte : 24|8@1+ (1,0) [0|255] "" Vector__XXX
 SG_ EMUS_Statistics_Data_MSB : 16|8@1+ (1,0) [0|255] "" Vector__XXX
 SG_ EMUS_Statistics_DataType : 8|8@1+ (1,0) [0|255] "" Vector__XXX
 SG_ EMUS_Statistics_Identifier : 0|8@1+ (1,0) [0|255] "" Vector__XXX

BO_ 2578777093 EMUS_Events_Ext: 8 EMUS_BMS
 SG_ EMUS_Events_Data_LSB : 40|8@1+ (1,0) [0|255] "" Vector__XXX
 SG_ EMUS_Events_Data_SecondByte : 32|8@1+ (1,0) [0|255] "" Vector__XXX
 SG_ EMUS_Events_Data_ThirdByte : 24|8@1+ (1,0) [0|255] "" Vector__XXX
 SG_ EMUS_Events_Data_MSB : 16|8@1+ (1,0) [0|255] "" Vector__XXX
 SG_ EMUS_Events_DataType : 8|8@1+ (1,0) [0|255] "" Vector__XXX
 SG_ EMUS_Events_EntryNumber : 0|8@1+ (1,0) [0|255] "" Vector__XXX

BO_ 2578776320 EMUS_Individual_Cells_Voltages_E: 8 EMUS_BMS
 SG_ EMUS_IndividualCellVoltage__0006 : 56|8@1+ (0.01,2) [2|4.55] "V" Vector__XXX
 SG_ EMUS_IndividualCellVoltage__0005 : 48|8@1+ (0.01,2) [2|4.55] "V" Vector__XXX
 SG_ EMUS_IndividualCellVoltage__0004 : 40|8@1+ (0.01,2) [2|4.55] "V" Vector__XXX
 SG_ EMUS_IndividualCellVoltage__0003 : 32|8@1+ (0.01,2) [2|4.55] "V" Vector__XXX
 SG_ EMUS_IndividualCellVoltage__0002 : 24|8@1+ (0.01,2) [2|4.55] "V" Vector__XXX
 SG_ EMUS_IndividualCellVoltage__0001 : 16|8@1+ (0.01,2) [2|4.55] "V" Vector__XXX
 SG_ EMUS_IndividualCellVoltage__0000 : 8|8@1+ (0.01,2) [2|4.55] "V" Vector__XXX
 SG_ EMUS_IndividualCellVoltage_Data_ : 0|8@1+ (0.01,2) [2|4.55] "V" Vector__XXX

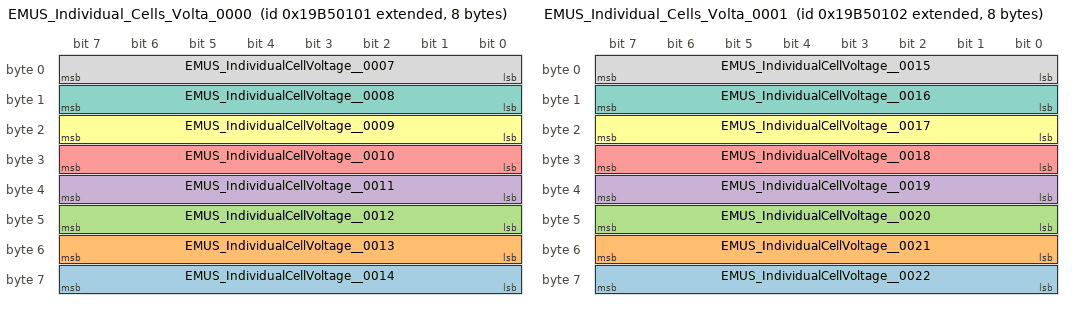
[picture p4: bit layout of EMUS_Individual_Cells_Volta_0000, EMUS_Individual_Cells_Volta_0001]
BO_ 2578776321 EMUS_Individual_Cells_Volta_0000: 8 EMUS_BMS
 SG_ EMUS_IndividualCellVoltage__0014 : 56|8@1+ (0.01,2) [2|4.55] "V" Vector__XXX
 SG_ EMUS_IndividualCellVoltage__0013 : 48|8@1+ (0.01,2) [2|4.55] "V" Vector__XXX
 SG_ EMUS_IndividualCellVoltage__0012 : 40|8@1+ (0.01,2) [2|4.55] "V" Vector__XXX
 SG_ EMUS_IndividualCellVoltage__0011 : 32|8@1+ (0.01,2) [2|4.55] "V" Vector__XXX
 SG_ EMUS_IndividualCellVoltage__0010 : 24|8@1+ (0.01,2) [2|4.55] "V" Vector__XXX
 SG_ EMUS_IndividualCellVoltage__0009 : 16|8@1+ (0.01,2) [2|4.55] "V" Vector__XXX
 SG_ EMUS_IndividualCellVoltage__0008 : 8|8@1+ (0.01,2) [2|4.55] "V" Vector__XXX
 SG_ EMUS_IndividualCellVoltage__0007 : 0|8@1+ (0.01,2) [2|4.55] "V" Vector__XXX

BO_ 2578776322 EMUS_Individual_Cells_Volta_0001: 8 EMUS_BMS
 SG_ EMUS_IndividualCellVoltage__0022 : 56|8@1+ (0.01,2) [2|4.55] "V" Vector__XXX
 SG_ EMUS_IndividualCellVoltage__0021 : 48|8@1+ (0.01,2) [2|4.55] "V" Vector__XXX
 SG_ EMUS_IndividualCellVoltage__0020 : 40|8@1+ (0.01,2) [2|4.55] "V" Vector__XXX
 SG_ EMUS_IndividualCellVoltage__0019 : 32|8@1+ (0.01,2) [2|4.55] "V" Vector__XXX
 SG_ EMUS_IndividualCellVoltage__0018 : 24|8@1+ (0.01,2) [2|4.55] "V" Vector__XXX
 SG_ EMUS_IndividualCellVoltage__0017 : 16|8@1+ (0.01,2) [2|4.55] "V" Vector__XXX
 SG_ EMUS_IndividualCellVoltage__0016 : 8|8@1+ (0.01,2) [2|4.55] "V" Vector__XXX
 SG_ EMUS_IndividualCellVoltage__0015 : 0|8@1+ (0.01,2) [2|4.55] "V" Vector__XXX

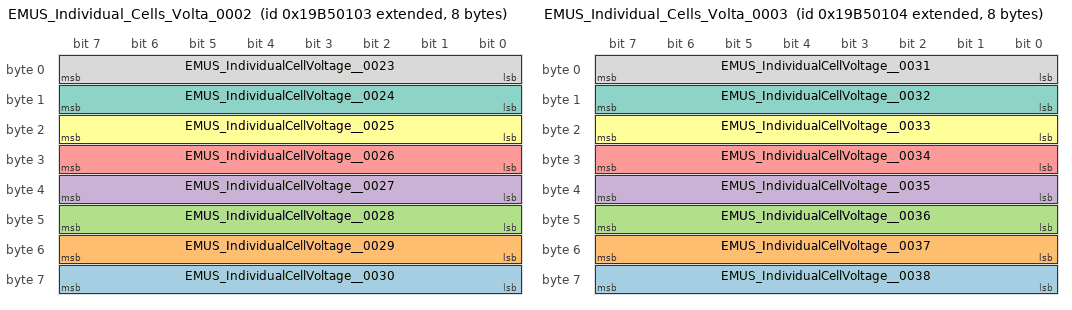
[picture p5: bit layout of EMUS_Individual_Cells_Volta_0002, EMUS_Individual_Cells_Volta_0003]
BO_ 2578776323 EMUS_Individual_Cells_Volta_0002: 8 EMUS_BMS
 SG_ EMUS_IndividualCellVoltage__0030 : 56|8@1+ (0.01,2) [2|4.55] "V" Vector__XXX
 SG_ EMUS_IndividualCellVoltage__0029 : 48|8@1+ (0.01,2) [2|4.55] "V" Vector__XXX
 SG_ EMUS_IndividualCellVoltage__0028 : 40|8@1+ (0.01,2) [2|4.55] "V" Vector__XXX
 SG_ EMUS_IndividualCellVoltage__0027 : 32|8@1+ (0.01,2) [2|4.55] "V" Vector__XXX
 SG_ EMUS_IndividualCellVoltage__0026 : 24|8@1+ (0.01,2) [2|4.55] "V" Vector__XXX
 SG_ EMUS_IndividualCellVoltage__0025 : 16|8@1+ (0.01,2) [2|4.55] "V" Vector__XXX
 SG_ EMUS_IndividualCellVoltage__0024 : 8|8@1+ (0.01,2) [2|4.55] "V" Vector__XXX
 SG_ EMUS_IndividualCellVoltage__0023 : 0|8@1+ (0.01,2) [2|4.55] "V" Vector__XXX

BO_ 2578776324 EMUS_Individual_Cells_Volta_0003: 8 EMUS_BMS
 SG_ EMUS_IndividualCellVoltage__0038 : 56|8@1+ (0.01,2) [2|4.55] "V" Vector__XXX
 SG_ EMUS_IndividualCellVoltage__0037 : 48|8@1+ (0.01,2) [2|4.55] "V" Vector__XXX
 SG_ EMUS_IndividualCellVoltage__0036 : 40|8@1+ (0.01,2) [2|4.55] "V" Vector__XXX
 SG_ EMUS_IndividualCellVoltage__0035 : 32|8@1+ (0.01,2) [2|4.55] "V" Vector__XXX
 SG_ EMUS_IndividualCellVoltage__0034 : 24|8@1+ (0.01,2) [2|4.55] "V" Vector__XXX
 SG_ EMUS_IndividualCellVoltage__0033 : 16|8@1+ (0.01,2) [2|4.55] "V" Vector__XXX
 SG_ EMUS_IndividualCellVoltage__0032 : 8|8@1+ (0.01,2) [2|4.55] "V" Vector__XXX
 SG_ EMUS_IndividualCellVoltage__0031 : 0|8@1+ (0.01,2) [2|4.55] "V" Vector__XXX

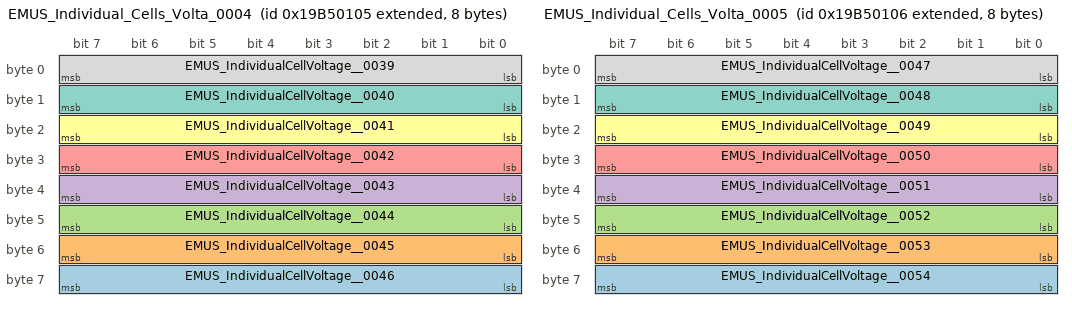
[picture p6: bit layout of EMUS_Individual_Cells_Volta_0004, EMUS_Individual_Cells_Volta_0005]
BO_ 2578776325 EMUS_Individual_Cells_Volta_0004: 8 EMUS_BMS
 SG_ EMUS_IndividualCellVoltage__0046 : 56|8@1+ (0.01,2) [2|4.55] "V" Vector__XXX
 SG_ EMUS_IndividualCellVoltage__0045 : 48|8@1+ (0.01,2) [2|4.55] "V" Vector__XXX
 SG_ EMUS_IndividualCellVoltage__0044 : 40|8@1+ (0.01,2) [2|4.55] "V" Vector__XXX
 SG_ EMUS_IndividualCellVoltage__0043 : 32|8@1+ (0.01,2) [2|4.55] "V" Vector__XXX
 SG_ EMUS_IndividualCellVoltage__0042 : 24|8@1+ (0.01,2) [2|4.55] "V" Vector__XXX
 SG_ EMUS_IndividualCellVoltage__0041 : 16|8@1+ (0.01,2) [2|4.55] "V" Vector__XXX
 SG_ EMUS_IndividualCellVoltage__0040 : 8|8@1+ (0.01,2) [2|4.55] "V" Vector__XXX
 SG_ EMUS_IndividualCellVoltage__0039 : 0|8@1+ (0.01,2) [2|4.55] "V" Vector__XXX

BO_ 2578776326 EMUS_Individual_Cells_Volta_0005: 8 EMUS_BMS
 SG_ EMUS_IndividualCellVoltage__0054 : 56|8@1+ (0.01,2) [2|4.55] "V" Vector__XXX
 SG_ EMUS_IndividualCellVoltage__0053 : 48|8@1+ (0.01,2) [2|4.55] "V" Vector__XXX
 SG_ EMUS_IndividualCellVoltage__0052 : 40|8@1+ (0.01,2) [2|4.55] "V" Vector__XXX
 SG_ EMUS_IndividualCellVoltage__0051 : 32|8@1+ (0.01,2) [2|4.55] "V" Vector__XXX
 SG_ EMUS_IndividualCellVoltage__0050 : 24|8@1+ (0.01,2) [2|4.55] "V" Vector__XXX
 SG_ EMUS_IndividualCellVoltage__0049 : 16|8@1+ (0.01,2) [2|4.55] "V" Vector__XXX
 SG_ EMUS_IndividualCellVoltage__0048 : 8|8@1+ (0.01,2) [2|4.55] "V" Vector__XXX
 SG_ EMUS_IndividualCellVoltage__0047 : 0|8@1+ (0.01,2) [2|4.55] "V" Vector__XXX

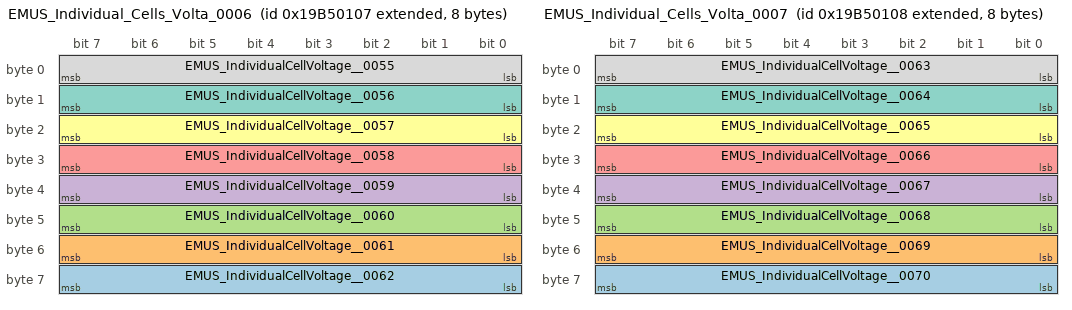
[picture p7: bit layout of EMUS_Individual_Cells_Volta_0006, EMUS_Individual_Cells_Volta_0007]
BO_ 2578776327 EMUS_Individual_Cells_Volta_0006: 8 EMUS_BMS
 SG_ EMUS_IndividualCellVoltage__0062 : 56|8@1+ (0.01,2) [2|4.55] "V" Vector__XXX
 SG_ EMUS_IndividualCellVoltage__0061 : 48|8@1+ (0.01,2) [2|4.55] "V" Vector__XXX
 SG_ EMUS_IndividualCellVoltage__0060 : 40|8@1+ (0.01,2) [2|4.55] "V" Vector__XXX
 SG_ EMUS_IndividualCellVoltage__0059 : 32|8@1+ (0.01,2) [2|4.55] "V" Vector__XXX
 SG_ EMUS_IndividualCellVoltage__0058 : 24|8@1+ (0.01,2) [2|4.55] "V" Vector__XXX
 SG_ EMUS_IndividualCellVoltage__0057 : 16|8@1+ (0.01,2) [2|4.55] "V" Vector__XXX
 SG_ EMUS_IndividualCellVoltage__0056 : 8|8@1+ (0.01,2) [2|4.55] "V" Vector__XXX
 SG_ EMUS_IndividualCellVoltage__0055 : 0|8@1+ (0.01,2) [2|4.55] "V" Vector__XXX

BO_ 2578776328 EMUS_Individual_Cells_Volta_0007: 8 EMUS_BMS
 SG_ EMUS_IndividualCellVoltage__0070 : 56|8@1+ (0.01,2) [2|4.55] "V" Vector__XXX
 SG_ EMUS_IndividualCellVoltage__0069 : 48|8@1+ (0.01,2) [2|4.55] "V" Vector__XXX
 SG_ EMUS_IndividualCellVoltage__0068 : 40|8@1+ (0.01,2) [2|4.55] "V" Vector__XXX
 SG_ EMUS_IndividualCellVoltage__0067 : 32|8@1+ (0.01,2) [2|4.55] "V" Vector__XXX
 SG_ EMUS_IndividualCellVoltage__0066 : 24|8@1+ (0.01,2) [2|4.55] "V" Vector__XXX
 SG_ EMUS_IndividualCellVoltage__0065 : 16|8@1+ (0.01,2) [2|4.55] "V" Vector__XXX
 SG_ EMUS_IndividualCellVoltage__0064 : 8|8@1+ (0.01,2) [2|4.55] "V" Vector__XXX
 SG_ EMUS_IndividualCellVoltage__0063 : 0|8@1+ (0.01,2) [2|4.55] "V" Vector__XXX

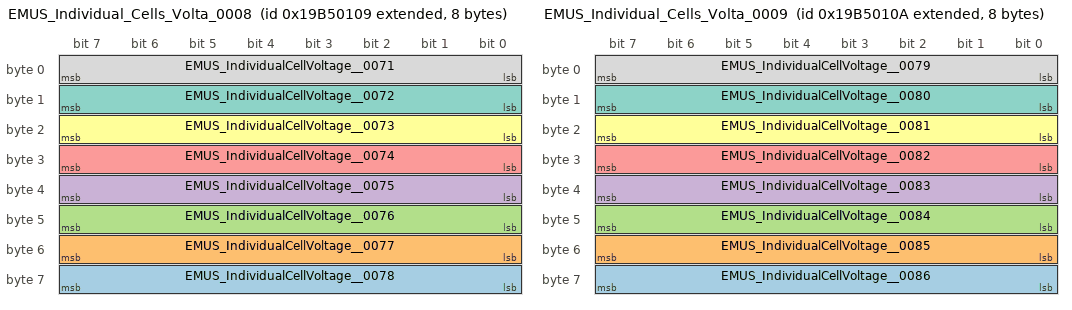
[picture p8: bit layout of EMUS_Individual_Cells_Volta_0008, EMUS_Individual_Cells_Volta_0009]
BO_ 2578776329 EMUS_Individual_Cells_Volta_0008: 8 EMUS_BMS
 SG_ EMUS_IndividualCellVoltage__0078 : 56|8@1+ (0.01,2) [2|4.55] "V" Vector__XXX
 SG_ EMUS_IndividualCellVoltage__0077 : 48|8@1+ (0.01,2) [2|4.55] "V" Vector__XXX
 SG_ EMUS_IndividualCellVoltage__0076 : 40|8@1+ (0.01,2) [2|4.55] "V" Vector__XXX
 SG_ EMUS_IndividualCellVoltage__0075 : 32|8@1+ (0.01,2) [2|4.55] "V" Vector__XXX
 SG_ EMUS_IndividualCellVoltage__0074 : 24|8@1+ (0.01,2) [2|4.55] "V" Vector__XXX
 SG_ EMUS_IndividualCellVoltage__0073 : 16|8@1+ (0.01,2) [2|4.55] "V" Vector__XXX
 SG_ EMUS_IndividualCellVoltage__0072 : 8|8@1+ (0.01,2) [2|4.55] "V" Vector__XXX
 SG_ EMUS_IndividualCellVoltage__0071 : 0|8@1+ (0.01,2) [2|4.55] "V" Vector__XXX

BO_ 2578776330 EMUS_Individual_Cells_Volta_0009: 8 EMUS_BMS
 SG_ EMUS_IndividualCellVoltage__0086 : 56|8@1+ (0.01,2) [2|4.55] "V" Vector__XXX
 SG_ EMUS_IndividualCellVoltage__0085 : 48|8@1+ (0.01,2) [2|4.55] "V" Vector__XXX
 SG_ EMUS_IndividualCellVoltage__0084 : 40|8@1+ (0.01,2) [2|4.55] "V" Vector__XXX
 SG_ EMUS_IndividualCellVoltage__0083 : 32|8@1+ (0.01,2) [2|4.55] "V" Vector__XXX
 SG_ EMUS_IndividualCellVoltage__0082 : 24|8@1+ (0.01,2) [2|4.55] "V" Vector__XXX
 SG_ EMUS_IndividualCellVoltage__0081 : 16|8@1+ (0.01,2) [2|4.55] "V" Vector__XXX
 SG_ EMUS_IndividualCellVoltage__0080 : 8|8@1+ (0.01,2) [2|4.55] "V" Vector__XXX
 SG_ EMUS_IndividualCellVoltage__0079 : 0|8@1+ (0.01,2) [2|4.55] "V" Vector__XXX

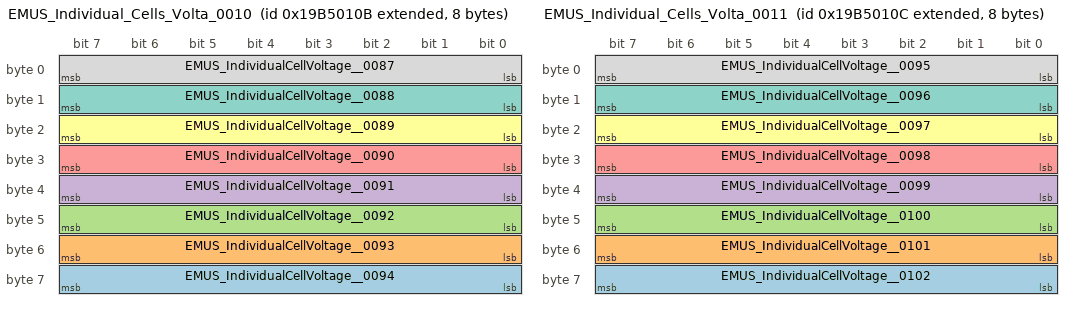
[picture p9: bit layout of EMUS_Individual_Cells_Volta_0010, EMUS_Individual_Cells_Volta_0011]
BO_ 2578776331 EMUS_Individual_Cells_Volta_0010: 8 EMUS_BMS
 SG_ EMUS_IndividualCellVoltage__0094 : 56|8@1+ (0.01,2) [2|4.55] "V" Vector__XXX
 SG_ EMUS_IndividualCellVoltage__0093 : 48|8@1+ (0.01,2) [2|4.55] "V" Vector__XXX
 SG_ EMUS_IndividualCellVoltage__0092 : 40|8@1+ (0.01,2) [2|4.55] "V" Vector__XXX
 SG_ EMUS_IndividualCellVoltage__0091 : 32|8@1+ (0.01,2) [2|4.55] "V" Vector__XXX
 SG_ EMUS_IndividualCellVoltage__0090 : 24|8@1+ (0.01,2) [2|4.55] "V" Vector__XXX
 SG_ EMUS_IndividualCellVoltage__0089 : 16|8@1+ (0.01,2) [2|4.55] "V" Vector__XXX
 SG_ EMUS_IndividualCellVoltage__0088 : 8|8@1+ (0.01,2) [2|4.55] "V" Vector__XXX
 SG_ EMUS_IndividualCellVoltage__0087 : 0|8@1+ (0.01,2) [2|4.55] "V" Vector__XXX

BO_ 2578776332 EMUS_Individual_Cells_Volta_0011: 8 EMUS_BMS
 SG_ EMUS_IndividualCellVoltage__0102 : 56|8@1+ (0.01,2) [2|4.55] "V" Vector__XXX
 SG_ EMUS_IndividualCellVoltage__0101 : 48|8@1+ (0.01,2) [2|4.55] "V" Vector__XXX
 SG_ EMUS_IndividualCellVoltage__0100 : 40|8@1+ (0.01,2) [2|4.55] "V" Vector__XXX
 SG_ EMUS_IndividualCellVoltage__0099 : 32|8@1+ (0.01,2) [2|4.55] "V" Vector__XXX
 SG_ EMUS_IndividualCellVoltage__0098 : 24|8@1+ (0.01,2) [2|4.55] "V" Vector__XXX
 SG_ EMUS_IndividualCellVoltage__0097 : 16|8@1+ (0.01,2) [2|4.55] "V" Vector__XXX
 SG_ EMUS_IndividualCellVoltage__0096 : 8|8@1+ (0.01,2) [2|4.55] "V" Vector__XXX
 SG_ EMUS_IndividualCellVoltage__0095 : 0|8@1+ (0.01,2) [2|4.55] "V" Vector__XXX

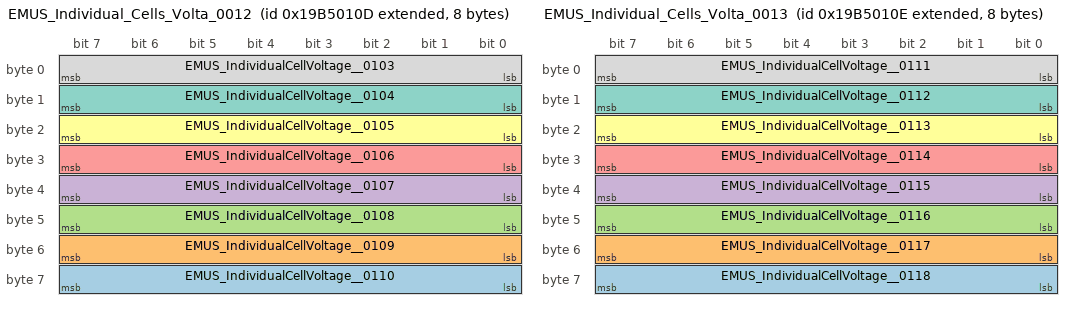
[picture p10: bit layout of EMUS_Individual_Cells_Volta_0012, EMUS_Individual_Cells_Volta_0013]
BO_ 2578776333 EMUS_Individual_Cells_Volta_0012: 8 EMUS_BMS
 SG_ EMUS_IndividualCellVoltage__0110 : 56|8@1+ (0.01,2) [2|4.55] "V" Vector__XXX
 SG_ EMUS_IndividualCellVoltage__0109 : 48|8@1+ (0.01,2) [2|4.55] "V" Vector__XXX
 SG_ EMUS_IndividualCellVoltage__0108 : 40|8@1+ (0.01,2) [2|4.55] "V" Vector__XXX
 SG_ EMUS_IndividualCellVoltage__0107 : 32|8@1+ (0.01,2) [2|4.55] "V" Vector__XXX
 SG_ EMUS_IndividualCellVoltage__0106 : 24|8@1+ (0.01,2) [2|4.55] "V" Vector__XXX
 SG_ EMUS_IndividualCellVoltage__0105 : 16|8@1+ (0.01,2) [2|4.55] "V" Vector__XXX
 SG_ EMUS_IndividualCellVoltage__0104 : 8|8@1+ (0.01,2) [2|4.55] "V" Vector__XXX
 SG_ EMUS_IndividualCellVoltage__0103 : 0|8@1+ (0.01,2) [2|4.55] "V" Vector__XXX

BO_ 2578776334 EMUS_Individual_Cells_Volta_0013: 8 EMUS_BMS
 SG_ EMUS_IndividualCellVoltage__0118 : 56|8@1+ (0.01,2) [2|4.55] "V" Vector__XXX
 SG_ EMUS_IndividualCellVoltage__0117 : 48|8@1+ (0.01,2) [2|4.55] "V" Vector__XXX
 SG_ EMUS_IndividualCellVoltage__0116 : 40|8@1+ (0.01,2) [2|4.55] "V" Vector__XXX
 SG_ EMUS_IndividualCellVoltage__0115 : 32|8@1+ (0.01,2) [2|4.55] "V" Vector__XXX
 SG_ EMUS_IndividualCellVoltage__0114 : 24|8@1+ (0.01,2) [2|4.55] "V" Vector__XXX
 SG_ EMUS_IndividualCellVoltage__0113 : 16|8@1+ (0.01,2) [2|4.55] "V" Vector__XXX
 SG_ EMUS_IndividualCellVoltage__0112 : 8|8@1+ (0.01,2) [2|4.55] "V" Vector__XXX
 SG_ EMUS_IndividualCellVoltage__0111 : 0|8@1+ (0.01,2) [2|4.55] "V" Vector__XXX

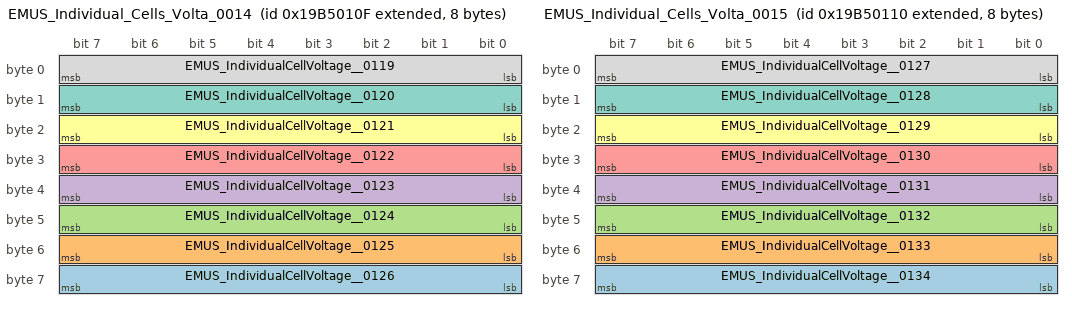
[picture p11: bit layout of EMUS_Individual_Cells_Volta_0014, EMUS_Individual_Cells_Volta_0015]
BO_ 2578776335 EMUS_Individual_Cells_Volta_0014: 8 EMUS_BMS
 SG_ EMUS_IndividualCellVoltage__0126 : 56|8@1+ (0.01,2) [2|4.55] "V" Vector__XXX
 SG_ EMUS_IndividualCellVoltage__0125 : 48|8@1+ (0.01,2) [2|4.55] "V" Vector__XXX
 SG_ EMUS_IndividualCellVoltage__0124 : 40|8@1+ (0.01,2) [2|4.55] "V" Vector__XXX
 SG_ EMUS_IndividualCellVoltage__0123 : 32|8@1+ (0.01,2) [2|4.55] "V" Vector__XXX
 SG_ EMUS_IndividualCellVoltage__0122 : 24|8@1+ (0.01,2) [2|4.55] "V" Vector__XXX
 SG_ EMUS_IndividualCellVoltage__0121 : 16|8@1+ (0.01,2) [2|4.55] "V" Vector__XXX
 SG_ EMUS_IndividualCellVoltage__0120 : 8|8@1+ (0.01,2) [2|4.55] "V" Vector__XXX
 SG_ EMUS_IndividualCellVoltage__0119 : 0|8@1+ (0.01,2) [2|4.55] "V" Vector__XXX

BO_ 2578776336 EMUS_Individual_Cells_Volta_0015: 8 EMUS_BMS
 SG_ EMUS_IndividualCellVoltage__0134 : 56|8@1+ (0.01,2) [2|4.55] "V" Vector__XXX
 SG_ EMUS_IndividualCellVoltage__0133 : 48|8@1+ (0.01,2) [2|4.55] "V" Vector__XXX
 SG_ EMUS_IndividualCellVoltage__0132 : 40|8@1+ (0.01,2) [2|4.55] "V" Vector__XXX
 SG_ EMUS_IndividualCellVoltage__0131 : 32|8@1+ (0.01,2) [2|4.55] "V" Vector__XXX
 SG_ EMUS_IndividualCellVoltage__0130 : 24|8@1+ (0.01,2) [2|4.55] "V" Vector__XXX
 SG_ EMUS_IndividualCellVoltage__0129 : 16|8@1+ (0.01,2) [2|4.55] "V" Vector__XXX
 SG_ EMUS_IndividualCellVoltage__0128 : 8|8@1+ (0.01,2) [2|4.55] "V" Vector__XXX
 SG_ EMUS_IndividualCellVoltage__0127 : 0|8@1+ (0.01,2) [2|4.55] "V" Vector__XXX

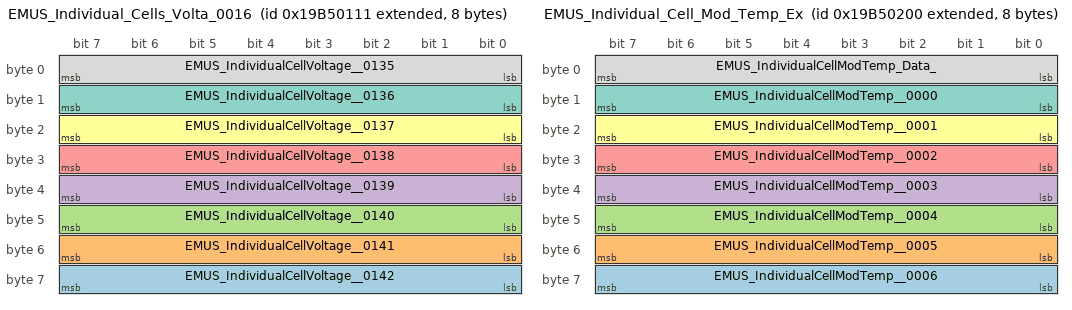
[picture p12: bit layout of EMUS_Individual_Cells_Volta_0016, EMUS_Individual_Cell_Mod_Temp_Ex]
BO_ 2578776337 EMUS_Individual_Cells_Volta_0016: 8 EMUS_BMS
 SG_ EMUS_IndividualCellVoltage__0142 : 56|8@1+ (0.01,2) [2|4.55] "V" Vector__XXX
 SG_ EMUS_IndividualCellVoltage__0141 : 48|8@1+ (0.01,2) [2|4.55] "V" Vector__XXX
 SG_ EMUS_IndividualCellVoltage__0140 : 40|8@1+ (0.01,2) [2|4.55] "V" Vector__XXX
 SG_ EMUS_IndividualCellVoltage__0139 : 32|8@1+ (0.01,2) [2|4.55] "V" Vector__XXX
 SG_ EMUS_IndividualCellVoltage__0138 : 24|8@1+ (0.01,2) [2|4.55] "V" Vector__XXX
 SG_ EMUS_IndividualCellVoltage__0137 : 16|8@1+ (0.01,2) [2|4.55] "V" Vector__XXX
 SG_ EMUS_IndividualCellVoltage__0136 : 8|8@1+ (0.01,2) [2|4.55] "V" Vector__XXX
 SG_ EMUS_IndividualCellVoltage__0135 : 0|8@1+ (0.01,2) [2|4.55] "V" Vector__XXX

BO_ 2578776576 EMUS_Individual_Cell_Mod_Temp_Ex: 8 EMUS_BMS
 SG_ EMUS_IndividualCellModTemp__0006 : 56|8@1+ (1,-100) [-100|155] "%" Vector__XXX
 SG_ EMUS_IndividualCellModTemp__0005 : 48|8@1+ (1,-100) [-100|155] "%" Vector__XXX
 SG_ EMUS_IndividualCellModTemp__0004 : 40|8@1+ (1,-100) [-100|155] "%" Vector__XXX
 SG_ EMUS_IndividualCellModTemp__0003 : 32|8@1+ (1,-100) [-100|155] "%" Vector__XXX
 SG_ EMUS_IndividualCellModTemp__0002 : 24|8@1+ (1,-100) [-100|155] "%" Vector__XXX
 SG_ EMUS_IndividualCellModTemp__0001 : 16|8@1+ (1,-100) [-100|155] "%" Vector__XXX
 SG_ EMUS_IndividualCellModTemp__0000 : 8|8@1+ (1,-100) [-100|155] "%" Vector__XXX
 SG_ EMUS_IndividualCellModTemp_Data_ : 0|8@1+ (1,-100) [-100|155] "%" Vector__XXX

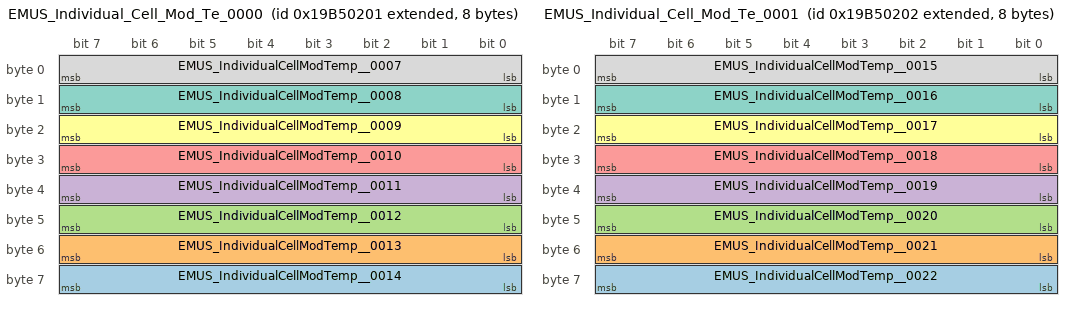
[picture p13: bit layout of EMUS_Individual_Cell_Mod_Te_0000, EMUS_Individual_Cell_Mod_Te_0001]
BO_ 2578776577 EMUS_Individual_Cell_Mod_Te_0000: 8 EMUS_BMS
 SG_ EMUS_IndividualCellModTemp__0014 : 56|8@1+ (1,-100) [-100|155] "%" Vector__XXX
 SG_ EMUS_IndividualCellModTemp__0013 : 48|8@1+ (1,-100) [-100|155] "%" Vector__XXX
 SG_ EMUS_IndividualCellModTemp__0012 : 40|8@1+ (1,-100) [-100|155] "%" Vector__XXX
 SG_ EMUS_IndividualCellModTemp__0011 : 32|8@1+ (1,-100) [-100|155] "%" Vector__XXX
 SG_ EMUS_IndividualCellModTemp__0010 : 24|8@1+ (1,-100) [-100|155] "%" Vector__XXX
 SG_ EMUS_IndividualCellModTemp__0009 : 16|8@1+ (1,-100) [-100|155] "%" Vector__XXX
 SG_ EMUS_IndividualCellModTemp__0008 : 8|8@1+ (1,-100) [-100|155] "%" Vector__XXX
 SG_ EMUS_IndividualCellModTemp__0007 : 0|8@1+ (1,-100) [-100|155] "%" Vector__XXX

BO_ 2578776578 EMUS_Individual_Cell_Mod_Te_0001: 8 EMUS_BMS
 SG_ EMUS_IndividualCellModTemp__0022 : 56|8@1+ (1,-100) [-100|155] "%" Vector__XXX
 SG_ EMUS_IndividualCellModTemp__0021 : 48|8@1+ (1,-100) [-100|155] "%" Vector__XXX
 SG_ EMUS_IndividualCellModTemp__0020 : 40|8@1+ (1,-100) [-100|155] "%" Vector__XXX
 SG_ EMUS_IndividualCellModTemp__0019 : 32|8@1+ (1,-100) [-100|155] "%" Vector__XXX
 SG_ EMUS_IndividualCellModTemp__0018 : 24|8@1+ (1,-100) [-100|155] "%" Vector__XXX
 SG_ EMUS_IndividualCellModTemp__0017 : 16|8@1+ (1,-100) [-100|155] "%" Vector__XXX
 SG_ EMUS_IndividualCellModTemp__0016 : 8|8@1+ (1,-100) [-100|155] "%" Vector__XXX
 SG_ EMUS_IndividualCellModTemp__0015 : 0|8@1+ (1,-100) [-100|155] "%" Vector__XXX

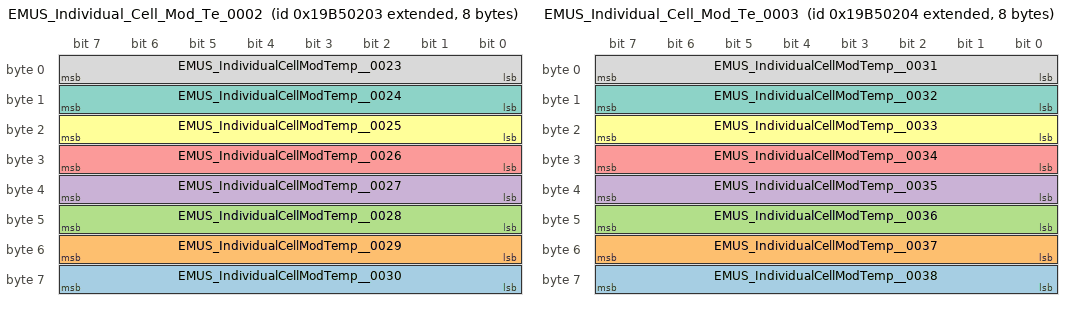
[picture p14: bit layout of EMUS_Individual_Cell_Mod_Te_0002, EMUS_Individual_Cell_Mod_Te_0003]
BO_ 2578776579 EMUS_Individual_Cell_Mod_Te_0002: 8 EMUS_BMS
 SG_ EMUS_IndividualCellModTemp__0030 : 56|8@1+ (1,-100) [-100|155] "%" Vector__XXX
 SG_ EMUS_IndividualCellModTemp__0029 : 48|8@1+ (1,-100) [-100|155] "%" Vector__XXX
 SG_ EMUS_IndividualCellModTemp__0028 : 40|8@1+ (1,-100) [-100|155] "%" Vector__XXX
 SG_ EMUS_IndividualCellModTemp__0027 : 32|8@1+ (1,-100) [-100|155] "%" Vector__XXX
 SG_ EMUS_IndividualCellModTemp__0026 : 24|8@1+ (1,-100) [-100|155] "%" Vector__XXX
 SG_ EMUS_IndividualCellModTemp__0025 : 16|8@1+ (1,-100) [-100|155] "%" Vector__XXX
 SG_ EMUS_IndividualCellModTemp__0024 : 8|8@1+ (1,-100) [-100|155] "%" Vector__XXX
 SG_ EMUS_IndividualCellModTemp__0023 : 0|8@1+ (1,-100) [-100|155] "%" Vector__XXX

BO_ 2578776580 EMUS_Individual_Cell_Mod_Te_0003: 8 EMUS_BMS
 SG_ EMUS_IndividualCellModTemp__0038 : 56|8@1+ (1,-100) [-100|155] "%" Vector__XXX
 SG_ EMUS_IndividualCellModTemp__0037 : 48|8@1+ (1,-100) [-100|155] "%" Vector__XXX
 SG_ EMUS_IndividualCellModTemp__0036 : 40|8@1+ (1,-100) [-100|155] "%" Vector__XXX
 SG_ EMUS_IndividualCellModTemp__0035 : 32|8@1+ (1,-100) [-100|155] "%" Vector__XXX
 SG_ EMUS_IndividualCellModTemp__0034 : 24|8@1+ (1,-100) [-100|155] "%" Vector__XXX
 SG_ EMUS_IndividualCellModTemp__0033 : 16|8@1+ (1,-100) [-100|155] "%" Vector__XXX
 SG_ EMUS_IndividualCellModTemp__0032 : 8|8@1+ (1,-100) [-100|155] "%" Vector__XXX
 SG_ EMUS_IndividualCellModTemp__0031 : 0|8@1+ (1,-100) [-100|155] "%" Vector__XXX

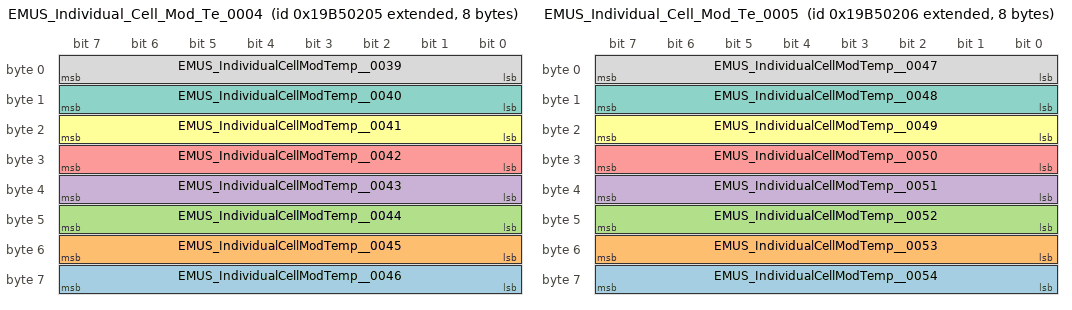
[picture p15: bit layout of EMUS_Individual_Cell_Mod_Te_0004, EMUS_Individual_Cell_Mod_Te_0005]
BO_ 2578776581 EMUS_Individual_Cell_Mod_Te_0004: 8 EMUS_BMS
 SG_ EMUS_IndividualCellModTemp__0046 : 56|8@1+ (1,-100) [-100|155] "%" Vector__XXX
 SG_ EMUS_IndividualCellModTemp__0045 : 48|8@1+ (1,-100) [-100|155] "%" Vector__XXX
 SG_ EMUS_IndividualCellModTemp__0044 : 40|8@1+ (1,-100) [-100|155] "%" Vector__XXX
 SG_ EMUS_IndividualCellModTemp__0043 : 32|8@1+ (1,-100) [-100|155] "%" Vector__XXX
 SG_ EMUS_IndividualCellModTemp__0042 : 24|8@1+ (1,-100) [-100|155] "%" Vector__XXX
 SG_ EMUS_IndividualCellModTemp__0041 : 16|8@1+ (1,-100) [-100|155] "%" Vector__XXX
 SG_ EMUS_IndividualCellModTemp__0040 : 8|8@1+ (1,-100) [-100|155] "%" Vector__XXX
 SG_ EMUS_IndividualCellModTemp__0039 : 0|8@1+ (1,-100) [-100|155] "%" Vector__XXX

BO_ 2578776582 EMUS_Individual_Cell_Mod_Te_0005: 8 EMUS_BMS
 SG_ EMUS_IndividualCellModTemp__0054 : 56|8@1+ (1,-100) [-100|155] "%" Vector__XXX
 SG_ EMUS_IndividualCellModTemp__0053 : 48|8@1+ (1,-100) [-100|155] "%" Vector__XXX
 SG_ EMUS_IndividualCellModTemp__0052 : 40|8@1+ (1,-100) [-100|155] "%" Vector__XXX
 SG_ EMUS_IndividualCellModTemp__0051 : 32|8@1+ (1,-100) [-100|155] "%" Vector__XXX
 SG_ EMUS_IndividualCellModTemp__0050 : 24|8@1+ (1,-100) [-100|155] "%" Vector__XXX
 SG_ EMUS_IndividualCellModTemp__0049 : 16|8@1+ (1,-100) [-100|155] "%" Vector__XXX
 SG_ EMUS_IndividualCellModTemp__0048 : 8|8@1+ (1,-100) [-100|155] "%" Vector__XXX
 SG_ EMUS_IndividualCellModTemp__0047 : 0|8@1+ (1,-100) [-100|155] "%" Vector__XXX

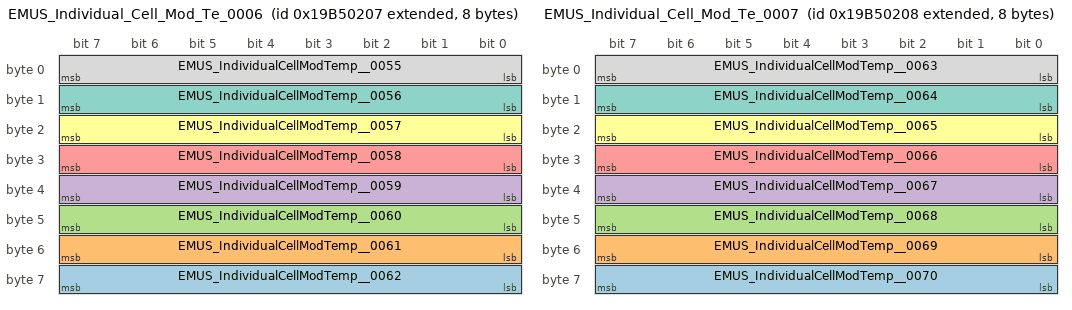
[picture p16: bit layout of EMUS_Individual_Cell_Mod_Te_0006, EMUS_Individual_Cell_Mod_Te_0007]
BO_ 2578776583 EMUS_Individual_Cell_Mod_Te_0006: 8 EMUS_BMS
 SG_ EMUS_IndividualCellModTemp__0062 : 56|8@1+ (1,-100) [-100|155] "%" Vector__XXX
 SG_ EMUS_IndividualCellModTemp__0061 : 48|8@1+ (1,-100) [-100|155] "%" Vector__XXX
 SG_ EMUS_IndividualCellModTemp__0060 : 40|8@1+ (1,-100) [-100|155] "%" Vector__XXX
 SG_ EMUS_IndividualCellModTemp__0059 : 32|8@1+ (1,-100) [-100|155] "%" Vector__XXX
 SG_ EMUS_IndividualCellModTemp__0058 : 24|8@1+ (1,-100) [-100|155] "%" Vector__XXX
 SG_ EMUS_IndividualCellModTemp__0057 : 16|8@1+ (1,-100) [-100|155] "%" Vector__XXX
 SG_ EMUS_IndividualCellModTemp__0056 : 8|8@1+ (1,-100) [-100|155] "%" Vector__XXX
 SG_ EMUS_IndividualCellModTemp__0055 : 0|8@1+ (1,-100) [-100|155] "%" Vector__XXX

BO_ 2578776584 EMUS_Individual_Cell_Mod_Te_0007: 8 EMUS_BMS
 SG_ EMUS_IndividualCellModTemp__0070 : 56|8@1+ (1,-100) [-100|155] "%" Vector__XXX
 SG_ EMUS_IndividualCellModTemp__0069 : 48|8@1+ (1,-100) [-100|155] "%" Vector__XXX
 SG_ EMUS_IndividualCellModTemp__0068 : 40|8@1+ (1,-100) [-100|155] "%" Vector__XXX
 SG_ EMUS_IndividualCellModTemp__0067 : 32|8@1+ (1,-100) [-100|155] "%" Vector__XXX
 SG_ EMUS_IndividualCellModTemp__0066 : 24|8@1+ (1,-100) [-100|155] "%" Vector__XXX
 SG_ EMUS_IndividualCellModTemp__0065 : 16|8@1+ (1,-100) [-100|155] "%" Vector__XXX
 SG_ EMUS_IndividualCellModTemp__0064 : 8|8@1+ (1,-100) [-100|155] "%" Vector__XXX
 SG_ EMUS_IndividualCellModTemp__0063 : 0|8@1+ (1,-100) [-100|155] "%" Vector__XXX

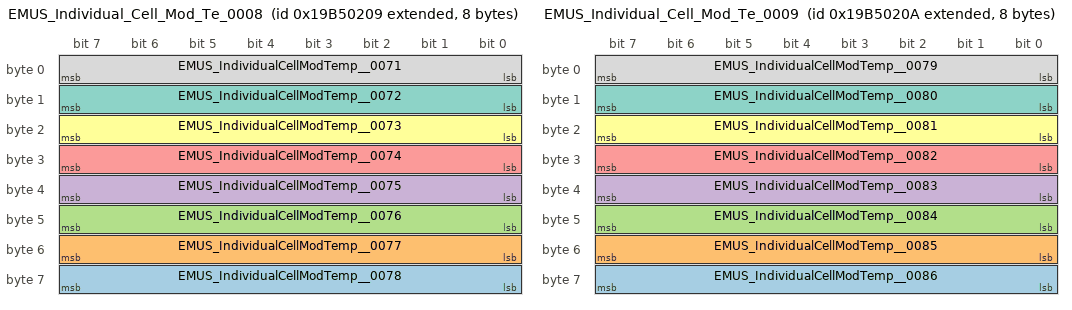
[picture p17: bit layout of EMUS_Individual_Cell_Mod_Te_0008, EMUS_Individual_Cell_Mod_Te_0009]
BO_ 2578776585 EMUS_Individual_Cell_Mod_Te_0008: 8 EMUS_BMS
 SG_ EMUS_IndividualCellModTemp__0078 : 56|8@1+ (1,-100) [-100|155] "%" Vector__XXX
 SG_ EMUS_IndividualCellModTemp__0077 : 48|8@1+ (1,-100) [-100|155] "%" Vector__XXX
 SG_ EMUS_IndividualCellModTemp__0076 : 40|8@1+ (1,-100) [-100|155] "%" Vector__XXX
 SG_ EMUS_IndividualCellModTemp__0075 : 32|8@1+ (1,-100) [-100|155] "%" Vector__XXX
 SG_ EMUS_IndividualCellModTemp__0074 : 24|8@1+ (1,-100) [-100|155] "%" Vector__XXX
 SG_ EMUS_IndividualCellModTemp__0073 : 16|8@1+ (1,-100) [-100|155] "%" Vector__XXX
 SG_ EMUS_IndividualCellModTemp__0072 : 8|8@1+ (1,-100) [-100|155] "%" Vector__XXX
 SG_ EMUS_IndividualCellModTemp__0071 : 0|8@1+ (1,-100) [-100|155] "%" Vector__XXX

BO_ 2578776586 EMUS_Individual_Cell_Mod_Te_0009: 8 EMUS_BMS
 SG_ EMUS_IndividualCellModTemp__0086 : 56|8@1+ (1,-100) [-100|155] "%" Vector__XXX
 SG_ EMUS_IndividualCellModTemp__0085 : 48|8@1+ (1,-100) [-100|155] "%" Vector__XXX
 SG_ EMUS_IndividualCellModTemp__0084 : 40|8@1+ (1,-100) [-100|155] "%" Vector__XXX
 SG_ EMUS_IndividualCellModTemp__0083 : 32|8@1+ (1,-100) [-100|155] "%" Vector__XXX
 SG_ EMUS_IndividualCellModTemp__0082 : 24|8@1+ (1,-100) [-100|155] "%" Vector__XXX
 SG_ EMUS_IndividualCellModTemp__0081 : 16|8@1+ (1,-100) [-100|155] "%" Vector__XXX
 SG_ EMUS_IndividualCellModTemp__0080 : 8|8@1+ (1,-100) [-100|155] "%" Vector__XXX
 SG_ EMUS_IndividualCellModTemp__0079 : 0|8@1+ (1,-100) [-100|155] "%" Vector__XXX

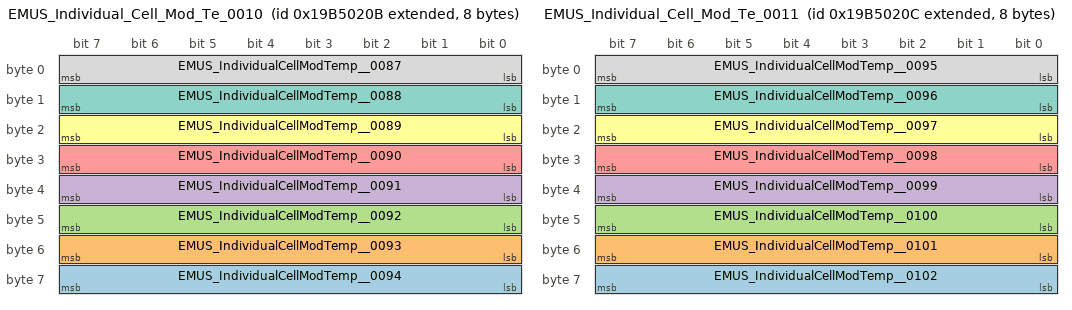
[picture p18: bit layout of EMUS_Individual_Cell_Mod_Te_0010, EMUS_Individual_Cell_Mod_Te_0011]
BO_ 2578776587 EMUS_Individual_Cell_Mod_Te_0010: 8 EMUS_BMS
 SG_ EMUS_IndividualCellModTemp__0094 : 56|8@1+ (1,-100) [-100|155] "%" Vector__XXX
 SG_ EMUS_IndividualCellModTemp__0093 : 48|8@1+ (1,-100) [-100|155] "%" Vector__XXX
 SG_ EMUS_IndividualCellModTemp__0092 : 40|8@1+ (1,-100) [-100|155] "%" Vector__XXX
 SG_ EMUS_IndividualCellModTemp__0091 : 32|8@1+ (1,-100) [-100|155] "%" Vector__XXX
 SG_ EMUS_IndividualCellModTemp__0090 : 24|8@1+ (1,-100) [-100|155] "%" Vector__XXX
 SG_ EMUS_IndividualCellModTemp__0089 : 16|8@1+ (1,-100) [-100|155] "%" Vector__XXX
 SG_ EMUS_IndividualCellModTemp__0088 : 8|8@1+ (1,-100) [-100|155] "%" Vector__XXX
 SG_ EMUS_IndividualCellModTemp__0087 : 0|8@1+ (1,-100) [-100|155] "%" Vector__XXX

BO_ 2578776588 EMUS_Individual_Cell_Mod_Te_0011: 8 EMUS_BMS
 SG_ EMUS_IndividualCellModTemp__0102 : 56|8@1+ (1,-100) [-100|155] "%" Vector__XXX
 SG_ EMUS_IndividualCellModTemp__0101 : 48|8@1+ (1,-100) [-100|155] "%" Vector__XXX
 SG_ EMUS_IndividualCellModTemp__0100 : 40|8@1+ (1,-100) [-100|155] "%" Vector__XXX
 SG_ EMUS_IndividualCellModTemp__0099 : 32|8@1+ (1,-100) [-100|155] "%" Vector__XXX
 SG_ EMUS_IndividualCellModTemp__0098 : 24|8@1+ (1,-100) [-100|155] "%" Vector__XXX
 SG_ EMUS_IndividualCellModTemp__0097 : 16|8@1+ (1,-100) [-100|155] "%" Vector__XXX
 SG_ EMUS_IndividualCellModTemp__0096 : 8|8@1+ (1,-100) [-100|155] "%" Vector__XXX
 SG_ EMUS_IndividualCellModTemp__0095 : 0|8@1+ (1,-100) [-100|155] "%" Vector__XXX

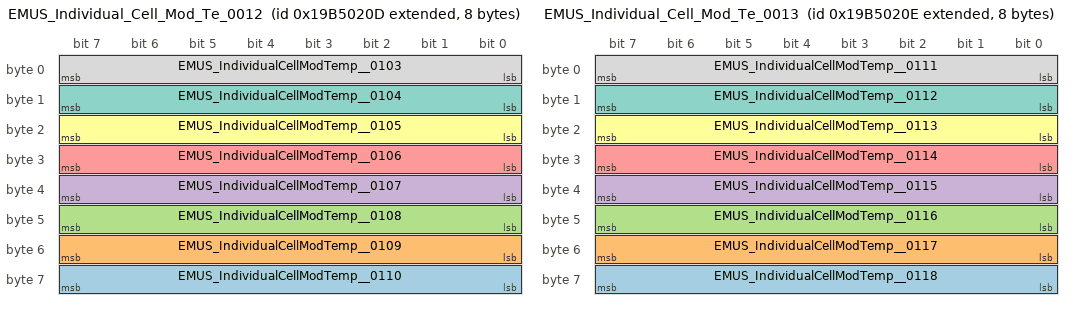
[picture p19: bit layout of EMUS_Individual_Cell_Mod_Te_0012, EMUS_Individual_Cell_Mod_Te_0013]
BO_ 2578776589 EMUS_Individual_Cell_Mod_Te_0012: 8 EMUS_BMS
 SG_ EMUS_IndividualCellModTemp__0110 : 56|8@1+ (1,-100) [-100|155] "%" Vector__XXX
 SG_ EMUS_IndividualCellModTemp__0109 : 48|8@1+ (1,-100) [-100|155] "%" Vector__XXX
 SG_ EMUS_IndividualCellModTemp__0108 : 40|8@1+ (1,-100) [-100|155] "%" Vector__XXX
 SG_ EMUS_IndividualCellModTemp__0107 : 32|8@1+ (1,-100) [-100|155] "%" Vector__XXX
 SG_ EMUS_IndividualCellModTemp__0106 : 24|8@1+ (1,-100) [-100|155] "%" Vector__XXX
 SG_ EMUS_IndividualCellModTemp__0105 : 16|8@1+ (1,-100) [-100|155] "%" Vector__XXX
 SG_ EMUS_IndividualCellModTemp__0104 : 8|8@1+ (1,-100) [-100|155] "%" Vector__XXX
 SG_ EMUS_IndividualCellModTemp__0103 : 0|8@1+ (1,-100) [-100|155] "%" Vector__XXX

BO_ 2578776590 EMUS_Individual_Cell_Mod_Te_0013: 8 EMUS_BMS
 SG_ EMUS_IndividualCellModTemp__0118 : 56|8@1+ (1,-100) [-100|155] "%" Vector__XXX
 SG_ EMUS_IndividualCellModTemp__0117 : 48|8@1+ (1,-100) [-100|155] "%" Vector__XXX
 SG_ EMUS_IndividualCellModTemp__0116 : 40|8@1+ (1,-100) [-100|155] "%" Vector__XXX
 SG_ EMUS_IndividualCellModTemp__0115 : 32|8@1+ (1,-100) [-100|155] "%" Vector__XXX
 SG_ EMUS_IndividualCellModTemp__0114 : 24|8@1+ (1,-100) [-100|155] "%" Vector__XXX
 SG_ EMUS_IndividualCellModTemp__0113 : 16|8@1+ (1,-100) [-100|155] "%" Vector__XXX
 SG_ EMUS_IndividualCellModTemp__0112 : 8|8@1+ (1,-100) [-100|155] "%" Vector__XXX
 SG_ EMUS_IndividualCellModTemp__0111 : 0|8@1+ (1,-100) [-100|155] "%" Vector__XXX

BO_ 2578776591 EMUS_Individual_Cell_Mod_Te_0014: 8 EMUS_BMS
 SG_ EMUS_IndividualCellModTemp__0126 : 56|8@1+ (1,-100) [-100|155] "%" Vector__XXX
 SG_ EMUS_IndividualCellModTemp__0125 : 48|8@1+ (1,-100) [-100|155] "%" Vector__XXX
 SG_ EMUS_IndividualCellModTemp__0124 : 40|8@1+ (1,-100) [-100|155] "%" Vector__XXX
 SG_ EMUS_IndividualCellModTemp__0123 : 32|8@1+ (1,-100) [-100|155] "%" Vector__XXX
 SG_ EMUS_IndividualCellModTemp__0122 : 24|8@1+ (1,-100) [-100|155] "%" Vector__XXX
 SG_ EMUS_IndividualCellModTemp__0121 : 16|8@1+ (1,-100) [-100|155] "%" Vector__XXX
 SG_ EMUS_IndividualCellModTemp__0120 : 8|8@1+ (1,-100) [-100|155] "%" Vector__XXX
 SG_ EMUS_IndividualCellModTemp__0119 : 0|8@1+ (1,-100) [-100|155] "%" Vector__XXX

BO_ 2578776592 EMUS_Individual_Cell_Mod_Te_0015: 8 EMUS_BMS
 SG_ EMUS_IndividualCellModTemp__0134 : 56|8@1+ (1,-100) [-100|155] "%" Vector__XXX
 SG_ EMUS_IndividualCellModTemp__0133 : 48|8@1+ (1,-100) [-100|155] "%" Vector__XXX
 SG_ EMUS_IndividualCellModTemp__0132 : 40|8@1+ (1,-100) [-100|155] "%" Vector__XXX
 SG_ EMUS_IndividualCellModTemp__0131 : 32|8@1+ (1,-100) [-100|155] "%" Vector__XXX
 SG_ EMUS_IndividualCellModTemp__0130 : 24|8@1+ (1,-100) [-100|155] "%" Vector__XXX
 SG_ EMUS_IndividualCellModTemp__0129 : 16|8@1+ (1,-100) [-100|155] "%" Vector__XXX
 SG_ EMUS_IndividualCellModTemp__0128 : 8|8@1+ (1,-100) [-100|155] "%" Vector__XXX
 SG_ EMUS_IndividualCellModTemp__0127 : 0|8@1+ (1,-100) [-100|155] "%" Vector__XXX

BO_ 2578776593 EMUS_Individual_Cell_Mod_Te_0016: 8 EMUS_BMS
 SG_ EMUS_IndividualCellModTemp__0142 : 56|8@1+ (1,-100) [-100|155] "%" Vector__XXX
 SG_ EMUS_IndividualCellModTemp__0141 : 48|8@1+ (1,-100) [-100|155] "%" Vector__XXX
 SG_ EMUS_IndividualCellModTemp__0140 : 40|8@1+ (1,-100) [-100|155] "%" Vector__XXX
 SG_ EMUS_IndividualCellModTemp__0139 : 32|8@1+ (1,-100) [-100|155] "%" Vector__XXX
 SG_ EMUS_IndividualCellModTemp__0138 : 24|8@1+ (1,-100) [-100|155] "%" Vector__XXX
 SG_ EMUS_IndividualCellModTemp__0137 : 16|8@1+ (1,-100) [-100|155] "%" Vector__XXX
 SG_ EMUS_IndividualCellModTemp__0136 : 8|8@1+ (1,-100) [-100|155] "%" Vector__XXX
 SG_ EMUS_IndividualCellModTemp__0135 : 0|8@1+ (1,-100) [-100|155] "%" Vector__XXX

BO_ 2578778112 EMUS_Individual_Cell_Temp_Ext_A0: 8 EMUS_BMS
 SG_ EMUS_IndividualCellTemperat_0006 : 56|8@1+ (1,-100) [-100|155] "%" Vector__XXX
 SG_ EMUS_IndividualCellTemperat_0005 : 48|8@1+ (1,-100) [-100|155] "%" Vector__XXX
 SG_ EMUS_IndividualCellTemperat_0004 : 40|8@1+ (1,-100) [-100|155] "%" Vector__XXX
 SG_ EMUS_IndividualCellTemperat_0003 : 32|8@1+ (1,-100) [-100|155] "%" Vector__XXX
 SG_ EMUS_IndividualCellTemperat_0002 : 24|8@1+ (1,-100) [-100|155] "%" Vector__XXX
 SG_ EMUS_IndividualCellTemperat_0001 : 16|8@1+ (1,-100) [-100|155] "%" Vector__XXX
 SG_ EMUS_IndividualCellTemperat_0000 : 8|8@1+ (1,-100) [-100|155] "%" Vector__XXX
 SG_ EMUS_IndividualCellTemperature_D : 0|8@1+ (1,-100) [-100|155] "%" Vector__XXX

BO_ 2578778113 EMUS_Individual_Cell_Temp_E_0000: 8 EMUS_BMS
 SG_ EMUS_IndividualCellTemperat_0014 : 56|8@1+ (1,-100) [-100|155] "%" Vector__XXX
 SG_ EMUS_IndividualCellTemperat_0013 : 48|8@1+ (1,-100) [-100|155] "%" Vector__XXX
 SG_ EMUS_IndividualCellTemperat_0012 : 40|8@1+ (1,-100) [-100|155] "%" Vector__XXX
 SG_ EMUS_IndividualCellTemperat_0011 : 32|8@1+ (1,-100) [-100|155] "%" Vector__XXX
 SG_ EMUS_IndividualCellTemperat_0010 : 24|8@1+ (1,-100) [-100|155] "%" Vector__XXX
 SG_ EMUS_IndividualCellTemperat_0009 : 16|8@1+ (1,-100) [-100|155] "%" Vector__XXX
 SG_ EMUS_IndividualCellTemperat_0008 : 8|8@1+ (1,-100) [-100|155] "%" Vector__XXX
 SG_ EMUS_IndividualCellTemperat_0007 : 0|8@1+ (1,-100) [-100|155] "%" Vector__XXX

BO_ 2578778114 EMUS_Individual_Cell_Temp_E_0001: 8 EMUS_BMS
 SG_ EMUS_IndividualCellTemperat_0022 : 56|8@1+ (1,-100) [-100|155] "%" Vector__XXX
 SG_ EMUS_IndividualCellTemperat_0021 : 48|8@1+ (1,-100) [-100|155] "%" Vector__XXX
 SG_ EMUS_IndividualCellTemperat_0020 : 40|8@1+ (1,-100) [-100|155] "%" Vector__XXX
 SG_ EMUS_IndividualCellTemperat_0019 : 32|8@1+ (1,-100) [-100|155] "%" Vector__XXX
 SG_ EMUS_IndividualCellTemperat_0018 : 24|8@1+ (1,-100) [-100|155] "%" Vector__XXX
 SG_ EMUS_IndividualCellTemperat_0017 : 16|8@1+ (1,-100) [-100|155] "%" Vector__XXX
 SG_ EMUS_IndividualCellTemperat_0016 : 8|8@1+ (1,-100) [-100|155] "%" Vector__XXX
 SG_ EMUS_IndividualCellTemperat_0015 : 0|8@1+ (1,-100) [-100|155] "%" Vector__XXX

BO_ 2578778115 EMUS_Individual_Cell_Temp_E_0002: 8 EMUS_BMS
 SG_ EMUS_IndividualCellTemperat_0030 : 56|8@1+ (1,-100) [-100|155] "%" Vector__XXX
 SG_ EMUS_IndividualCellTemperat_0029 : 48|8@1+ (1,-100) [-100|155] "%" Vector__XXX
 SG_ EMUS_IndividualCellTemperat_0028 : 40|8@1+ (1,-100) [-100|155] "%" Vector__XXX
 SG_ EMUS_IndividualCellTemperat_0027 : 32|8@1+ (1,-100) [-100|155] "%" Vector__XXX
 SG_ EMUS_IndividualCellTemperat_0026 : 24|8@1+ (1,-100) [-100|155] "%" Vector__XXX
 SG_ EMUS_IndividualCellTemperat_0025 : 16|8@1+ (1,-100) [-100|155] "%" Vector__XXX
 SG_ EMUS_IndividualCellTemperat_0024 : 8|8@1+ (1,-100) [-100|155] "%" Vector__XXX
 SG_ EMUS_IndividualCellTemperat_0023 : 0|8@1+ (1,-100) [-100|155] "%" Vector__XXX

BO_ 2578778116 EMUS_Individual_Cell_Temp_E_0003: 8 EMUS_BMS
 SG_ EMUS_IndividualCellTemperat_0038 : 56|8@1+ (1,-100) [-100|155] "%" Vector__XXX
 SG_ EMUS_IndividualCellTemperat_0037 : 48|8@1+ (1,-100) [-100|155] "%" Vector__XXX
 SG_ EMUS_IndividualCellTemperat_0036 : 40|8@1+ (1,-100) [-100|155] "%" Vector__XXX
 SG_ EMUS_IndividualCellTemperat_0035 : 32|8@1+ (1,-100) [-100|155] "%" Vector__XXX
 SG_ EMUS_IndividualCellTemperat_0034 : 24|8@1+ (1,-100) [-100|155] "%" Vector__XXX
 SG_ EMUS_IndividualCellTemperat_0033 : 16|8@1+ (1,-100) [-100|155] "%" Vector__XXX
 SG_ EMUS_IndividualCellTemperat_0032 : 8|8@1+ (1,-100) [-100|155] "%" Vector__XXX
 SG_ EMUS_IndividualCellTemperat_0031 : 0|8@1+ (1,-100) [-100|155] "%" Vector__XXX

BO_ 2578778117 EMUS_Individual_Cell_Temp_E_0004: 8 EMUS_BMS
 SG_ EMUS_IndividualCellTemperat_0046 : 56|8@1+ (1,-100) [-100|155] "%" Vector__XXX
 SG_ EMUS_IndividualCellTemperat_0045 : 48|8@1+ (1,-100) [-100|155] "%" Vector__XXX
 SG_ EMUS_IndividualCellTemperat_0044 : 40|8@1+ (1,-100) [-100|155] "%" Vector__XXX
 SG_ EMUS_IndividualCellTemperat_0043 : 32|8@1+ (1,-100) [-100|155] "%" Vector__XXX
 SG_ EMUS_IndividualCellTemperat_0042 : 24|8@1+ (1,-100) [-100|155] "%" Vector__XXX
 SG_ EMUS_IndividualCellTemperat_0041 : 16|8@1+ (1,-100) [-100|155] "%" Vector__XXX
 SG_ EMUS_IndividualCellTemperat_0040 : 8|8@1+ (1,-100) [-100|155] "%" Vector__XXX
 SG_ EMUS_IndividualCellTemperat_0039 : 0|8@1+ (1,-100) [-100|155] "%" Vector__XXX

BO_ 2578778118 EMUS_Individual_Cell_Temp_E_0005: 8 EMUS_BMS
 SG_ EMUS_IndividualCellTemperat_0054 : 56|8@1+ (1,-100) [-100|155] "%" Vector__XXX
 SG_ EMUS_IndividualCellTemperat_0053 : 48|8@1+ (1,-100) [-100|155] "%" Vector__XXX
 SG_ EMUS_IndividualCellTemperat_0052 : 40|8@1+ (1,-100) [-100|155] "%" Vector__XXX
 SG_ EMUS_IndividualCellTemperat_0051 : 32|8@1+ (1,-100) [-100|155] "%" Vector__XXX
 SG_ EMUS_IndividualCellTemperat_0050 : 24|8@1+ (1,-100) [-100|155] "%" Vector__XXX
 SG_ EMUS_IndividualCellTemperat_0049 : 16|8@1+ (1,-100) [-100|155] "%" Vector__XXX
 SG_ EMUS_IndividualCellTemperat_0048 : 8|8@1+ (1,-100) [-100|155] "%" Vector__XXX
 SG_ EMUS_IndividualCellTemperat_0047 : 0|8@1+ (1,-100) [-100|155] "%" Vector__XXX

BO_ 2578778119 EMUS_Individual_Cell_Temp_E_0006: 8 EMUS_BMS
 SG_ EMUS_IndividualCellTemperat_0062 : 56|8@1+ (1,-100) [-100|155] "%" Vector__XXX
 SG_ EMUS_IndividualCellTemperat_0061 : 48|8@1+ (1,-100) [-100|155] "%" Vector__XXX
 SG_ EMUS_IndividualCellTemperat_0060 : 40|8@1+ (1,-100) [-100|155] "%" Vector__XXX
 SG_ EMUS_IndividualCellTemperat_0059 : 32|8@1+ (1,-100) [-100|155] "%" Vector__XXX
 SG_ EMUS_IndividualCellTemperat_0058 : 24|8@1+ (1,-100) [-100|155] "%" Vector__XXX
 SG_ EMUS_IndividualCellTemperat_0057 : 16|8@1+ (1,-100) [-100|155] "%" Vector__XXX
 SG_ EMUS_IndividualCellTemperat_0056 : 8|8@1+ (1,-100) [-100|155] "%" Vector__XXX
 SG_ EMUS_IndividualCellTemperat_0055 : 0|8@1+ (1,-100) [-100|155] "%" Vector__XXX

BO_ 2578778120 EMUS_Individual_Cell_Temp_E_0007: 8 EMUS_BMS
 SG_ EMUS_IndividualCellTemperat_0070 : 56|8@1+ (1,-100) [-100|155] "%" Vector__XXX
 SG_ EMUS_IndividualCellTemperat_0069 : 48|8@1+ (1,-100) [-100|155] "%" Vector__XXX
 SG_ EMUS_IndividualCellTemperat_0068 : 40|8@1+ (1,-100) [-100|155] "%" Vector__XXX
 SG_ EMUS_IndividualCellTemperat_0067 : 32|8@1+ (1,-100) [-100|155] "%" Vector__XXX
 SG_ EMUS_IndividualCellTemperat_0066 : 24|8@1+ (1,-100) [-100|155] "%" Vector__XXX
 SG_ EMUS_IndividualCellTemperat_0065 : 16|8@1+ (1,-100) [-100|155] "%" Vector__XXX
 SG_ EMUS_IndividualCellTemperat_0064 : 8|8@1+ (1,-100) [-100|155] "%" Vector__XXX
 SG_ EMUS_IndividualCellTemperat_0063 : 0|8@1+ (1,-100) [-100|155] "%" Vector__XXX

BO_ 2578778121 EMUS_Individual_Cell_Temp_E_0008: 8 EMUS_BMS
 SG_ EMUS_IndividualCellTemperat_0078 : 56|8@1+ (1,-100) [-100|155] "%" Vector__XXX
 SG_ EMUS_IndividualCellTemperat_0077 : 48|8@1+ (1,-100) [-100|155] "%" Vector__XXX
 SG_ EMUS_IndividualCellTemperat_0076 : 40|8@1+ (1,-100) [-100|155] "%" Vector__XXX
 SG_ EMUS_IndividualCellTemperat_0075 : 32|8@1+ (1,-100) [-100|155] "%" Vector__XXX
 SG_ EMUS_IndividualCellTemperat_0074 : 24|8@1+ (1,-100) [-100|155] "%" Vector__XXX
 SG_ EMUS_IndividualCellTemperat_0073 : 16|8@1+ (1,-100) [-100|155] "%" Vector__XXX
 SG_ EMUS_IndividualCellTemperat_0072 : 8|8@1+ (1,-100) [-100|155] "%" Vector__XXX
 SG_ EMUS_IndividualCellTemperat_0071 : 0|8@1+ (1,-100) [-100|155] "%" Vector__XXX

BO_ 2578778122 EMUS_Individual_Cell_Temp_Ext_A1: 8 EMUS_BMS
 SG_ EMUS_IndividualCellTemperat_0086 : 56|8@1+ (1,-100) [-100|155] "%" Vector__XXX
 SG_ EMUS_IndividualCellTemperat_0085 : 48|8@1+ (1,-100) [-100|155] "%" Vector__XXX
 SG_ EMUS_IndividualCellTemperat_0084 : 40|8@1+ (1,-100) [-100|155] "%" Vector__XXX
 SG_ EMUS_IndividualCellTemperat_0083 : 32|8@1+ (1,-100) [-100|155] "%" Vector__XXX
 SG_ EMUS_IndividualCellTemperat_0082 : 24|8@1+ (1,-100) [-100|155] "%" Vector__XXX
 SG_ EMUS_IndividualCellTemperat_0081 : 16|8@1+ (1,-100) [-100|155] "%" Vector__XXX
 SG_ EMUS_IndividualCellTemperat_0080 : 8|8@1+ (1,-100) [-100|155] "%" Vector__XXX
 SG_ EMUS_IndividualCellTemperat_0079 : 0|8@1+ (1,-100) [-100|155] "%" Vector__XXX

BO_ 2578776075 EMUS_Individual_Cells_Volta_0017: 8 EMUS_BMS
 SG_ EMUS_IndividualCellVoltage__0149 : 56|8@1+ (0.01,2) [2|4.55] "V" Vector__XXX
 SG_ EMUS_IndividualCellVoltage__0148 : 48|8@1+ (0.01,2) [2|4.55] "V" Vector__XXX
 SG_ EMUS_IndividualCellVoltage__0147 : 40|8@1+ (0.01,2) [2|4.55] "V" Vector__XXX
 SG_ EMUS_IndividualCellVoltage__0146 : 32|8@1+ (0.01,2) [2|4.55] "V" Vector__XXX
 SG_ EMUS_IndividualCellVoltage__0145 : 24|8@1+ (0.01,2) [2|4.55] "V" Vector__XXX
 SG_ EMUS_IndividualCellVoltage__0144 : 16|8@1+ (0.01,2) [2|4.55] "V" Vector__XXX
 SG_ EMUS_IndividualCellVoltage__0143 : 8|8@1+ (0.01,2) [2|4.55] "V" Vector__XXX
 SG_ EMUS_Individual_Cells_Group_Opt_ : 0|8@1+ (1,0) [0|255] "" Vector__XXX

BO_ 2578776077 EMUS_Individual_Cell_Balan_Rate_: 8 EMUS_BMS
 SG_ EMUS_IndividualCellBalancRa_0005 : 56|8@1+ (0.392156862745098,0) [0|100] "%" Vector__XXX
 SG_ EMUS_IndividualCellBalancRa_0004 : 48|8@1+ (0.392156862745098,0) [0|100] "%" Vector__XXX
 SG_ EMUS_IndividualCellBalancRa_0003 : 40|8@1+ (0.392156862745098,0) [0|100] "%" Vector__XXX
 SG_ EMUS_IndividualCellBalancRa_0002 : 32|8@1+ (0.392156862745098,0) [0|100] "%" Vector__XXX
 SG_ EMUS_IndividualCellBalancRa_0001 : 24|8@1+ (0.392156862745098,0) [0|100] "%" Vector__XXX
 SG_ EMUS_IndividualCellBalancRa_0000 : 16|8@1+ (0.392156862745098,0) [0|100] "%" Vector__XXX
 SG_ EMUS_IndividualCellBalancRate_Da : 8|8@1+ (0.392156862745098,0) [0|100] "%" Vector__XXX
 SG_ EMUS_Individual_Cells_Group_0000 : 0|8@1+ (1,0) [0|255] "" Vector__XXX

BO_ 2578776832 EMUS_Individual_Cell_Balan__0000: 8 EMUS_BMS
 SG_ EMUS_IndividualCellBalancRa_0013 : 56|8@1+ (0.392156862745098,0) [0|100] "%" Vector__XXX
 SG_ EMUS_IndividualCellBalancRa_0012 : 48|8@1+ (0.392156862745098,0) [0|100] "%" Vector__XXX
 SG_ EMUS_IndividualCellBalancRa_0011 : 40|8@1+ (0.392156862745098,0) [0|100] "%" Vector__XXX
 SG_ EMUS_IndividualCellBalancRa_0010 : 32|8@1+ (0.392156862745098,0) [0|100] "%" Vector__XXX
 SG_ EMUS_IndividualCellBalancRa_0009 : 24|8@1+ (0.392156862745098,0) [0|100] "%" Vector__XXX
 SG_ EMUS_IndividualCellBalancRa_0008 : 16|8@1+ (0.392156862745098,0) [0|100] "%" Vector__XXX
 SG_ EMUS_IndividualCellBalancRa_0007 : 8|8@1+ (0.392156862745098,0) [0|100] "%" Vector__XXX
 SG_ EMUS_IndividualCellBalancRa_0006 : 0|8@1+ (0.392156862745098,0) [0|100] "%" Vector__XXX

BO_ 2578776833 EMUS_Individual_Cell_Balan__0001: 8 EMUS_BMS
 SG_ EMUS_IndividualCellBalancRa_0021 : 56|8@1+ (0.392156862745098,0) [0|100] "%" Vector__XXX
 SG_ EMUS_IndividualCellBalancRa_0020 : 48|8@1+ (0.392156862745098,0) [0|100] "%" Vector__XXX
 SG_ EMUS_IndividualCellBalancRa_0019 : 40|8@1+ (0.392156862745098,0) [0|100] "%" Vector__XXX
 SG_ EMUS_IndividualCellBalancRa_0018 : 32|8@1+ (0.392156862745098,0) [0|100] "%" Vector__XXX
 SG_ EMUS_IndividualCellBalancRa_0017 : 24|8@1+ (0.392156862745098,0) [0|100] "%" Vector__XXX
 SG_ EMUS_IndividualCellBalancRa_0016 : 16|8@1+ (0.392156862745098,0) [0|100] "%" Vector__XXX
 SG_ EMUS_IndividualCellBalancRa_0015 : 8|8@1+ (0.392156862745098,0) [0|100] "%" Vector__XXX
 SG_ EMUS_IndividualCellBalancRa_0014 : 0|8@1+ (0.392156862745098,0) [0|100] "%" Vector__XXX

BO_ 2578776834 EMUS_Individual_Cell_Balan__0002: 8 EMUS_BMS
 SG_ EMUS_IndividualCellBalancRa_0029 : 56|8@1+ (0.392156862745098,0) [0|100] "%" Vector__XXX
 SG_ EMUS_IndividualCellBalancRa_0028 : 48|8@1+ (0.392156862745098,0) [0|100] "%" Vector__XXX
 SG_ EMUS_IndividualCellBalancRa_0027 : 40|8@1+ (0.392156862745098,0) [0|100] "%" Vector__XXX
 SG_ EMUS_IndividualCellBalancRa_0026 : 32|8@1+ (0.392156862745098,0) [0|100] "%" Vector__XXX
 SG_ EMUS_IndividualCellBalancRa_0025 : 24|8@1+ (0.392156862745098,0) [0|100] "%" Vector__XXX
 SG_ EMUS_IndividualCellBalancRa_0024 : 16|8@1+ (0.392156862745098,0) [0|100] "%" Vector__XXX
 SG_ EMUS_IndividualCellBalancRa_0023 : 8|8@1+ (0.392156862745098,0) [0|100] "%" Vector__XXX
 SG_ EMUS_IndividualCellBalancRa_0022 : 0|8@1+ (0.392156862745098,0) [0|100] "%" Vector__XXX

BO_ 2578776835 EMUS_Individual_Cell_Balan__0003: 8 EMUS_BMS
 SG_ EMUS_IndividualCellBalancRa_0037 : 56|8@1+ (0.392156862745098,0) [0|100] "%" Vector__XXX
 SG_ EMUS_IndividualCellBalancRa_0036 : 48|8@1+ (0.392156862745098,0) [0|100] "%" Vector__XXX
 SG_ EMUS_IndividualCellBalancRa_0035 : 40|8@1+ (0.392156862745098,0) [0|100] "%" Vector__XXX
 SG_ EMUS_IndividualCellBalancRa_0034 : 32|8@1+ (0.392156862745098,0) [0|100] "%" Vector__XXX
 SG_ EMUS_IndividualCellBalancRa_0033 : 24|8@1+ (0.392156862745098,0) [0|100] "%" Vector__XXX
 SG_ EMUS_IndividualCellBalancRa_0032 : 16|8@1+ (0.392156862745098,0) [0|100] "%" Vector__XXX
 SG_ EMUS_IndividualCellBalancRa_0031 : 8|8@1+ (0.392156862745098,0) [0|100] "%" Vector__XXX
 SG_ EMUS_IndividualCellBalancRa_0030 : 0|8@1+ (0.392156862745098,0) [0|100] "%" Vector__XXX

BO_ 2578776836 EMUS_Individual_Cell_Balan__0004: 8 EMUS_BMS
 SG_ EMUS_IndividualCellBalancRa_0045 : 56|8@1+ (0.392156862745098,0) [0|100] "%" Vector__XXX
 SG_ EMUS_IndividualCellBalancRa_0044 : 48|8@1+ (0.392156862745098,0) [0|100] "%" Vector__XXX
 SG_ EMUS_IndividualCellBalancRa_0043 : 40|8@1+ (0.392156862745098,0) [0|100] "%" Vector__XXX
 SG_ EMUS_IndividualCellBalancRa_0042 : 32|8@1+ (0.392156862745098,0) [0|100] "%" Vector__XXX
 SG_ EMUS_IndividualCellBalancRa_0041 : 24|8@1+ (0.392156862745098,0) [0|100] "%" Vector__XXX
 SG_ EMUS_IndividualCellBalancRa_0040 : 16|8@1+ (0.392156862745098,0) [0|100] "%" Vector__XXX
 SG_ EMUS_IndividualCellBalancRa_0039 : 8|8@1+ (0.392156862745098,0) [0|100] "%" Vector__XXX
 SG_ EMUS_IndividualCellBalancRa_0038 : 0|8@1+ (0.392156862745098,0) [0|100] "%" Vector__XXX

BO_ 2578776837 EMUS_Individual_Cell_Balan__0005: 8 EMUS_BMS
 SG_ EMUS_IndividualCellBalancRa_0053 : 56|8@1+ (0.392156862745098,0) [0|100] "%" Vector__XXX
 SG_ EMUS_IndividualCellBalancRa_0052 : 48|8@1+ (0.392156862745098,0) [0|100] "%" Vector__XXX
 SG_ EMUS_IndividualCellBalancRa_0051 : 40|8@1+ (0.392156862745098,0) [0|100] "%" Vector__XXX
 SG_ EMUS_IndividualCellBalancRa_0050 : 32|8@1+ (0.392156862745098,0) [0|100] "%" Vector__XXX
 SG_ EMUS_IndividualCellBalancRa_0049 : 24|8@1+ (0.392156862745098,0) [0|100] "%" Vector__XXX
 SG_ EMUS_IndividualCellBalancRa_0048 : 16|8@1+ (0.392156862745098,0) [0|100] "%" Vector__XXX
 SG_ EMUS_IndividualCellBalancRa_0047 : 8|8@1+ (0.392156862745098,0) [0|100] "%" Vector__XXX
 SG_ EMUS_IndividualCellBalancRa_0046 : 0|8@1+ (0.392156862745098,0) [0|100] "%" Vector__XXX

BO_ 2578776838 EMUS_Individual_Cell_Balan__0006: 8 EMUS_BMS
 SG_ EMUS_IndividualCellBalancRa_0061 : 56|8@1+ (0.392156862745098,0) [0|100] "%" Vector__XXX
 SG_ EMUS_IndividualCellBalancRa_0060 : 48|8@1+ (0.392156862745098,0) [0|100] "%" Vector__XXX
 SG_ EMUS_IndividualCellBalancRa_0059 : 40|8@1+ (0.392156862745098,0) [0|100] "%" Vector__XXX
 SG_ EMUS_IndividualCellBalancRa_0058 : 32|8@1+ (0.392156862745098,0) [0|100] "%" Vector__XXX
 SG_ EMUS_IndividualCellBalancRa_0057 : 24|8@1+ (0.392156862745098,0) [0|100] "%" Vector__XXX
 SG_ EMUS_IndividualCellBalancRa_0056 : 16|8@1+ (0.392156862745098,0) [0|100] "%" Vector__XXX
 SG_ EMUS_IndividualCellBalancRa_0055 : 8|8@1+ (0.392156862745098,0) [0|100] "%" Vector__XXX
 SG_ EMUS_IndividualCellBalancRa_0054 : 0|8@1+ (0.392156862745098,0) [0|100] "%" Vector__XXX

BO_ 2578776839 EMUS_Individual_Cell_Balan__0007: 8 EMUS_BMS
 SG_ EMUS_IndividualCellBalancRa_0069 : 56|8@1+ (0.392156862745098,0) [0|100] "%" Vector__XXX
 SG_ EMUS_IndividualCellBalancRa_0068 : 48|8@1+ (0.392156862745098,0) [0|100] "%" Vector__XXX
 SG_ EMUS_IndividualCellBalancRa_0067 : 40|8@1+ (0.392156862745098,0) [0|100] "%" Vector__XXX
 SG_ EMUS_IndividualCellBalancRa_0066 : 32|8@1+ (0.392156862745098,0) [0|100] "%" Vector__XXX
 SG_ EMUS_IndividualCellBalancRa_0065 : 24|8@1+ (0.392156862745098,0) [0|100] "%" Vector__XXX
 SG_ EMUS_IndividualCellBalancRa_0064 : 16|8@1+ (0.392156862745098,0) [0|100] "%" Vector__XXX
 SG_ EMUS_IndividualCellBalancRa_0063 : 8|8@1+ (0.392156862745098,0) [0|100] "%" Vector__XXX
 SG_ EMUS_IndividualCellBalancRa_0062 : 0|8@1+ (0.392156862745098,0) [0|100] "%" Vector__XXX

BO_ 2578776840 EMUS_Individual_Cell_Balan__0008: 8 EMUS_BMS
 SG_ EMUS_IndividualCellBalancRa_0077 : 56|8@1+ (0.392156862745098,0) [0|100] "%" Vector__XXX
 SG_ EMUS_IndividualCellBalancRa_0076 : 48|8@1+ (0.392156862745098,0) [0|100] "%" Vector__XXX
 SG_ EMUS_IndividualCellBalancRa_0075 : 40|8@1+ (0.392156862745098,0) [0|100] "%" Vector__XXX
 SG_ EMUS_IndividualCellBalancRa_0074 : 32|8@1+ (0.392156862745098,0) [0|100] "%" Vector__XXX
 SG_ EMUS_IndividualCellBalancRa_0073 : 24|8@1+ (0.392156862745098,0) [0|100] "%" Vector__XXX
 SG_ EMUS_IndividualCellBalancRa_0072 : 16|8@1+ (0.392156862745098,0) [0|100] "%" Vector__XXX
 SG_ EMUS_IndividualCellBalancRa_0071 : 8|8@1+ (0.392156862745098,0) [0|100] "%" Vector__XXX
 SG_ EMUS_IndividualCellBalancRa_0070 : 0|8@1+ (0.392156862745098,0) [0|100] "%" Vector__XXX

BO_ 2578776841 EMUS_Individual_Cell_Balan__0009: 8 EMUS_BMS
 SG_ EMUS_IndividualCellBalancRa_0085 : 56|8@1+ (0.392156862745098,0) [0|100] "%" Vector__XXX
 SG_ EMUS_IndividualCellBalancRa_0084 : 48|8@1+ (0.392156862745098,0) [0|100] "%" Vector__XXX
 SG_ EMUS_IndividualCellBalancRa_0083 : 40|8@1+ (0.392156862745098,0) [0|100] "%" Vector__XXX
 SG_ EMUS_IndividualCellBalancRa_0082 : 32|8@1+ (0.392156862745098,0) [0|100] "%" Vector__XXX
 SG_ EMUS_IndividualCellBalancRa_0081 : 24|8@1+ (0.392156862745098,0) [0|100] "%" Vector__XXX
 SG_ EMUS_IndividualCellBalancRa_0080 : 16|8@1+ (0.392156862745098,0) [0|100] "%" Vector__XXX
 SG_ EMUS_IndividualCellBalancRa_0079 : 8|8@1+ (0.392156862745098,0) [0|100] "%" Vector__XXX
 SG_ EMUS_IndividualCellBalancRa_0078 : 0|8@1+ (0.392156862745098,0) [0|100] "%" Vector__XXX

BO_ 2578776842 EMUS_Individual_Cell_Balan__0010: 8 EMUS_BMS
 SG_ EMUS_IndividualCellBalancRa_0093 : 56|8@1+ (0.392156862745098,0) [0|100] "%" Vector__XXX
 SG_ EMUS_IndividualCellBalancRa_0092 : 48|8@1+ (0.392156862745098,0) [0|100] "%" Vector__XXX
 SG_ EMUS_IndividualCellBalancRa_0091 : 40|8@1+ (0.392156862745098,0) [0|100] "%" Vector__XXX
 SG_ EMUS_IndividualCellBalancRa_0090 : 32|8@1+ (0.392156862745098,0) [0|100] "%" Vector__XXX
 SG_ EMUS_IndividualCellBalancRa_0089 : 24|8@1+ (0.392156862745098,0) [0|100] "%" Vector__XXX
 SG_ EMUS_IndividualCellBalancRa_0088 : 16|8@1+ (0.392156862745098,0) [0|100] "%" Vector__XXX
 SG_ EMUS_IndividualCellBalancRa_0087 : 8|8@1+ (0.392156862745098,0) [0|100] "%" Vector__XXX
 SG_ EMUS_IndividualCellBalancRa_0086 : 0|8@1+ (0.392156862745098,0) [0|100] "%" Vector__XXX

BO_ 2578776843 EMUS_Individual_Cell_Balan__0011: 8 EMUS_BMS
 SG_ EMUS_IndividualCellBalancRa_0101 : 56|8@1+ (0.392156862745098,0) [0|100] "%" Vector__XXX
 SG_ EMUS_IndividualCellBalancRa_0100 : 48|8@1+ (0.392156862745098,0) [0|100] "%" Vector__XXX
 SG_ EMUS_IndividualCellBalancRa_0099 : 40|8@1+ (0.392156862745098,0) [0|100] "%" Vector__XXX
 SG_ EMUS_IndividualCellBalancRa_0098 : 32|8@1+ (0.392156862745098,0) [0|100] "%" Vector__XXX
 SG_ EMUS_IndividualCellBalancRa_0097 : 24|8@1+ (0.392156862745098,0) [0|100] "%" Vector__XXX
 SG_ EMUS_IndividualCellBalancRa_0096 : 16|8@1+ (0.392156862745098,0) [0|100] "%" Vector__XXX
 SG_ EMUS_IndividualCellBalancRa_0095 : 8|8@1+ (0.392156862745098,0) [0|100] "%" Vector__XXX
 SG_ EMUS_IndividualCellBalancRa_0094 : 0|8@1+ (0.392156862745098,0) [0|100] "%" Vector__XXX

BO_ 2578776844 EMUS_Individual_Cell_Balan__0012: 8 EMUS_BMS
 SG_ EMUS_IndividualCellBalancRa_0109 : 56|8@1+ (0.392156862745098,0) [0|100] "%" Vector__XXX
 SG_ EMUS_IndividualCellBalancRa_0108 : 48|8@1+ (0.392156862745098,0) [0|100] "%" Vector__XXX
 SG_ EMUS_IndividualCellBalancRa_0107 : 40|8@1+ (0.392156862745098,0) [0|100] "%" Vector__XXX
 SG_ EMUS_IndividualCellBalancRa_0106 : 32|8@1+ (0.392156862745098,0) [0|100] "%" Vector__XXX
 SG_ EMUS_IndividualCellBalancRa_0105 : 24|8@1+ (0.392156862745098,0) [0|100] "%" Vector__XXX
 SG_ EMUS_IndividualCellBalancRa_0104 : 16|8@1+ (0.392156862745098,0) [0|100] "%" Vector__XXX
 SG_ EMUS_IndividualCellBalancRa_0103 : 8|8@1+ (0.392156862745098,0) [0|100] "%" Vector__XXX
 SG_ EMUS_IndividualCellBalancRa_0102 : 0|8@1+ (0.392156862745098,0) [0|100] "%" Vector__XXX

BO_ 2578776845 EMUS_Individual_Cell_Balan__0013: 8 EMUS_BMS
 SG_ EMUS_IndividualCellBalancRa_0117 : 56|8@1+ (0.392156862745098,0) [0|100] "%" Vector__XXX
 SG_ EMUS_IndividualCellBalancRa_0116 : 48|8@1+ (0.392156862745098,0) [0|100] "%" Vector__XXX
 SG_ EMUS_IndividualCellBalancRa_0115 : 40|8@1+ (0.392156862745098,0) [0|100] "%" Vector__XXX
 SG_ EMUS_IndividualCellBalancRa_0114 : 32|8@1+ (0.392156862745098,0) [0|100] "%" Vector__XXX
 SG_ EMUS_IndividualCellBalancRa_0113 : 24|8@1+ (0.392156862745098,0) [0|100] "%" Vector__XXX
 SG_ EMUS_IndividualCellBalancRa_0112 : 16|8@1+ (0.392156862745098,0) [0|100] "%" Vector__XXX
 SG_ EMUS_IndividualCellBalancRa_0111 : 8|8@1+ (0.392156862745098,0) [0|100] "%" Vector__XXX
 SG_ EMUS_IndividualCellBalancRa_0110 : 0|8@1+ (0.392156862745098,0) [0|100] "%" Vector__XXX

BO_ 2578776846 EMUS_Individual_Cell_Balan__0014: 8 EMUS_BMS
 SG_ EMUS_IndividualCellBalancRa_0125 : 56|8@1+ (0.392156862745098,0) [0|100] "%" Vector__XXX
 SG_ EMUS_IndividualCellBalancRa_0124 : 48|8@1+ (0.392156862745098,0) [0|100] "%" Vector__XXX
 SG_ EMUS_IndividualCellBalancRa_0123 : 40|8@1+ (0.392156862745098,0) [0|100] "%" Vector__XXX
 SG_ EMUS_IndividualCellBalancRa_0122 : 32|8@1+ (0.392156862745098,0) [0|100] "%" Vector__XXX
 SG_ EMUS_IndividualCellBalancRa_0121 : 24|8@1+ (0.392156862745098,0) [0|100] "%" Vector__XXX
 SG_ EMUS_IndividualCellBalancRa_0120 : 16|8@1+ (0.392156862745098,0) [0|100] "%" Vector__XXX
 SG_ EMUS_IndividualCellBalancRa_0119 : 8|8@1+ (0.392156862745098,0) [0|100] "%" Vector__XXX
 SG_ EMUS_IndividualCellBalancRa_0118 : 0|8@1+ (0.392156862745098,0) [0|100] "%" Vector__XXX

BO_ 2578776847 EMUS_Individual_Cell_Balan__0015: 8 EMUS_BMS
 SG_ EMUS_IndividualCellBalancRa_0133 : 56|8@1+ (0.392156862745098,0) [0|100] "%" Vector__XXX
 SG_ EMUS_IndividualCellBalancRa_0132 : 48|8@1+ (0.392156862745098,0) [0|100] "%" Vector__XXX
 SG_ EMUS_IndividualCellBalancRa_0131 : 40|8@1+ (0.392156862745098,0) [0|100] "%" Vector__XXX
 SG_ EMUS_IndividualCellBalancRa_0130 : 32|8@1+ (0.392156862745098,0) [0|100] "%" Vector__XXX
 SG_ EMUS_IndividualCellBalancRa_0129 : 24|8@1+ (0.392156862745098,0) [0|100] "%" Vector__XXX
 SG_ EMUS_IndividualCellBalancRa_0128 : 16|8@1+ (0.392156862745098,0) [0|100] "%" Vector__XXX
 SG_ EMUS_IndividualCellBalancRa_0127 : 8|8@1+ (0.392156862745098,0) [0|100] "%" Vector__XXX
 SG_ EMUS_IndividualCellBalancRa_0126 : 0|8@1+ (0.392156862745098,0) [0|100] "%" Vector__XXX

BO_ 2578776848 EMUS_Individual_Cell_Balan__0016: 8 EMUS_BMS
 SG_ EMUS_IndividualCellBalancRa_0141 : 56|8@1+ (0.392156862745098,0) [0|100] "%" Vector__XXX
 SG_ EMUS_IndividualCellBalancRa_0140 : 48|8@1+ (0.392156862745098,0) [0|100] "%" Vector__XXX
 SG_ EMUS_IndividualCellBalancRa_0139 : 40|8@1+ (0.392156862745098,0) [0|100] "%" Vector__XXX
 SG_ EMUS_IndividualCellBalancRa_0138 : 32|8@1+ (0.392156862745098,0) [0|100] "%" Vector__XXX
 SG_ EMUS_IndividualCellBalancRa_0137 : 24|8@1+ (0.392156862745098,0) [0|100] "%" Vector__XXX
 SG_ EMUS_IndividualCellBalancRa_0136 : 16|8@1+ (0.392156862745098,0) [0|100] "%" Vector__XXX
 SG_ EMUS_IndividualCellBalancRa_0135 : 8|8@1+ (0.392156862745098,0) [0|100] "%" Vector__XXX
 SG_ EMUS_IndividualCellBalancRa_0134 : 0|8@1+ (0.392156862745098,0) [0|100] "%" Vector__XXX

BO_ 2578776849 EMUS_Individual_Cell_Balan__0017: 8 EMUS_BMS
 SG_ EMUS_IndividualCellBalancRa_0149 : 56|8@1+ (0.392156862745098,0) [0|100] "%" Vector__XXX
 SG_ EMUS_IndividualCellBalancRa_0148 : 48|8@1+ (0.392156862745098,0) [0|100] "%" Vector__XXX
 SG_ EMUS_IndividualCellBalancRa_0147 : 40|8@1+ (0.392156862745098,0) [0|100] "%" Vector__XXX
 SG_ EMUS_IndividualCellBalancRa_0146 : 32|8@1+ (0.392156862745098,0) [0|100] "%" Vector__XXX
 SG_ EMUS_IndividualCellBalancRa_0145 : 24|8@1+ (0.392156862745098,0) [0|100] "%" Vector__XXX
 SG_ EMUS_IndividualCellBalancRa_0144 : 16|8@1+ (0.392156862745098,0) [0|100] "%" Vector__XXX
 SG_ EMUS_IndividualCellBalancRa_0143 : 8|8@1+ (0.392156862745098,0) [0|100] "%" Vector__XXX
 SG_ EMUS_IndividualCellBalancRa_0142 : 0|8@1+ (0.392156862745098,0) [0|100] "%" Vector__XXX

BO_ 2578776076 EMUS_Individual_Cell_Mod_Te_0017: 8 EMUS_BMS
 SG_ EMUS_IndividualCellModTemp__0149 : 56|8@1+ (1,-100) [-100|155] "%" Vector__XXX
 SG_ EMUS_IndividualCellModTemp__0148 : 48|8@1+ (1,-100) [-100|155] "%" Vector__XXX
 SG_ EMUS_IndividualCellModTemp__0147 : 40|8@1+ (1,-100) [-100|155] "%" Vector__XXX
 SG_ EMUS_IndividualCellModTemp__0146 : 32|8@1+ (1,-100) [-100|155] "%" Vector__XXX
 SG_ EMUS_IndividualCellModTemp__0145 : 24|8@1+ (1,-100) [-100|155] "%" Vector__XXX
 SG_ EMUS_IndividualCellModTemp__0144 : 16|8@1+ (1,-100) [-100|155] "%" Vector__XXX
 SG_ EMUS_IndividualCellModTemp__0143 : 8|8@1+ (1,-100) [-100|155] "%" Vector__XXX
 SG_ EMUS_Individual_Cells_Group_0001 : 0|8@1+ (1,0) [0|255] "" Vector__XXX

BO_ 2578776078 EMUS_Individual_Cell_Temp_Ext_B: 8 EMUS_BMS
 SG_ EMUS_IndividualCellTemperat_0149 : 56|8@1+ (1,-100) [-100|155] "%" Vector__XXX
 SG_ EMUS_IndividualCellTemperat_0148 : 48|8@1+ (1,-100) [-100|155] "%" Vector__XXX
 SG_ EMUS_IndividualCellTemperat_0147 : 40|8@1+ (1,-100) [-100|155] "%" Vector__XXX
 SG_ EMUS_IndividualCellTemperat_0146 : 32|8@1+ (1,-100) [-100|155] "%" Vector__XXX
 SG_ EMUS_IndividualCellTemperat_0145 : 24|8@1+ (1,-100) [-100|155] "%" Vector__XXX
 SG_ EMUS_IndividualCellTemperat_0144 : 16|8@1+ (1,-100) [-100|155] "%" Vector__XXX
 SG_ EMUS_IndividualCellTemperat_0143 : 8|8@1+ (1,-100) [-100|155] "%" Vector__XXX
 SG_ EMUS_Individual_Cells_Group_0002 : 0|8@1+ (1,0) [0|255] "" Vector__XXX

BO_ 2578777091 EMUS_Login_Set_Password_Status_E: 8 EMUS_BMS
 SG_ EMUS_LoginSetPasswordStatus : 0|8@1+ (1,0) [0|255] "" Vector__XXX

BO_ 409 HVTU_TX_Voltage: 6 HVTU
 SG_ HVTU_EMUS_MaxCellVoltage : 40|8@1+ (0.01,2) [2|4.55] "V" Vector__XXX
 SG_ HVTU_EMUS_Pack_Voltage : 16|24@1- (0.01,0) [-83886.08|83886.07] "V" Vector__XXX
 SG_ HVTU_EMUS_AvgCellVoltage : 8|8@1+ (0.01,2) [2|4.55] "V" Vector__XXX
 SG_ HVTU_EMUS_MinCellVoltage : 0|8@1+ (0.01,2) [2|4.55] "V" Vector__XXX

BO_ 473 HVTU_RX_PDO1: 0 Vector__XXX

BO_ 537 HVTU_TX_Balance_Rate: 3 HVTU
 SG_ HVTU_EMUS_MinCellBalanceRate : 16|8@1+ (0.392156862745098,0) [0|100] "%" Vector__XXX
 SG_ HVTU_EMUS_MaxCellBalanceRate : 8|8@1+ (0.392156862745098,0) [0|100] "%" Vector__XXX
 SG_ HVTU_EMUS_AvgCellBalanceRate : 0|8@1+ (0.392156862745098,0) [0|100] "%" Vector__XXX

BO_ 601 HVTU_RX_PDO2: 0 Vector__XXX

BO_ 665 HVTU_TX_Cell_Mod_Temp: 3 HVTU
 SG_ HVTU_EMUS_MinCellModTemp : 16|8@1+ (1,-100) [-100|155] "�C" Vector__XXX
 SG_ HVTU_EMUS_AvgCellModTemp : 8|8@1+ (1,-100) [-100|155] "�C" Vector__XXX
 SG_ HVTU_EMUS_MaxCellModTemp : 0|8@1+ (1,-100) [-100|155] "�C" Vector__XXX

BO_ 729 HVTU_RX_PDO3: 0 Vector__XXX

BO_ 793 HVTU_TX_Cell_Temp: 3 HVTU
 SG_ HVTU_EMUS_MinCellTemp : 16|8@1+ (1,-100) [-100|155] "�C" Vector__XXX
 SG_ HVTU_EMUS_MaxCellTemp : 8|8@1+ (1,-100) [-100|155] "�C" Vector__XXX
 SG_ HVTU_EMUS_AvgCellTemp : 0|8@1+ (1,-100) [-100|155] "�C" Vector__XXX

BO_ 857 HVTU_RX_PDO4: 0 Vector__XXX

BO_ 921 HVTU_TX_Diagnostics: 3 HVTU
 SG_ HVTU_EMUS_Diag_UnderVoltage : 18|1@1+ (1,0) [0|0] "" Vector__XXX
 SG_ HVTU_EMUS_Diag_Pack_UnderVoltage : 17|1@1+ (1,0) [0|0] "" Vector__XXX
 SG_ HVTU_EMUS_Diag_OverVoltage : 16|1@1+ (1,0) [0|0] "" Vector__XXX
 SG_ HVTU_EMUS_Diag_NoCurrentSensor : 15|1@1+ (1,0) [0|0] "" Vector__XXX
 SG_ HVTU_EMUS_Diag_NumOfCellsVal : 14|1@1+ (1,0) [0|0] "" Vector__XXX
 SG_ HVTU_EMUS_Diag_NoCellComm : 13|1@1+ (1,0) [0|0] "" Vector__XXX
 SG_ HVTU_EMUS_Diag_LowVoltage : 12|1@1+ (1,0) [0|0] "" Vector__XXX
 SG_ HVTU_EMUS_Diag_Leackage : 11|1@1+ (1,0) [0|0] "" Vector__XXX
 SG_ HVTU_EMUS_Diag_HighTemp : 10|1@1+ (1,0) [0|0] "" Vector__XXX
 SG_ HVTU_EMUS_Diag_HighCurrent : 9|1@1+ (1,0) [0|0] "" Vector__XXX
 SG_ HVTU_EMUS_Diag_DchrgOverCurrent : 8|1@1+ (1,0) [0|0] "" Vector__XXX
 SG_ HVTU_EMUS_Diag_ChargeOverCurrent : 7|1@1+ (1,0) [0|0] "" Vector__XXX
 SG_ HVTU_EMUS_Diag_CellVoltValid : 6|1@1+ (1,0) [0|0] "" Vector__XXX
 SG_ HVTU_EMUS_Diag_CellTempValid : 5|1@1+ (1,0) [0|0] "" Vector__XXX
 SG_ HVTU_EMUS_Diag_CellOverHeat : 4|1@1+ (1,0) [0|0] "" Vector__XXX
 SG_ HVTU_EMUS_Diag_CellModTempValid : 3|1@1+ (1,0) [0|0] "" Vector__XXX
 SG_ HVTU_EMUS_Diag_CellModOverHeat : 2|1@1+ (1,0) [0|0] "" Vector__XXX
 SG_ HVTU_EMUS_Diag_CellBalanceValid : 1|1@1+ (1,0) [0|0] "" Vector__XXX
 SG_ HVTU_EMUS_Diag_BatChargeFinish : 0|1@1+ (1,0) [0|0] "" Vector__XXX

BO_ 985 HVTU_TX_Current_SOC: 5 HVTU
 SG_ HVTU_EMUS_Pack_SOC : 32|8@1+ (1,0) [0|100] "%" Vector__XXX
 SG_ HVTU_EMUS_Pack_Est_Charge : 16|16@1+ (0.1,0) [0|6553.5] "Ah" Vector__XXX
 SG_ HVTU_EMUS_Pack_Current : 0|16@1- (0.1,0) [-3276.8|3276.7] "A" Vector__XXX

BO_ 1049 HVTU_TX_PDO7: 0 HVTU

BO_ 1113 HVTU_TX_PDO8: 0 HVTU

BO_ 1177 HVTU_TX_PDO9: 0 HVTU

BO_ 1241 HVTU_TX_PDO10: 0 HVTU

BO_ 1305 HVTU_TX_PDO11: 0 HVTU

BO_ 1369 HVTU_TX_PDO12: 0 HVTU

BO_ 1433 HVTU_SDO_Resp: 8 HVTU
 SG_ HVTU_SDO_RespCode : 12|4@1+ (1,0) [0|0] ""  TelemetryNode
 SG_ HVTU_SDO_ID M : 0|12@1+ (1,0) [0|4095] ""  TelemetryNode

BO_ 1497 HVTU_SDO_Req_Up: 8 TelemetryNode
 SG_ HVTU_SDO_ID M : 0|12@1+ (1,0) [0|4095] ""  HVTU

BO_ 1561 HVTU_SDO_Req_Down: 2 TelemetryNode
 SG_ HVTU_SDO_ID M : 0|12@1+ (1,0) [0|4095] ""  HVTU

BO_ 1817 HVTU_Heartbeat: 1 HVTU
 SG_ HVTU_NodeState : 0|8@1+ (1,0) [0|0] ""  Master,TelemetryNode

BO_ 1881 HVTU_BTL_TX: 8 HVTU

BO_ 1945 HVTU_BTL_RX: 8 TelemetryNode

BO_ 162 TelemetryNode_EMCY: 4 TelemetryNode

BO_ 418 TelemetryNode_TX_PDO1: 0 TelemetryNode

BO_ 482 TelemetryNode_RX_Shutdown: 1 Vector__XXX
 SG_ TelemetryNode_RX_Shutdown : 0|8@1+ (1,0) [0|0] "" Vector__XXX

BO_ 546 TelemetryNode_TX_PDO2: 0 TelemetryNode

BO_ 610 TelemetryNode_RX_PDO2: 0 Vector__XXX

BO_ 674 TelemetryNode_TX_PDO3: 0 TelemetryNode

BO_ 738 TelemetryNode_RX_PDO3: 0 Vector__XXX

BO_ 802 TelemetryNode_TX_PDO4: 0 TelemetryNode

BO_ 866 TelemetryNode_RX_PDO4: 0 Vector__XXX

BO_ 930 TelemetryNode_TX_PDO5: 0 TelemetryNode

BO_ 994 TelemetryNode_TX_PDO6: 0 TelemetryNode

BO_ 1058 TelemetryNode_TX_PDO7: 0 TelemetryNode

BO_ 1122 TelemetryNode_TX_PDO8: 0 TelemetryNode

BO_ 1186 TelemetryNode_TX_PDO9: 0 TelemetryNode

BO_ 1250 TelemetryNode_TX_PDO10: 0 TelemetryNode

BO_ 1314 TelemetryNode_TX_CAN_Error: 6 TelemetryNode
 SG_ TelemetryNode_CAN2_TxErrors : 38|10@1+ (1,0) [0|4095] "" Vector__XXX
 SG_ TelemetryNode_CAN2_RxErrors : 24|14@1+ (1,0) [0|16383] "" Vector__XXX
 SG_ TelemetryNode_CAN1_TxErrors : 14|10@1+ (1,0) [0|4095] "" Vector__XXX
 SG_ TelemetryNode_CAN1_RxErrors : 0|14@1+ (1,0) [0|16383] "" Vector__XXX

BO_ 1378 TelemetryNode_TX_Info: 7 TelemetryNode
 SG_ TelemetryNode_Date : 36|18@1+ (1,20200000) [20200000|20462143] "" Vector__XXX
 SG_ TelemetryNode_Time : 18|18@1+ (1,0) [0|262143] "" Vector__XXX
 SG_ TelemetryNode_Temperature : 10|8@1+ (0.4,-10) [-10|92] "°C" Vector__XXX
 SG_ TelemetryNode_CpuUsage : 0|10@1+ (0.1,0) [0|102.3] "%" Vector__XXX

BO_ 1442 TelemetryNode_SDO_Resp: 8 TelemetryNode
 SG_ TelemetryNode_SDO_RespCode : 12|4@1+ (1,0) [0|0] ""  TelemetryNode
 SG_ TelemetryNode_SDO_ID M : 0|12@1+ (1,0) [0|4095] ""  TelemetryNode

BO_ 1506 TelemetryNode_SDO_Req_Up: 8 TelemetryNode
 SG_ TelemetryNode_SDO_ID M : 0|12@1+ (1,0) [0|4095] ""  TelemetryNode

BO_ 1570 TelemetryNode_SDO_Req_Down: 2 TelemetryNode
 SG_ TelemetryNode_SDO_ID M : 0|12@1+ (1,0) [0|4095] ""  TelemetryNode

BO_ 1826 TelemetryNode_Heartbeat: 1 TelemetryNode
 SG_ TelemetryNode_NodeState : 0|8@1+ (1,0) [0|0] ""  SensorF,Master,TelemetryNode

BO_ 1890 TelemetryNode_BTL_TX: 8 TelemetryNode

BO_ 1954 TelemetryNode_BTL_RX: 8 TelemetryNode

BO_ 161 MDB1_EMCY: 4 MDB1

BO_ 417 MDB1_TX_PDO1: 0 MDB1

BO_ 481 MDB1_RX_PDO1: 0 Vector__XXX

BO_ 545 MDB1_TX_PDO2: 0 MDB1

BO_ 609 MDB1_RX_PDO2: 0 Vector__XXX

BO_ 673 MDB1_TX_PDO3: 0 MDB1

BO_ 737 MDB1_RX_PDO3: 0 Vector__XXX

BO_ 801 MDB1_TX_PDO4: 0 MDB1

BO_ 865 MDB1_RX_PDO4: 0 Vector__XXX

BO_ 929 MDB1_TX_PDO5: 0 MDB1

BO_ 993 MDB1_TX_PDO6: 0 MDB1

BO_ 1057 MDB1_TX_PDO7: 0 MDB1

BO_ 1121 MDB1_TX_PDO8: 0 MDB1

BO_ 1185 MDB1_TX_PDO9: 0 MDB1

BO_ 1249 MDB1_TX_PDO10: 0 MDB1

BO_ 1313 MDB1_TX_PDO11: 0 MDB1

BO_ 1377 MDB1_TX_PDO12: 0 MDB1

BO_ 1441 MDB1_SDO_Resp: 8 MDB1
 SG_ MDB1_SDO_RespCode : 12|4@1+ (1,0) [0|0] ""  TelemetryNode
 SG_ MDB1_SDO_ID M : 0|12@1+ (1,0) [0|4095] ""  TelemetryNode

BO_ 1505 MDB1_SDO_Req_Up: 8 TelemetryNode
 SG_ MDB1_SDO_ID M : 0|12@1+ (1,0) [0|4095] ""  MDB1

BO_ 1569 MDB1_SDO_Req_Down: 2 TelemetryNode
 SG_ MDB1_SDO_ID M : 0|12@1+ (1,0) [0|4095] ""  MDB1

BO_ 1825 MDB1_Heartbeat: 1 MDB1
 SG_ MDB1_NodeState : 0|8@1+ (1,0) [0|0] ""  Master,TelemetryNode

BO_ 1889 MDB1_BTL_TX: 8 MDB1

BO_ 1953 MDB1_BTL_RX: 8 TelemetryNode

BO_ 163 MDB2_EMCY: 4 MDB2

BO_ 419 MDB2_TX_PDO1: 0 MDB2

BO_ 483 MDB2_RX_PDO1: 0 Vector__XXX

BO_ 547 MDB2_TX_PDO2: 0 MDB2

BO_ 611 MDB2_RX_PDO2: 0 Vector__XXX

BO_ 675 MDB2_TX_PDO3: 0 MDB2

BO_ 739 MDB2_RX_PDO3: 0 Vector__XXX

BO_ 803 MDB2_TX_PDO4: 0 MDB2

BO_ 867 MDB2_RX_PDO4: 0 Vector__XXX

BO_ 931 MDB2_TX_PDO5: 0 MDB2

BO_ 995 MDB2_TX_PDO6: 0 MDB2

BO_ 1059 MDB2_TX_PDO7: 0 MDB2

BO_ 1123 MDB2_TX_PDO8: 0 MDB2

BO_ 1187 MDB2_TX_PDO9: 0 MDB2

BO_ 1251 MDB2_TX_PDO10: 0 MDB2

BO_ 1315 MDB2_TX_PDO11: 0 MDB2

BO_ 1379 MDB2_TX_PDO12: 0 MDB2

BO_ 1443 MDB2_SDO_Resp: 8 MDB2
 SG_ MDB2_SDO_RespCode : 12|4@1+ (1,0) [0|0] ""  TelemetryNode
 SG_ MDB2_SDO_ID M : 0|12@1+ (1,0) [0|4095] ""  TelemetryNode

BO_ 1507 MDB2_SDO_Req_Up: 8 TelemetryNode
 SG_ MDB2_SDO_ID M : 0|12@1+ (1,0) [0|4095] ""  MDB2

BO_ 1571 MDB2_SDO_Req_Down: 2 TelemetryNode
 SG_ MDB2_SDO_ID M : 0|12@1+ (1,0) [0|4095] ""  MDB2

BO_ 1827 MDB2_Heartbeat: 1 MDB2
 SG_ MDB2_NodeState : 0|8@1+ (1,0) [0|0] ""  Master,TelemetryNode

BO_ 1891 MDB2_BTL_TX: 8 MDB2

BO_ 1955 MDB2_BTL_RX: 8 TelemetryNode

BO_ 167 MDB3_EMCY: 4 MDB3

BO_ 423 MDB3_TX_PDO1: 0 MDB3

BO_ 487 MDB3_RX_PDO1: 0 Vector__XXX

BO_ 551 MDB3_TX_PDO2: 0 MDB3

BO_ 615 MDB3_RX_PDO2: 0 Vector__XXX

BO_ 679 MDB3_TX_PDO3: 0 MDB3

BO_ 743 MDB3_RX_PDO3: 0 Vector__XXX

BO_ 807 MDB3_TX_PDO4: 0 MDB3

BO_ 871 MDB3_RX_PDO4: 0 Vector__XXX

BO_ 935 MDB3_TX_PDO5: 0 MDB3

BO_ 999 MDB3_TX_PDO6: 0 MDB3

BO_ 1063 MDB3_TX_PDO7: 0 MDB3

BO_ 1127 MDB3_TX_PDO8: 0 MDB3

BO_ 1191 MDB3_TX_PDO9: 0 MDB3

BO_ 1255 MDB3_TX_PDO10: 0 MDB3

BO_ 1319 MDB3_TX_PDO11: 0 MDB3

BO_ 1383 MDB3_TX_PDO12: 0 MDB3

BO_ 1447 MDB3_SDO_Resp: 8 MDB3
 SG_ MDB3_SDO_RespCode : 12|4@1+ (1,0) [0|0] ""  TelemetryNode
 SG_ MDB3_SDO_ID M : 0|12@1+ (1,0) [0|4095] ""  TelemetryNode

BO_ 1511 MDB3_SDO_Req_Up: 8 TelemetryNode
 SG_ MDB3_SDO_ID M : 0|12@1+ (1,0) [0|4095] ""  MDB3

BO_ 1575 MDB3_SDO_Req_Down: 2 TelemetryNode
 SG_ MDB3_SDO_ID M : 0|12@1+ (1,0) [0|4095] ""  MDB3

BO_ 1831 MDB3_Heartbeat: 1 MDB3
 SG_ MDB3_NodeState : 0|8@1+ (1,0) [0|0] ""  Master,TelemetryNode

BO_ 1895 MDB3_BTL_TX: 8 MDB3

BO_ 1959 MDB3_BTL_RX: 8 TelemetryNode

BO_ 168 MDB4_EMCY: 4 MDB4

BO_ 424 MDB4_TX_PDO1: 0 MDB4

BO_ 488 MDB4_RX_PDO1: 0 Vector__XXX

BO_ 552 MDB4_TX_PDO2: 0 MDB4

BO_ 616 MDB4_RX_PDO2: 0 Vector__XXX

BO_ 680 MDB4_TX_PDO3: 0 MDB4

BO_ 744 MDB4_RX_PDO3: 0 Vector__XXX

BO_ 808 MDB4_TX_PDO4: 0 MDB4

BO_ 872 MDB4_RX_PDO4: 0 Vector__XXX

BO_ 936 MDB4_TX_PDO5: 0 MDB4

BO_ 1000 MDB4_TX_PDO6: 0 MDB4

BO_ 1064 MDB4_TX_PDO7: 0 MDB4

BO_ 1128 MDB4_TX_PDO8: 0 MDB4

BO_ 1192 MDB4_TX_PDO9: 0 MDB4

BO_ 1256 MDB4_TX_PDO10: 0 MDB4

BO_ 1320 MDB4_TX_PDO11: 0 MDB4

BO_ 1384 MDB4_TX_PDO12: 0 MDB4

BO_ 1448 MDB4_SDO_Resp: 8 MDB4
 SG_ MDB4_SDO_RespCode : 12|4@1+ (1,0) [0|0] ""  TelemetryNode
 SG_ MDB4_SDO_ID M : 0|12@1+ (1,0) [0|4095] ""  TelemetryNode

BO_ 1512 MDB4_SDO_Req_Up: 8 TelemetryNode
 SG_ MDB4_SDO_ID M : 0|12@1+ (1,0) [0|4095] ""  MDB4

BO_ 1576 MDB4_SDO_Req_Down: 2 TelemetryNode
 SG_ MDB4_SDO_ID M : 0|12@1+ (1,0) [0|4095] ""  MDB4

BO_ 1832 MDB4_Heartbeat: 1 MDB4
 SG_ MDB4_NodeState : 0|8@1+ (1,0) [0|0] ""  Master,TelemetryNode

BO_ 1896 MDB4_BTL_TX: 8 MDB4

BO_ 1960 MDB4_BTL_RX: 8 TelemetryNode

BO_ 169 MDB5_EMCY: 4 MDB5

BO_ 425 MDB5_TX_PDO1: 0 MDB5

BO_ 489 MDB5_RX_PDO1: 0 Vector__XXX

BO_ 553 MDB5_TX_PDO2: 0 MDB5

BO_ 617 MDB5_RX_PDO2: 0 Vector__XXX

BO_ 681 MDB5_TX_PDO3: 0 MDB5

BO_ 745 MDB5_RX_PDO3: 0 Vector__XXX

BO_ 809 MDB5_TX_PDO4: 0 MDB5

BO_ 873 MDB5_RX_PDO4: 0 Vector__XXX

BO_ 937 MDB5_TX_PDO5: 0 MDB5

BO_ 1001 MDB5_TX_PDO6: 0 MDB5

BO_ 1065 MDB5_TX_PDO7: 0 MDB5

BO_ 1129 MDB5_TX_PDO8: 0 MDB5

BO_ 1193 MDB5_TX_PDO9: 0 MDB5

BO_ 1257 MDB5_TX_PDO10: 0 MDB5

BO_ 1321 MDB5_TX_PDO11: 0 MDB5

BO_ 1385 MDB5_TX_PDO12: 0 MDB5

BO_ 1449 MDB5_SDO_Resp: 8 MDB5
 SG_ MDB5_SDO_RespCode : 12|4@1+ (1,0) [0|0] ""  TelemetryNode
 SG_ MDB5_SDO_ID M : 0|12@1+ (1,0) [0|4095] ""  TelemetryNode

BO_ 1513 MDB5_SDO_Req_Up: 8 TelemetryNode
 SG_ MDB5_SDO_ID M : 0|12@1+ (1,0) [0|4095] ""  MDB5

BO_ 1577 MDB5_SDO_Req_Down: 2 TelemetryNode
 SG_ MDB5_SDO_ID M : 0|12@1+ (1,0) [0|4095] ""  MDB5

BO_ 1833 MDB5_Heartbeat: 1 MDB5
 SG_ MDB5_NodeState : 0|8@1+ (1,0) [0|0] ""  Master,TelemetryNode

BO_ 1897 MDB5_BTL_TX: 8 MDB5

BO_ 1961 MDB5_BTL_RX: 8 TelemetryNode

BO_ 177 MDB6_EMCY: 4 MDB6

BO_ 433 MDB6_TX_PDO1: 0 MDB6

BO_ 497 MDB6_RX_PDO1: 0 Vector__XXX

BO_ 561 MDB6_TX_PDO2: 0 MDB6

BO_ 625 MDB6_RX_PDO2: 0 Vector__XXX

BO_ 689 MDB6_TX_PDO3: 0 MDB6

BO_ 753 MDB6_RX_PDO3: 0 Vector__XXX

BO_ 817 MDB6_TX_PDO4: 0 MDB6

BO_ 881 MDB6_RX_PDO4: 0 Vector__XXX

BO_ 945 MDB6_TX_PDO5: 0 MDB6

BO_ 1009 MDB6_TX_PDO6: 0 MDB6

BO_ 1073 MDB6_TX_PDO7: 0 MDB6

BO_ 1137 MDB6_TX_PDO8: 0 MDB6

BO_ 1201 MDB6_TX_PDO9: 0 MDB6

BO_ 1265 MDB6_TX_PDO10: 0 MDB6

BO_ 1329 MDB6_TX_PDO11: 0 MDB6

BO_ 1393 MDB6_TX_PDO12: 0 MDB6

BO_ 1457 MDB6_SDO_Resp: 8 MDB6
 SG_ MDB6_SDO_RespCode : 12|4@1+ (1,0) [0|0] ""  TelemetryNode
 SG_ MDB6_SDO_ID M : 0|12@1+ (1,0) [0|4095] ""  TelemetryNode

BO_ 1521 MDB6_SDO_Req_Up: 8 TelemetryNode
 SG_ MDB6_SDO_ID M : 0|12@1+ (1,0) [0|4095] ""  MDB6

BO_ 1585 MDB6_SDO_Req_Down: 2 TelemetryNode
 SG_ MDB6_SDO_ID M : 0|12@1+ (1,0) [0|4095] ""  MDB6

BO_ 1841 MDB6_Heartbeat: 1 MDB6
 SG_ MDB6_NodeState : 0|8@1+ (1,0) [0|0] ""  Master,TelemetryNode

BO_ 1905 MDB6_BTL_TX: 8 MDB6

BO_ 1969 MDB6_BTL_RX: 8 TelemetryNode

BO_ 178 Track_EMCY: 4 Track

BO_ 434 Track_TX_PDO1: 0 Track

BO_ 498 Track_RX_PDO1: 0 Vector__XXX

BO_ 562 Track_TX_PDO2: 0 Track

BO_ 626 Track_RX_PDO2: 0 Vector__XXX

BO_ 690 Track_TX_PDO3: 0 Track

BO_ 754 Track_RX_PDO3: 0 Vector__XXX

BO_ 818 Track_TX_PDO4: 0 Track

BO_ 882 Track_RX_PDO4: 0 Vector__XXX

BO_ 946 Track_TX_PDO5: 0 Track

BO_ 1010 Track_TX_PDO6: 0 Track

BO_ 1074 Track_TX_PDO7: 0 Track

BO_ 1138 Track_TX_PDO8: 0 Track

BO_ 1202 Track_TX_PDO9: 0 Track

BO_ 1266 Track_TX_PDO10: 0 Track

BO_ 1330 Track_TX_PDO11: 0 Track

BO_ 1394 Track_TX_PDO12: 0 Track

BO_ 1458 Track_SDO_Resp: 8 Track
 SG_ Track_SDO_RespCode : 12|4@1+ (1,0) [0|0] ""  TelemetryNode
 SG_ Track_SDO_ID M : 0|12@1+ (1,0) [0|4095] ""  TelemetryNode

BO_ 1522 Track_SDO_Req_Up: 8 TelemetryNode
 SG_ Track_SDO_ID M : 0|12@1+ (1,0) [0|4095] ""  Track

BO_ 1586 Track_SDO_Req_Down: 2 TelemetryNode
 SG_ Track_SDO_ID M : 0|12@1+ (1,0) [0|4095] ""  Track

BO_ 1842 Track_Heartbeat: 1 Track
 SG_ Track_NodeState : 0|8@1+ (1,0) [0|0] ""  Master,TelemetryNode

BO_ 1906 Track_BTL_TX: 8 Track

BO_ 1970 Track_BTL_RX: 8 TelemetryNode

BO_ 148 CLU_EMCY: 4 CLU

BO_ 404 CLU_TX_PDO1: 0 CLU

BO_ 468 CLU_RX_PDO1: 0 Vector__XXX

BO_ 532 CLU_TX_PDO2: 0 CLU

BO_ 596 CLU_RX_PDO2: 0 Vector__XXX

BO_ 660 CLU_TX_PDO3: 0 CLU

BO_ 724 CLU_RX_PDO3: 0 Vector__XXX

BO_ 788 CLU_TX_PDO4: 0 CLU

BO_ 852 CLU_RX_PDO4: 0 Vector__XXX

BO_ 916 CLU_TX_PDO5: 0 CLU

BO_ 980 CLU_TX_PDO6: 0 CLU

BO_ 1044 CLU_TX_PDO7: 0 CLU

BO_ 1108 CLU_TX_PDO8: 0 CLU

BO_ 1172 CLU_TX_PDO9: 0 CLU

BO_ 1236 CLU_TX_PDO10: 0 CLU

BO_ 1300 CLU_TX_PDO11: 0 CLU

BO_ 1364 CLU_TX_PDO12: 0 CLU

BO_ 1428 CLU_SDO_Resp: 8 CLU
 SG_ CLU_SDO_RespCode : 12|4@1+ (1,0) [0|0] ""  TelemetryNode
 SG_ CLU_SDO_ID M : 0|12@1+ (1,0) [0|4095] ""  TelemetryNode

BO_ 1492 CLU_SDO_Req_Up: 8 TelemetryNode
 SG_ CLU_SDO_ID M : 0|12@1+ (1,0) [0|4095] ""  CLU

BO_ 1556 CLU_SDO_Req_Down: 2 TelemetryNode
 SG_ CLU_SDO_ID M : 0|12@1+ (1,0) [0|4095] ""  CLU

BO_ 1812 CLU_Heartbeat: 1 CLU
 SG_ CLU_NodeState : 0|8@1+ (1,0) [0|0] ""  SensorF,Master,TelemetryNode

BO_ 1876 CLU_BTL_TX: 8 CLU

BO_ 1940 CLU_BTL_RX: 8 TelemetryNode

CM_ BU_ OpticalSensor "Kistler SFP-II optical Sensor.";
CM_ BU_ EMUS_BMS "HV BMS ";
CM_ BU_ TelemetryNode "Gateway between Pod and Telemetry
Node-ID 0x22Gateway between Pod and Telemetry
Node-ID 0x22";
CM_ BU_ Master "CANzero NMT Master Node.";
CM_ BU_ SensorF "SensorECU
Node-ID 0x1";
CM_ BU_ SensorR "SensorECUR
Node-ID 0x2";
CM_ BU_ BrakeF "BrakeECU Front
Node-ID 0x11";
CM_ BU_ BrakeR "BrakeECUR
Node-ID 0x12";
CM_ BU_ PDU "PowerD
Node-ID 0x1A";
CM_ BU_ HVCU "HVController
Node-ID 0xA";
CM_ BU_ HVTU "High Voltage CAN Translation Unit between BMS and Pod
Node-ID 0x19";
CM_ BU_ MDB1 "ModularLevitationUnit-1
Node-ID 0x21";
CM_ BU_ MDB2 "ModularLevitationUnit-2
Node-ID 0x23";
CM_ BU_ MDB3 "ModularLevitationUnit-3
Node-ID 0x27";
CM_ BU_ MDB4 "ModularLevitationUnit-4
Node-ID 0x28";
CM_ BU_ MDB5 "ModularLevitationUnit-5
Node-ID 0x29";
CM_ BU_ MDB6 "ModularLevitationUnit-6
Node-ID 0x31";
CM_ BU_ Track "TrackECU
Node-ID 0x32";
CM_ BU_ CLU "central levitation unit
Node-ID 0x14";
CM_ SG_ 274 MDB3_Current "as binary IEEE-754
";
CM_ SG_ 295 MDB6_Current "as binary IEEE-754
";
CM_ SG_ 297 MDB6_Temperature "as binary IEEE-754";
CM_ SG_ 294 MDB6_AirGap "as binary IEEE-754
";
CM_ SG_ 292 MDB5_Temperature "as binary IEEE-754";
CM_ SG_ 290 MDB5_Current "as binary IEEE-754
";
CM_ SG_ 289 MDB5_AirGap "as binary IEEE-754
";
CM_ SG_ 281 MDB4_Temperature "as binary IEEE-754";
CM_ SG_ 279 MDB4_Current "as binary IEEE-754
";
CM_ SG_ 278 MDB4_AirGap "as binary IEEE-754
";
CM_ SG_ 276 MDB3_Temperature "as binary IEEE-754";
CM_ SG_ 273 MDB3_AirGap "as binary IEEE-754
";
CM_ SG_ 265 MDB2_Temperature "as binary IEEE-754";
CM_ SG_ 263 MDB2_Current "as binary IEEE-754
";
CM_ SG_ 262 MDB2_AirGap "as binary IEEE-754
";
CM_ SG_ 258 MDB1_Current "as binary IEEE-754
";
CM_ SG_ 260 MDB1_Temperature "as binary IEEE-754";
CM_ SG_ 257 MDB1_AirGap "as binary IEEE-754
";
CM_ BO_ 2684354555 "longitudinal and transverse velocity, angle between them";
CM_ SG_ 2684354555 OpticalSensor_TX_Angle "Angle between longitudianl and transverse direction.";
CM_ SG_ 2684354555 OpticalSensor_TX_VelTrans "Velocity in transverse direction.";
CM_ SG_ 2684354555 OpticalSensor_TX_VelLong "Velocity in longitudinal direction.";
CM_ BO_ 2684354554 "Timestamp, Veocity, Distance";
CM_ SG_ 2684354554 OpticalSensor_TX_Distance "Traveled distance";
CM_ SG_ 2684354554 OpticalSensor_TX_Vel "Absolute velocity";
CM_ BO_ 2684354556 "Timestamp, Veocity, Distance";
CM_ SG_ 2684354556 OpticalSensor_TX_Temp "Temperature of the sensor";
CM_ SG_ 2684354556 OpticalSensor_TX_SerialNo "Serialnumber of the sensor";
CM_ BO_ 2 "CANzero NMT message sent by NMT master.";
CM_ SG_ 2 CANzero_NMT_Node "CANzero NMT Node-ID of master request.";
CM_ SG_ 2 CANzero_NMT_State "CANzero NMT State Request by master.";
CM_ BO_ 122 "CANzero Sync message. Not used yet, just a placeholder for future versions.";
CM_ BO_ 123 "CANzero Timestamp message. Not used yet, just a placeholder for future versions.";
CM_ BO_ 129 "Emergency message of node SensorF with Node-ID 0x1";
CM_ BO_ 385 "Transmit PDO 1 of node SensorF with Node-ID 0x1";
CM_ SG_ 385 SensorF_TX_PodState "PodState by State Machine.";
CM_ BO_ 449 "Receive PDO 1 of node SensorF with Node-ID 0x1";
CM_ BO_ 513 "Data from Encoder front (PDO10)";
CM_ BO_ 577 "Receive PDO 2 of node SensorF with Node-ID 0x1.";
CM_ BO_ 641 "Transmit PDO 3 of node SensorF with Node-ID 0x1";
CM_ BO_ 705 "Receive PDO 3 of node SensorF with Node-ID 0x1.";
CM_ BO_ 769 "Transmit PDO 4 of node SensorF with Node-ID 0x1";
CM_ BO_ 833 "Receive PDO 4 of node SensorF with Node-ID 0x1.";
CM_ BO_ 897 "Transmit PDO 5 of node SensorF with Node-ID 0x1";
CM_ BO_ 961 "Transmit PDO 6 of node SensorF with Node-ID 0x1";
CM_ BO_ 1025 "Transmit PDO 7 of node SensorF with Node-ID 0x1";
CM_ SG_ 1025 SensorF_GyroFront_X "Slope of front IMU in X direction.";
CM_ SG_ 1025 SensorF_Vel_EncoderFront "Velocity of Wheel Encoder front.";
CM_ SG_ 1025 SensorF_Pos_EncoderFront "Position of Wheel Encoder front.";
CM_ BO_ 1089 "Transmit PDO 8 of node SensorF with Node-ID 0x1";
CM_ BO_ 1153 "Transmit PDO 9 of node SensorF with Node-ID 0x1";
CM_ BO_ 1217 "Transmit Acc_X, Acc_Y, Acc_Z and Gyro_Z of front IMU of node SensorF.";
CM_ SG_ 1217 SensorF_GyroFront_Z "Slope of front IMU in Z direction.";
CM_ SG_ 1217 SensorF_AccFront_Z "Acceleration of front IMU in Z direction.";
CM_ SG_ 1217 SensorF_AccFront_Y "Acceleration of front IMU in Y direction.";
CM_ SG_ 1217 SensorF_AccFront_X "Acceleration of front IMU in X direction.";
CM_ BO_ 1281 "SensorF with Node-ID 0x1 (PDO11).";
CM_ BO_ 1345 "Transmit PDO 12 of node SensorF with Node-ID 0x1.";
CM_ BO_ 1409 "DO NOT CHANGE ANYTHING HERE!
SDO Response of node SensorF with Node-ID 0x1";
CM_ SG_ 1409 SensorF_SDO_RespCode "Response code of SDO access.";
CM_ SG_ 1409 SensorF_SDO_ID "Specifies SDO-ID of SensorF";
CM_ BO_ 1473 "DO NOT CHANGE ANYTHING HERE!
SDO Request Upload to node SensorF with Node-ID 0x1";
CM_ SG_ 1473 SensorF_SDO_ID "Specifies SDO-ID of SensorF";
CM_ BO_ 1537 "DO NOT CHANGE ANYTHING HERE!
SDO Request Download from node SensorF with Node-ID 0x1";
CM_ SG_ 1537 SensorF_SDO_ID "Specifies SDO-ID of SensorF";
CM_ BO_ 1793 "Heartbeat of node SensorF with Node-ID 0x1";
CM_ SG_ 1793 SensorF_NodeState "Heartbeat status of node SensorF";
CM_ BO_ 1857 "Bootloader transmit from node SensorF with Node-ID 0x1";
CM_ BO_ 1921 "Bootloader receive by node SensorF with Node-ID 0x1";
CM_ BO_ 130 "Emergency message of node SensorR with Node-ID 0x2";
CM_ BO_ 386 "Transmit PDO 1 of node SensorR with Node-ID 0x2. Data of front IMU.";
CM_ SG_ 386 SensorR_TX_GyroFront_Z "Slope of front IMU in Z direction.";
CM_ SG_ 386 SensorR_TX_AccFront_Z "Acceleration of front IMU in Z direction.";
CM_ SG_ 386 SensorR_TX_AccFront_Y "Acceleration of front IMU in Y direction.";
CM_ SG_ 386 SensorR_TX_AccFront_X "Acceleration of front IMU in X direction.";
CM_ BO_ 514 "Transmit PDO 2 of node SensorR with Node-ID 0x2. RunState, Enabled, ErrorFlag, TrajectorySet";
CM_ SG_ 514 SensorR_TX_ErrorFlag "Error status of SensorR.";
CM_ SG_ 514 SensorR_TX_Enabled "Enable status of SensorR.";
CM_ SG_ 514 SensorR_TX_TrajectorySet "Flag for trajectorySet";
CM_ SG_ 514 SensorR_TX_RunState "State of run of SensorR.";
CM_ BO_ 578 "Receive PDO 2 of node SensorR with Node-ID 0x2.";
CM_ BO_ 642 "Transmit PDO 3 of node SensorR with Node-ID 0x2. Filtered data after StateEstimation";
CM_ SG_ 642 SensorR_TX_Pos "Filtered position by StateEstimation.";
CM_ SG_ 642 SensorR_TX_Vel "Filtered velocity by StateEstimation.";
CM_ SG_ 642 SensorR_TX_Acc "Filtered acceleration by StateEstimation.";
CM_ BO_ 706 "Receive PDO 3 of node SensorR with Node-ID 0x2";
CM_ SG_ 706 SensorR_RX_ErrorReset "Error reset signal for SensorR.";
CM_ SG_ 706 SensorR_RX_Enable "Enable signal for SensorR.";
CM_ SG_ 706 SensorR_RX_LaunchComm "Launch Command of SensorR.";
CM_ BO_ 770 "Transmit PDO 4 of node SensorR with Node-ID 0x2. Velocity of EncoderFront, rear and optical, Stripes";
CM_ SG_ 770 SensorR_TX_Vel_Optical "Velocity of optical Sensor.";
CM_ SG_ 770 SensorR_TX_Vel_EncoderRear "Velocity of Wheel Encoder rear.";
CM_ SG_ 770 SensorR_TX_Vel_EncoderFront "Velocity of Wheel Encoder front.";
CM_ BO_ 834 "Receive PDO 4 of node SensorR with Node-ID 0x2.";
CM_ BO_ 898 "Transmit PDO 5 of node SensorR with Node-ID 0x2. Gyroscope data of IMU front and rear in X and Y direction.";
CM_ SG_ 898 SensorR_TX_GyroRear_Y "Slope of rear IMU in Y direction.";
CM_ SG_ 898 SensorR_TX_GyroRear_X "Slope of rear IMU in X direction.";
CM_ SG_ 898 SensorR_TX_GyroFront_Y "Slope of front IMU in Y direction.";
CM_ SG_ 898 SensorR_TX_GyroFront_X "Slope of front IMU in X direction.";
CM_ BO_ 962 "Transmit PDO 6 of node SensorR with Node-ID 0x2";
CM_ BO_ 1026 "Transmit PDO 7 of node SensorR with Node-ID 0x2. Gap Height of left and right sensor.";
CM_ SG_ 1026 SensorR_TX_GapHeight_Right "Gap height of LIM right.";
CM_ SG_ 1026 SensorR_TX_GapHeight_Left "Gap height of LIM left.";
CM_ BO_ 1090 "Transmit PDO 8 of node SensorR with Node-ID 0x2";
CM_ BO_ 1154 "Transmit PDO 9 of node SensorR with Node-ID 0x2";
CM_ BO_ 1218 "Transmit PDO 10 of node SensorR with Node-ID 0x2. Send acceleration of IMU Rear.";
CM_ SG_ 1218 SensorR_TX_GyroRear_Z "Slope of rear IMU in Z direction.";
CM_ SG_ 1218 SensorR_TX_AccRear_Z "Acceleration of rear IMU in Z direction.";
CM_ SG_ 1218 SensorR_TX_AccRear_Y "Acceleration of rear IMU in Y direction.";
CM_ SG_ 1218 SensorR_TX_AccRear_X "Acceleration of rear IMU in X direction.";
CM_ BO_ 1282 "Transmit PDO 11 of node SensorR with Node-ID 0x2. Send position data of Encoder front, rear and optical and Stripes.";
CM_ SG_ 1282 SensorR_TX_StripeCounter_Right "Counting reflectors on the right site.";
CM_ SG_ 1282 SensorR_TX_StripeCounter_Left "Counting reflectors on the left site.";
CM_ SG_ 1282 SensorR_TX_Pos_Optical "Position of optical Sensor.";
CM_ SG_ 1282 SensorR_TX_Pos_EncoderRear "Position of Wheel Encoder rear.";
CM_ SG_ 1282 SensorR_TX_Pos_EncoderFront "Position of Wheel Encoder front.";
CM_ BO_ 1346 "Transmit PDO 12 of node SensorR with Node-ID 0x2.";
CM_ BO_ 1410 "DO NOT CHANGE ANYTHING HERE!
SDO Response of node SensorR with Node-ID 0x2";
CM_ SG_ 1410 SensorR_SDO_RespCode "Response code of SDO access.";
CM_ SG_ 1410 SensorR_SDO_ID "Specifies SDO-ID of SensorR";
CM_ BO_ 1474 "DO NOT CHANGE ANYTHING HERE!
SDO Request Upload to node SensorR with Node-ID 0x2";
CM_ SG_ 1474 SensorR_SDO_ID "Specifies SDO-ID of SensorR";
CM_ BO_ 1538 "DO NOT CHANGE ANYTHING HERE!
SDO Request Download from node SensorR with Node-ID 0x2";
CM_ SG_ 1538 SensorR_SDO_ID "Specifies SDO-ID of SensorR";
CM_ BO_ 1794 "Heartbeat of node SensorR with Node-ID 0x2";
CM_ SG_ 1794 SensorR_NodeState "Heartbeat status of node SensorR";
CM_ BO_ 1858 "Bootloader transmit from node SensorR with Node-ID 0x2";
CM_ BO_ 1922 "Bootloader receive by node SensorR with Node-ID 0x2";
CM_ BO_ 145 "Emergency message of node BrakeF with Node-ID 0x11";
CM_ BO_ 401 "Transmit PDO 1 of node BrakeF with Node-ID 0x11";
CM_ SG_ 401 BrakeF_TX_SDC_Input "Sends the current value of the SDC received by BrakeF.
";
CM_ SG_ 401 BrakeF_TX_ErrorFlag "Error status of BrakeF.";
CM_ SG_ 401 BrakeF_TX_Enabled "Enable status of BrakeF.";
CM_ SG_ 401 BrakeF_TX_Status "Status signal of BrakeF.";
CM_ BO_ 465 "Receive PDO 1 of node BrakeF with Node-ID 0x11";
CM_ SG_ 465 BrakeF_RX_Engage "Engage signal for BrakeF.";
CM_ SG_ 465 BrakeF_RX_Enable "Enable signal for BrakeF.";
CM_ SG_ 465 BrakeF_RX_ErrorReset "Error reset signal for BrakeF.";
CM_ BO_ 529 "Transmit PDO 2 of node BrakeF with Node-ID 0x11";
CM_ BO_ 593 "Receive PDO 2 of node BrakeF with Node-ID 0x11";
CM_ BO_ 657 "Transmit PDO 3 of node BrakeF with Node-ID 0x11";
CM_ BO_ 721 "Receive PDO 3 of node BrakeF with Node-ID 0x11";
CM_ BO_ 785 "Transmit PDO 4 of node BrakeF with Node-ID 0x11";
CM_ BO_ 849 "Receive PDO 4 of node BrakeF with Node-ID 0x11";
CM_ BO_ 913 "Transmit PDO 5 of node BrakeF with Node-ID 0x11";
CM_ BO_ 977 "Transmit PDO 6 of node BrakeF with Node-ID 0x11";
CM_ BO_ 1105 "Transmit PDO 8 of node BrakeF with Node-ID 0x11";
CM_ BO_ 1169 "Transmit PDO 9 of node BrakeF with Node-ID 0x11";
CM_ BO_ 1233 "Transmit PDO 10 of node BrakeF with Node-ID 0x11";
CM_ BO_ 1297 "Transmit PDO 11 of node BrakeF with Node-ID 0x11";
CM_ BO_ 1361 "Transmit PDO 12 of node BrakeF with Node-ID 0x11";
CM_ BO_ 1425 "DO NOT CHANGE ANYTHING HERE!
SDO Response of node BrakeF with Node-ID 0x11";
CM_ SG_ 1425 BrakeF_SDO_RespCode "Response code of SDO access.";
CM_ SG_ 1425 BrakeF_SDO_ID "Specifies SDO-ID of BrakeF";
CM_ BO_ 1489 "DO NOT CHANGE ANYTHING HERE!
SDO Request Upload to node BrakeF with Node-ID 0x11";
CM_ SG_ 1489 BrakeF_SDO_ID "Specifies SDO-ID of BrakeF";
CM_ BO_ 1553 "DO NOT CHANGE ANYTHING HERE!
SDO Request Download from node BrakeF with Node-ID 0x11";
CM_ SG_ 1553 BrakeF_SDO_ID "Specifies SDO-ID of BrakeF";
CM_ BO_ 1809 "Heartbeat of node BrakeF with Node-ID 0x11";
CM_ SG_ 1809 BrakeF_NodeState "Heartbeat status of node BrakeF";
CM_ BO_ 1873 "Bootloader transmit from node BrakeF with Node-ID 0x11";
CM_ BO_ 1937 "Bootloader receive by node BrakeF with Node-ID 0x11";
CM_ BO_ 146 "Emergency message of node BrakeR with Node-ID 0x12";
CM_ BO_ 402 "Transmit PDO 1 of node BrakeR with Node-ID 0x12";
CM_ SG_ 402 BrakeR_TX_SDC_Input "Sends the current value of the SDC received by BrakeR.
";
CM_ SG_ 402 BrakeR_TX_ErrorFlag "Error status of BrakeR.";
CM_ SG_ 402 BrakeR_TX_Enabled "Enable status of BrakeR.";
CM_ SG_ 402 BrakeR_TX_Status "Status signal of BrakeR.";
CM_ BO_ 466 "Receive PDO 1 of node BrakeR with Node-ID 0x12";
CM_ SG_ 466 BrakeR_RX_Engage "Engage signal for BrakeR.";
CM_ SG_ 466 BrakeR_RX_Enable "Enable signal for BrakeR.";
CM_ SG_ 466 BrakeR_RX_ErrorReset "Error reset signal for BrakeR.";
CM_ BO_ 530 "Transmit PDO 2 of node BrakeR with Node-ID 0x12";
CM_ BO_ 594 "Receive PDO 2 of node BrakeR with Node-ID 0x12";
CM_ BO_ 658 "Transmit PDO 3 of node BrakeR with Node-ID 0x12";
CM_ BO_ 722 "Receive PDO 3 of node BrakeR with Node-ID 0x12";
CM_ BO_ 786 "Transmit PDO 4 of node BrakeR with Node-ID 0x12";
CM_ BO_ 850 "Receive PDO 4 of node BrakeR with Node-ID 0x12";
CM_ BO_ 914 "Transmit PDO 5 of node BrakeR with Node-ID 0x12";
CM_ BO_ 978 "Transmit PDO 6 of node BrakeR with Node-ID 0x12";
CM_ BO_ 1042 "Transmit PDO 7 of node BrakeR with Node-ID 0x12";
CM_ BO_ 1106 "Transmit PDO 8 of node BrakeR with Node-ID 0x12";
CM_ BO_ 1170 "Transmit PDO 9 of node BrakeR with Node-ID 0x12";
CM_ BO_ 1234 "Transmit PDO 10 of node BrakeR with Node-ID 0x12";
CM_ BO_ 1298 "Transmit PDO 11 of node BrakeR with Node-ID 0x12";
CM_ BO_ 1362 "Transmit PDO 12 of node BrakeR with Node-ID 0x12";
CM_ BO_ 1426 "DO NOT CHANGE ANYTHING HERE!
SDO Response of node BrakeR with Node-ID 0x12";
CM_ SG_ 1426 BrakeR_SDO_RespCode "Response code of SDO access.";
CM_ SG_ 1426 BrakeR_SDO_ID "Specifies SDO-ID of BrakeR";
CM_ BO_ 1490 "DO NOT CHANGE ANYTHING HERE!
SDO Request Upload to node BrakeR with Node-ID 0x12";
CM_ SG_ 1490 BrakeR_SDO_ID "Specifies SDO-ID of BrakeR";
CM_ BO_ 1554 "DO NOT CHANGE ANYTHING HERE!
SDO Request Download from node BrakeR with Node-ID 0x12";
CM_ SG_ 1554 BrakeR_SDO_ID "Specifies SDO-ID of BrakeR";
CM_ BO_ 1810 "Heartbeat of node BrakeR with Node-ID 0x12";
CM_ SG_ 1810 BrakeR_NodeState "Heartbeat status of node BrakeR";
CM_ BO_ 1874 "Bootloader transmit from node BrakeR with Node-ID 0x12";
CM_ BO_ 1938 "Bootloader receive by node BrakeR with Node-ID 0x12";
CM_ BO_ 154 "Emergency message of node PDU with Node-ID 0x1A";
CM_ BO_ 410 "Transmit PDO 1 of node PDU with Node-ID 0x1A";
CM_ SG_ 410 PDU_TX_PEHWEnabled "PE Hardware Enable status signal of PDU.";
CM_ SG_ 410 PDU_TX_ErrorFlag "Error status of PDU.";
CM_ SG_ 410 PDU_TX_Enabled "Enable status of PDU.";
CM_ BO_ 474 "Control message of the PDU sent by the State Machine.";
CM_ SG_ 474 PDU_RX_PEHWEnable "PE Hardware Enable signal of PDU.";
CM_ SG_ 474 PDU_RX_ErrorReset "Error reset signal for PDU.";
CM_ SG_ 474 PDU_RX_Enable "Enable signal for PDU.";
CM_ BO_ 538 "Transmit PDO 2 of node PDU with Node-ID 0x1A";
CM_ BO_ 602 "Dutycycle for the channels of the PDU that support PWM.";
CM_ BO_ 666 "Transmit PDO 3 of node PDU with Node-ID 0x1A";
CM_ BO_ 730 "Receive PDO 3 of node PDU with Node-ID 0x1A";
CM_ BO_ 794 "Transmit PDO 4 of node PDU with Node-ID 0x1A";
CM_ BO_ 858 "Receive PDO 4 of node PDU with Node-ID 0x1A";
CM_ BO_ 922 "Transmit PDO 5 of node PDU with Node-ID 0x1A";
CM_ BO_ 986 "Transmit PDO 6 of node PDU with Node-ID 0x1A";
CM_ BO_ 1050 "Transmit PDO 7 of node PDU with Node-ID 0x1A";
CM_ BO_ 1114 "Transmit PDO 8 of node PDU with Node-ID 0x1A";
CM_ BO_ 1178 "Transmit PDO 9 of node PDU with Node-ID 0x1A";
CM_ BO_ 1242 "Transmit PDO 10 of node PDU with Node-ID 0x1A";
CM_ BO_ 1306 "Transmit PDO 11 of node PDU with Node-ID 0x1A";
CM_ BO_ 1370 "Transmit PDO 12 of node PDU with Node-ID 0x1A";
CM_ BO_ 1434 "DO NOT CHANGE ANYTHING HERE!
SDO Response of node PDU with Node-ID 0x1A";
CM_ SG_ 1434 PDU_SDO_RespCode "Response code of SDO access.";
CM_ SG_ 1434 PDU_SDO_ID "Specifies SDO-ID of PDU";
CM_ BO_ 1498 "DO NOT CHANGE ANYTHING HERE!
SDO Request Upload to node PDU with Node-ID 0x1A";
CM_ SG_ 1498 PDU_SDO_ID "Specifies SDO-ID of PDU";
CM_ BO_ 1562 "DO NOT CHANGE ANYTHING HERE!
SDO Request Download from node PDU with Node-ID 0x1A";
CM_ SG_ 1562 PDU_SDO_ID "Specifies SDO-ID of PDU";
CM_ BO_ 1818 "Heartbeat of node PDU with Node-ID 0x1A";
CM_ SG_ 1818 PDU_NodeState "Heartbeat status of node PDU";
CM_ BO_ 1882 "Bootloader transmit from node PDU with Node-ID 0x1A";
CM_ BO_ 1946 "Bootloader receive by node PDU with Node-ID 0x1A";
CM_ BO_ 138 "Emergency message of node HVCU with Node-ID 0xA";
CM_ BO_ 394 "Transmit PDO 1 of node HVCU with Node-ID 0xA";
CM_ SG_ 394 HVCU_TX_Enabled "Enable status of HVCU.";
CM_ SG_ 394 HVCU_TX_ErrorFlag "Error status of HVCU.";
CM_ SG_ 394 HVCU_TX_Status "HVCU status signal.";
CM_ SG_ 394 HVCU_TX_InternalStatus "HVCU internal status signal. For Debug.";
CM_ BO_ 458 "Receive PDO 1 of node HVCU with Node-ID 0xA";
CM_ SG_ 458 HVCU_RX_Charging "HVCU Charging signal for HV system.";
CM_ SG_ 458 HVCU_RX_ErrorReset "Error reset signal for HVCU.";
CM_ SG_ 458 HVCU_RX_Activate "HVCU Activate signal for HV system.";
CM_ SG_ 458 HVCU_RX_Enable "Enable signal for HVCU.";
CM_ BO_ 522 "Transmit PDO 2 of node HVCU with Node-ID 0xA";
CM_ BO_ 586 "Receive PDO 2 of node HVCU with Node-ID 0xA";
CM_ BO_ 650 "Transmit PDO 3 of node HVCU with Node-ID 0xA";
CM_ BO_ 714 "Receive PDO 3 of node HVCU with Node-ID 0xA";
CM_ BO_ 778 "Transmit PDO 4 of node HVCU with Node-ID 0xA";
CM_ BO_ 842 "Receive PDO 4 of node HVCU with Node-ID 0xA";
CM_ BO_ 906 "Transmit PDO 5 of node HVCU with Node-ID 0xA";
CM_ BO_ 970 "Transmit PDO 6 of node HVCU with Node-ID 0xA";
CM_ BO_ 1034 "Transmit PDO 7 of node HVCU with Node-ID 0xA";
CM_ BO_ 1098 "Transmit PDO 8 of node HVCU with Node-ID 0xA";
CM_ BO_ 1162 "Transmit PDO 9 of node HVCU with Node-ID 0xA";
CM_ BO_ 1226 "Transmit PDO 10 of node HVCU with Node-ID 0xA";
CM_ BO_ 1290 "Transmit PDO 11 of node HVCU with Node-ID 0xA";
CM_ BO_ 1354 "Transmit PDO 12 of node HVCU with Node-ID 0xA";
CM_ BO_ 1418 "DO NOT CHANGE ANYTHING HERE!
SDO Response of node HVCU with Node-ID 0xA";
CM_ SG_ 1418 HVCU_SDO_RespCode "Response code of SDO access.";
CM_ SG_ 1418 HVCU_SDO_ID "Specifies SDO-ID of HVCU";
CM_ BO_ 1482 "DO NOT CHANGE ANYTHING HERE!
SDO Request Upload to node HVCU with Node-ID 0xA";
CM_ SG_ 1482 HVCU_SDO_ID "Specifies SDO-ID of HVCU";
CM_ BO_ 1546 "DO NOT CHANGE ANYTHING HERE!
SDO Request Download from node HVCU with Node-ID 0xA";
CM_ SG_ 1546 HVCU_SDO_ID "Specifies SDO-ID of HVCU";
CM_ BO_ 1802 "Heartbeat of node HVCU with Node-ID 0xA";
CM_ SG_ 1802 HVCU_NodeState "Heartbeat status of node HVCU";
CM_ BO_ 1866 "Bootloader transmit from node HVCU with Node-ID 0xA";
CM_ BO_ 1930 "Bootloader receive by node HVCU with Node-ID 0xA";
CM_ BO_ 153 "Emergency message of node HVTU with Node-ID 0x19";
CM_ BO_ 1299 "Control signals to control the SciMo PE with the mz control model implemented on the SciMo hardware (Vf and If control).

";
CM_ BO_ 409 "Transmit PDO 1 of node HVTU with Node-ID 0x19";
CM_ BO_ 473 "Receive PDO 1 of node HVTU with Node-ID 0x19";
CM_ BO_ 537 "Transmit PDO 2 of node HVTU with Node-ID 0x19";
CM_ BO_ 601 "Receive PDO 2 of node HVTU with Node-ID 0x19";
CM_ BO_ 665 "Transmit PDO 3 of node HVTU with Node-ID 0x19";
CM_ BO_ 729 "Receive PDO 3 of node HVTU with Node-ID 0x19";
CM_ BO_ 793 "Transmit PDO 4 of node HVTU with Node-ID 0x19";
CM_ BO_ 857 "Receive PDO 4 of node HVTU with Node-ID 0x19";
CM_ BO_ 921 "Transmit PDO 5 of node HVTU with Node-ID 0x19";
CM_ BO_ 985 "Transmit PDO 6 of node HVTU with Node-ID 0x19";
CM_ BO_ 1049 "Transmit PDO 7 of node HVTU with Node-ID 0x19";
CM_ BO_ 1113 "Transmit PDO 8 of node HVTU with Node-ID 0x19";
CM_ BO_ 1177 "Transmit PDO 9 of node HVTU with Node-ID 0x19";
CM_ BO_ 1241 "Transmit PDO 10 of node HVTU with Node-ID 0x19";
CM_ BO_ 1305 "Transmit PDO 11 of node HVTU with Node-ID 0x19";
CM_ BO_ 1369 "Transmit PDO 12 of node HVTU with Node-ID 0x19";
CM_ BO_ 1433 "DO NOT CHANGE ANYTHING HERE!
SDO Response of node HVTU with Node-ID 0x19";
CM_ SG_ 1433 HVTU_SDO_RespCode "Response code of SDO access.";
CM_ SG_ 1433 HVTU_SDO_ID "Specifies SDO-ID of HVTU";
CM_ BO_ 1497 "DO NOT CHANGE ANYTHING HERE!
SDO Request Upload to node HVTU with Node-ID 0x19";
CM_ SG_ 1497 HVTU_SDO_ID "Specifies SDO-ID of HVTU";
CM_ BO_ 1561 "DO NOT CHANGE ANYTHING HERE!
SDO Request Download from node HVTU with Node-ID 0x19";
CM_ SG_ 1561 HVTU_SDO_ID "Specifies SDO-ID of HVTU";
CM_ BO_ 1817 "Heartbeat of node HVTU with Node-ID 0x19";
CM_ SG_ 1817 HVTU_NodeState "Heartbeat status of node HVTU";
CM_ BO_ 1881 "Bootloader transmit from node HVTU with Node-ID 0x19";
CM_ BO_ 1945 "Bootloader receive by node HVTU with Node-ID 0x19";
CM_ BO_ 162 "Emergency message of node TelemetryNode with Node-ID 0x22";
CM_ BO_ 418 "Transmit PDO 1 of node TelemetryNode with Node-ID 0x22";
CM_ BO_ 482 "Receive PDO 1 of node TelemetryNode with Node-ID 0x22";
CM_ BO_ 546 "Transmit PDO 2 of node TelemetryNode with Node-ID 0x22";
CM_ BO_ 610 "Receive PDO 2 of node TelemetryNode with Node-ID 0x22";
CM_ BO_ 674 "Transmit PDO 3 of node TelemetryNode with Node-ID 0x22";
CM_ BO_ 738 "Receive PDO 3 of node TelemetryNode with Node-ID 0x22";
CM_ BO_ 802 "Transmit PDO 4 of node TelemetryNode with Node-ID 0x22";
CM_ BO_ 866 "Receive PDO 4 of node TelemetryNode with Node-ID 0x22";
CM_ BO_ 930 "Transmit PDO 5 of node TelemetryNode with Node-ID 0x22";
CM_ BO_ 994 "Transmit PDO 6 of node TelemetryNode with Node-ID 0x22";
CM_ BO_ 1058 "Transmit PDO 7 of node TelemetryNode with Node-ID 0x22";
CM_ BO_ 1122 "Transmit PDO 8 of node TelemetryNode with Node-ID 0x22";
CM_ BO_ 1186 "Transmit PDO 9 of node TelemetryNode with Node-ID 0x22";
CM_ BO_ 1250 "Transmit PDO 10 of node TelemetryNode with Node-ID 0x22";
CM_ BO_ 1314 "Transmit PDO 11 of node TelemetryNode with Node-ID 0x22";
CM_ BO_ 1378 "Transmit PDO 12 of node TelemetryNode with Node-ID 0x22";
CM_ BO_ 1442 "DO NOT CHANGE ANYTHING HERE!
SDO Response of node TelemetryNode with Node-ID 0x22";
CM_ SG_ 1442 TelemetryNode_SDO_RespCode "Response code of SDO access.";
CM_ SG_ 1442 TelemetryNode_SDO_ID "Specifies SDO-ID of TelemetryNode";
CM_ BO_ 1506 "DO NOT CHANGE ANYTHING HERE!
SDO Request Upload to node TelemetryNode with Node-ID 0x22";
CM_ SG_ 1506 TelemetryNode_SDO_ID "Specifies SDO-ID of TelemetryNode";
CM_ BO_ 1570 "DO NOT CHANGE ANYTHING HERE!
SDO Request Download from node TelemetryNode with Node-ID 0x22";
CM_ SG_ 1570 TelemetryNode_SDO_ID "Specifies SDO-ID of TelemetryNode";
CM_ BO_ 1826 "Heartbeat of node TelemetryNode with Node-ID 0x22";
CM_ SG_ 1826 TelemetryNode_NodeState "Heartbeat status of node TelemetryNode";
CM_ BO_ 1890 "Bootloader transmit from node TelemetryNode with Node-ID 0x22";
CM_ BO_ 1954 "Bootloader receive by node TelemetryNode with Node-ID 0x22";
CM_ BO_ 161 "Emergency message of node MDB1 with Node-ID 0x21";
CM_ BO_ 417 "Transmit PDO 1 of node MDB1 with Node-ID 0x21";
CM_ BO_ 481 "Receive PDO 1 of node MDB1 with Node-ID 0x21";
CM_ BO_ 545 "Transmit PDO 2 of node MDB1 with Node-ID 0x21";
CM_ BO_ 609 "Receive PDO 2 of node MDB1 with Node-ID 0x21";
CM_ BO_ 673 "Transmit PDO 3 of node MDB1 with Node-ID 0x21";
CM_ BO_ 737 "Receive PDO 3 of node MDB1 with Node-ID 0x21";
CM_ BO_ 801 "Transmit PDO 4 of node MDB1 with Node-ID 0x21";
CM_ BO_ 865 "Receive PDO 4 of node MDB1 with Node-ID 0x21";
CM_ BO_ 929 "Transmit PDO 5 of node MDB1 with Node-ID 0x21";
CM_ BO_ 993 "Transmit PDO 6 of node MDB1 with Node-ID 0x21";
CM_ BO_ 1057 "Transmit PDO 7 of node MDB1 with Node-ID 0x21";
CM_ BO_ 1121 "Transmit PDO 8 of node MDB1 with Node-ID 0x21";
CM_ BO_ 1185 "Transmit PDO 9 of node MDB1 with Node-ID 0x21";
CM_ BO_ 1249 "Transmit PDO 10 of node MDB1 with Node-ID 0x21";
CM_ BO_ 1313 "Transmit PDO 11 of node MDB1 with Node-ID 0x21";
CM_ BO_ 1377 "Transmit PDO 12 of node MDB1 with Node-ID 0x21";
CM_ BO_ 1441 "DO NOT CHANGE ANYTHING HERE!
SDO Response of node MDB1 with Node-ID 0x21";
CM_ SG_ 1441 MDB1_SDO_RespCode "Response code of SDO access.";
CM_ SG_ 1441 MDB1_SDO_ID "Specifies SDO-ID of MDB1";
CM_ BO_ 1505 "DO NOT CHANGE ANYTHING HERE!
SDO Request Upload to node MDB1 with Node-ID 0x21";
CM_ SG_ 1505 MDB1_SDO_ID "Specifies SDO-ID of MDB1";
CM_ BO_ 1569 "DO NOT CHANGE ANYTHING HERE!
SDO Request Download from node MDB1 with Node-ID 0x21";
CM_ SG_ 1569 MDB1_SDO_ID "Specifies SDO-ID of MDB1";
CM_ BO_ 1825 "Heartbeat of node MDB1 with Node-ID 0x21";
CM_ SG_ 1825 MDB1_NodeState "Heartbeat status of node MDB1";
CM_ BO_ 1889 "Bootloader transmit from node MDB1 with Node-ID 0x21";
CM_ BO_ 1953 "Bootloader receive by node MDB1 with Node-ID 0x21";
CM_ BO_ 163 "Emergency message of node MDB2 with Node-ID 0x23";
CM_ BO_ 419 "Transmit PDO 1 of node MDB2 with Node-ID 0x23";
CM_ BO_ 483 "Receive PDO 1 of node MDB2 with Node-ID 0x23";
CM_ BO_ 547 "Transmit PDO 2 of node MDB2 with Node-ID 0x23";
CM_ BO_ 611 "Receive PDO 2 of node MDB2 with Node-ID 0x23";
CM_ BO_ 675 "Transmit PDO 3 of node MDB2 with Node-ID 0x23";
CM_ BO_ 739 "Receive PDO 3 of node MDB2 with Node-ID 0x23";
CM_ BO_ 803 "Transmit PDO 4 of node MDB2 with Node-ID 0x23";
CM_ BO_ 867 "Receive PDO 4 of node MDB2 with Node-ID 0x23";
CM_ BO_ 931 "Transmit PDO 5 of node MDB2 with Node-ID 0x23";
CM_ BO_ 995 "Transmit PDO 6 of node MDB2 with Node-ID 0x23";
CM_ BO_ 1059 "Transmit PDO 7 of node MDB2 with Node-ID 0x23";
CM_ BO_ 1123 "Transmit PDO 8 of node MDB2 with Node-ID 0x23";
CM_ BO_ 1187 "Transmit PDO 9 of node MDB2 with Node-ID 0x23";
CM_ BO_ 1251 "Transmit PDO 10 of node MDB2 with Node-ID 0x23";
CM_ BO_ 1315 "Transmit PDO 11 of node MDB2 with Node-ID 0x23";
CM_ BO_ 1379 "Transmit PDO 12 of node MDB2 with Node-ID 0x23";
CM_ BO_ 1443 "DO NOT CHANGE ANYTHING HERE!
SDO Response of node MDB2 with Node-ID 0x23";
CM_ SG_ 1443 MDB2_SDO_RespCode "Response code of SDO access.";
CM_ SG_ 1443 MDB2_SDO_ID "Specifies SDO-ID of MDB2";
CM_ BO_ 1507 "DO NOT CHANGE ANYTHING HERE!
SDO Request Upload to node MDB2 with Node-ID 0x23";
CM_ SG_ 1507 MDB2_SDO_ID "Specifies SDO-ID of MDB2";
CM_ BO_ 1571 "DO NOT CHANGE ANYTHING HERE!
SDO Request Download from node MDB2 with Node-ID 0x23";
CM_ SG_ 1571 MDB2_SDO_ID "Specifies SDO-ID of MDB2";
CM_ BO_ 1827 "Heartbeat of node MDB2 with Node-ID 0x23";
CM_ SG_ 1827 MDB2_NodeState "Heartbeat status of node MDB2";
CM_ BO_ 1891 "Bootloader transmit from node MDB2 with Node-ID 0x23";
CM_ BO_ 1955 "Bootloader receive by node MDB2 with Node-ID 0x23";
CM_ BO_ 167 "Emergency message of node MDB3 with Node-ID 0x27";
CM_ BO_ 423 "Transmit PDO 1 of node MDB3 with Node-ID 0x27";
CM_ BO_ 487 "Receive PDO 1 of node MDB3 with Node-ID 0x27";
CM_ BO_ 551 "Transmit PDO 2 of node MDB3 with Node-ID 0x27";
CM_ BO_ 615 "Receive PDO 2 of node MDB3 with Node-ID 0x27";
CM_ BO_ 679 "Transmit PDO 3 of node MDB3 with Node-ID 0x27";
CM_ BO_ 743 "Receive PDO 3 of node MDB3 with Node-ID 0x27";
CM_ BO_ 807 "Transmit PDO 4 of node MDB3 with Node-ID 0x27";
CM_ BO_ 871 "Receive PDO 4 of node MDB3 with Node-ID 0x27";
CM_ BO_ 935 "Transmit PDO 5 of node MDB3 with Node-ID 0x27";
CM_ BO_ 999 "Transmit PDO 6 of node MDB3 with Node-ID 0x27";
CM_ BO_ 1063 "Transmit PDO 7 of node MDB3 with Node-ID 0x27";
CM_ BO_ 1127 "Transmit PDO 8 of node MDB3 with Node-ID 0x27";
CM_ BO_ 1191 "Transmit PDO 9 of node MDB3 with Node-ID 0x27";
CM_ BO_ 1255 "Transmit PDO 10 of node MDB3 with Node-ID 0x27";
CM_ BO_ 1319 "Transmit PDO 11 of node MDB3 with Node-ID 0x27";
CM_ BO_ 1383 "Transmit PDO 12 of node MDB3 with Node-ID 0x27";
CM_ BO_ 1447 "DO NOT CHANGE ANYTHING HERE!
SDO Response of node MDB3 with Node-ID 0x27";
CM_ SG_ 1447 MDB3_SDO_RespCode "Response code of SDO access.";
CM_ SG_ 1447 MDB3_SDO_ID "Specifies SDO-ID of MDB3";
CM_ BO_ 1511 "DO NOT CHANGE ANYTHING HERE!
SDO Request Upload to node MDB3 with Node-ID 0x27";
CM_ SG_ 1511 MDB3_SDO_ID "Specifies SDO-ID of MDB3";
CM_ BO_ 1575 "DO NOT CHANGE ANYTHING HERE!
SDO Request Download from node MDB3 with Node-ID 0x27";
CM_ SG_ 1575 MDB3_SDO_ID "Specifies SDO-ID of MDB3";
CM_ BO_ 1831 "Heartbeat of node MDB3 with Node-ID 0x27";
CM_ SG_ 1831 MDB3_NodeState "Heartbeat status of node MDB3";
CM_ BO_ 1895 "Bootloader transmit from node MDB3 with Node-ID 0x27";
CM_ BO_ 1959 "Bootloader receive by node MDB3 with Node-ID 0x27";
CM_ BO_ 168 "Emergency message of node MDB4 with Node-ID 0x28";
CM_ BO_ 424 "Transmit PDO 1 of node MDB4 with Node-ID 0x28";
CM_ BO_ 488 "Receive PDO 1 of node MDB4 with Node-ID 0x28";
CM_ BO_ 552 "Transmit PDO 2 of node MDB4 with Node-ID 0x28";
CM_ BO_ 616 "Receive PDO 2 of node MDB4 with Node-ID 0x28";
CM_ BO_ 680 "Transmit PDO 3 of node MDB4 with Node-ID 0x28";
CM_ BO_ 744 "Receive PDO 3 of node MDB4 with Node-ID 0x28";
CM_ BO_ 808 "Transmit PDO 4 of node MDB4 with Node-ID 0x28";
CM_ BO_ 872 "Receive PDO 4 of node MDB4 with Node-ID 0x28";
CM_ BO_ 936 "Transmit PDO 5 of node MDB4 with Node-ID 0x28";
CM_ BO_ 1000 "Transmit PDO 6 of node MDB4 with Node-ID 0x28";
CM_ BO_ 1064 "Transmit PDO 7 of node MDB4 with Node-ID 0x28";
CM_ BO_ 1128 "Transmit PDO 8 of node MDB4 with Node-ID 0x28";
CM_ BO_ 1192 "Transmit PDO 9 of node MDB4 with Node-ID 0x28";
CM_ BO_ 1256 "Transmit PDO 10 of node MDB4 with Node-ID 0x28";
CM_ BO_ 1320 "Transmit PDO 11 of node MDB4 with Node-ID 0x28";
CM_ BO_ 1384 "Transmit PDO 12 of node MDB4 with Node-ID 0x28";
CM_ BO_ 1448 "DO NOT CHANGE ANYTHING HERE!
SDO Response of node MDB4 with Node-ID 0x28";
CM_ SG_ 1448 MDB4_SDO_RespCode "Response code of SDO access.";
CM_ SG_ 1448 MDB4_SDO_ID "Specifies SDO-ID of MDB4";
CM_ BO_ 1512 "DO NOT CHANGE ANYTHING HERE!
SDO Request Upload to node MDB4 with Node-ID 0x28";
CM_ SG_ 1512 MDB4_SDO_ID "Specifies SDO-ID of MDB4";
CM_ BO_ 1576 "DO NOT CHANGE ANYTHING HERE!
SDO Request Download from node MDB4 with Node-ID 0x28";
CM_ SG_ 1576 MDB4_SDO_ID "Specifies SDO-ID of MDB4";
CM_ BO_ 1832 "Heartbeat of node MDB4 with Node-ID 0x28";
CM_ SG_ 1832 MDB4_NodeState "Heartbeat status of node MDB4";
CM_ BO_ 1896 "Bootloader transmit from node MDB4 with Node-ID 0x28";
CM_ BO_ 1960 "Bootloader receive by node MDB4 with Node-ID 0x28";
CM_ BO_ 169 "Emergency message of node MDB5 with Node-ID 0x29";
CM_ BO_ 425 "Transmit PDO 1 of node MDB5 with Node-ID 0x29";
CM_ BO_ 489 "Receive PDO 1 of node MDB5 with Node-ID 0x29";
CM_ BO_ 553 "Transmit PDO 2 of node MDB5 with Node-ID 0x29";
CM_ BO_ 617 "Receive PDO 2 of node MDB5 with Node-ID 0x29";
CM_ BO_ 681 "Transmit PDO 3 of node MDB5 with Node-ID 0x29";
CM_ BO_ 745 "Receive PDO 3 of node MDB5 with Node-ID 0x29";
CM_ BO_ 809 "Transmit PDO 4 of node MDB5 with Node-ID 0x29";
CM_ BO_ 873 "Receive PDO 4 of node MDB5 with Node-ID 0x29";
CM_ BO_ 937 "Transmit PDO 5 of node MDB5 with Node-ID 0x29";
CM_ BO_ 1001 "Transmit PDO 6 of node MDB5 with Node-ID 0x29";
CM_ BO_ 1065 "Transmit PDO 7 of node MDB5 with Node-ID 0x29";
CM_ BO_ 1129 "Transmit PDO 8 of node MDB5 with Node-ID 0x29";
CM_ BO_ 1193 "Transmit PDO 9 of node MDB5 with Node-ID 0x29";
CM_ BO_ 1257 "Transmit PDO 10 of node MDB5 with Node-ID 0x29";
CM_ BO_ 1321 "Transmit PDO 11 of node MDB5 with Node-ID 0x29";
CM_ BO_ 1385 "Transmit PDO 12 of node MDB5 with Node-ID 0x29";
CM_ BO_ 1449 "DO NOT CHANGE ANYTHING HERE!
SDO Response of node MDB5 with Node-ID 0x29";
CM_ SG_ 1449 MDB5_SDO_RespCode "Response code of SDO access.";
CM_ SG_ 1449 MDB5_SDO_ID "Specifies SDO-ID of MDB5";
CM_ BO_ 1513 "DO NOT CHANGE ANYTHING HERE!
SDO Request Upload to node MDB5 with Node-ID 0x29";
CM_ SG_ 1513 MDB5_SDO_ID "Specifies SDO-ID of MDB5";
CM_ BO_ 1577 "DO NOT CHANGE ANYTHING HERE!
SDO Request Download from node MDB5 with Node-ID 0x29";
CM_ SG_ 1577 MDB5_SDO_ID "Specifies SDO-ID of MDB5";
CM_ BO_ 1833 "Heartbeat of node MDB5 with Node-ID 0x29";
CM_ SG_ 1833 MDB5_NodeState "Heartbeat status of node MDB5";
CM_ BO_ 1897 "Bootloader transmit from node MDB5 with Node-ID 0x29";
CM_ BO_ 1961 "Bootloader receive by node MDB5 with Node-ID 0x29";
CM_ BO_ 177 "Emergency message of node MDB6 with Node-ID 0x31";
CM_ BO_ 433 "Transmit PDO 1 of node MDB6 with Node-ID 0x31";
CM_ BO_ 497 "Receive PDO 1 of node MDB6 with Node-ID 0x31";
CM_ BO_ 561 "Transmit PDO 2 of node MDB6 with Node-ID 0x31";
CM_ BO_ 625 "Receive PDO 2 of node MDB6 with Node-ID 0x31";
CM_ BO_ 689 "Transmit PDO 3 of node MDB6 with Node-ID 0x31";
CM_ BO_ 753 "Receive PDO 3 of node MDB6 with Node-ID 0x31";
CM_ BO_ 817 "Transmit PDO 4 of node MDB6 with Node-ID 0x31";
CM_ BO_ 881 "Receive PDO 4 of node MDB6 with Node-ID 0x31";
CM_ BO_ 945 "Transmit PDO 5 of node MDB6 with Node-ID 0x31";
CM_ BO_ 1009 "Transmit PDO 6 of node MDB6 with Node-ID 0x31";
CM_ BO_ 1073 "Transmit PDO 7 of node MDB6 with Node-ID 0x31";
CM_ BO_ 1137 "Transmit PDO 8 of node MDB6 with Node-ID 0x31";
CM_ BO_ 1201 "Transmit PDO 9 of node MDB6 with Node-ID 0x31";
CM_ BO_ 1265 "Transmit PDO 10 of node MDB6 with Node-ID 0x31";
CM_ BO_ 1329 "Transmit PDO 11 of node MDB6 with Node-ID 0x31";
CM_ BO_ 1393 "Transmit PDO 12 of node MDB6 with Node-ID 0x31";
CM_ BO_ 1457 "DO NOT CHANGE ANYTHING HERE!
SDO Response of node MDB6 with Node-ID 0x31";
CM_ SG_ 1457 MDB6_SDO_RespCode "Response code of SDO access.";
CM_ SG_ 1457 MDB6_SDO_ID "Specifies SDO-ID of MDB6";
CM_ BO_ 1521 "DO NOT CHANGE ANYTHING HERE!
SDO Request Upload to node MDB6 with Node-ID 0x31";
CM_ SG_ 1521 MDB6_SDO_ID "Specifies SDO-ID of MDB6";
CM_ BO_ 1585 "DO NOT CHANGE ANYTHING HERE!
SDO Request Download from node MDB6 with Node-ID 0x31";
CM_ SG_ 1585 MDB6_SDO_ID "Specifies SDO-ID of MDB6";
CM_ BO_ 1841 "Heartbeat of node MDB6 with Node-ID 0x31";
CM_ SG_ 1841 MDB6_NodeState "Heartbeat status of node MDB6";
CM_ BO_ 1905 "Bootloader transmit from node MDB6 with Node-ID 0x31";
CM_ BO_ 1969 "Bootloader receive by node MDB6 with Node-ID 0x31";
CM_ BO_ 178 "Emergency message of node Track with Node-ID 0x32";
CM_ BO_ 434 "Transmit PDO 1 of node Track with Node-ID 0x32";
CM_ BO_ 498 "Receive PDO 1 of node Track with Node-ID 0x32";
CM_ BO_ 562 "Transmit PDO 2 of node Track with Node-ID 0x32";
CM_ BO_ 626 "Receive PDO 2 of node Track with Node-ID 0x32";
CM_ BO_ 690 "Transmit PDO 3 of node Track with Node-ID 0x32";
CM_ BO_ 754 "Receive PDO 3 of node Track with Node-ID 0x32";
CM_ BO_ 818 "Transmit PDO 4 of node Track with Node-ID 0x32";
CM_ BO_ 882 "Receive PDO 4 of node Track with Node-ID 0x32";
CM_ BO_ 946 "Transmit PDO 5 of node Track with Node-ID 0x32";
CM_ BO_ 1010 "Transmit PDO 6 of node Track with Node-ID 0x32";
CM_ BO_ 1074 "Transmit PDO 7 of node Track with Node-ID 0x32";
CM_ BO_ 1138 "Transmit PDO 8 of node Track with Node-ID 0x32";
CM_ BO_ 1202 "Transmit PDO 9 of node Track with Node-ID 0x32";
CM_ BO_ 1266 "Transmit PDO 10 of node Track with Node-ID 0x32";
CM_ BO_ 1330 "Transmit PDO 11 of node Track with Node-ID 0x32";
CM_ BO_ 1394 "Transmit PDO 12 of node Track with Node-ID 0x32";
CM_ BO_ 1458 "DO NOT CHANGE ANYTHING HERE!
SDO Response of node Track with Node-ID 0x32";
CM_ SG_ 1458 Track_SDO_RespCode "Response code of SDO access.";
CM_ SG_ 1458 Track_SDO_ID "Specifies SDO-ID of Track";
CM_ BO_ 1522 "DO NOT CHANGE ANYTHING HERE!
SDO Request Upload to node Track with Node-ID 0x32";
CM_ SG_ 1522 Track_SDO_ID "Specifies SDO-ID of Track";
CM_ BO_ 1586 "DO NOT CHANGE ANYTHING HERE!
SDO Request Download from node Track with Node-ID 0x32";
CM_ SG_ 1586 Track_SDO_ID "Specifies SDO-ID of Track";
CM_ BO_ 1842 "Heartbeat of node Track with Node-ID 0x32";
CM_ SG_ 1842 Track_NodeState "Heartbeat status of node Track";
CM_ BO_ 1906 "Bootloader transmit from node Track with Node-ID 0x32";
CM_ BO_ 1970 "Bootloader receive by node Track with Node-ID 0x32";
CM_ BO_ 148 "Emergency message of node CLU with Node-ID 0x14";
CM_ BO_ 404 "Transmit PDO 1 of node CLU with Node-ID 0x14";
CM_ BO_ 468 "Receive PDO 1 of node CLU with Node-ID 0x14";
CM_ BO_ 532 "Transmit PDO 2 of node CLU with Node-ID 0x14";
CM_ BO_ 596 "Receive PDO 2 of node CLU with Node-ID 0x14";
CM_ BO_ 660 "Transmit PDO 3 of node CLU with Node-ID 0x14";
CM_ BO_ 724 "Receive PDO 3 of node CLU with Node-ID 0x14";
CM_ BO_ 788 "Transmit PDO 4 of node CLU with Node-ID 0x14";
CM_ BO_ 852 "Receive PDO 4 of node CLU with Node-ID 0x14";
CM_ BO_ 916 "Transmit PDO 5 of node CLU with Node-ID 0x14";
CM_ BO_ 980 "Transmit PDO 6 of node CLU with Node-ID 0x14";
CM_ BO_ 1044 "Transmit PDO 7 of node CLU with Node-ID 0x14";
CM_ BO_ 1108 "Transmit PDO 8 of node CLU with Node-ID 0x14";
CM_ BO_ 1172 "Transmit PDO 9 of node CLU with Node-ID 0x14";
CM_ BO_ 1236 "Transmit PDO 10 of node CLU with Node-ID 0x14";
CM_ BO_ 1300 "Transmit PDO 11 of node CLU with Node-ID 0x14";
CM_ BO_ 1364 "Transmit PDO 12 of node CLU with Node-ID 0x14";
CM_ BO_ 1428 "DO NOT CHANGE ANYTHING HERE!
SDO Response of node CLU with Node-ID 0x14";
CM_ SG_ 1428 CLU_SDO_RespCode "Response code of SDO access.";
CM_ SG_ 1428 CLU_SDO_ID "Specifies SDO-ID of CLU";
CM_ BO_ 1492 "DO NOT CHANGE ANYTHING HERE!
SDO Request Upload to node CLU with Node-ID 0x14";
CM_ SG_ 1492 CLU_SDO_ID "Specifies SDO-ID of CLU";
CM_ BO_ 1556 "DO NOT CHANGE ANYTHING HERE!
SDO Request Download from node CLU with Node-ID 0x14";
CM_ SG_ 1556 CLU_SDO_ID "Specifies SDO-ID of CLU";
CM_ BO_ 1812 "Heartbeat of node CLU with Node-ID 0x14";
CM_ SG_ 1812 CLU_NodeState "Heartbeat status of node CLU";
CM_ BO_ 1876 "Bootloader transmit from node CLU with Node-ID 0x14";
CM_ BO_ 1940 "Bootloader receive by node CLU with Node-ID 0x14";
BA_DEF_ SG_  "GenSigSendType" ENUM  "Cyclic","OnWrite","OnWriteWithRepetition","OnChange","OnChangeWithRepetition","IfActive","IfActiveWithRepetition","NoSigSendType";
BA_DEF_ BO_  "GenMsgSendType" ENUM  "Cyclic","not_used","not_used","not_used","not_used","Cyclic","not_used","IfActive","NoMsgSendType";
BA_DEF_  "BusType" STRING ;
BA_DEF_  "DBName" STRING ;
BA_DEF_ BO_  "GenMsgCycleTime" INT 2 50000;
BA_DEF_ BO_  "GenMsgDelayTime" INT 1 1000;
BA_DEF_ BO_  "GenMsgNrOfRepetitions" INT 1 999999;
BA_DEF_ SG_  "GenSigStartValue" FLOAT 0 100000000000;
BA_DEF_  "CANzero_ProtocolVersion" STRING ;
BA_DEF_  "CANzero_DBCVersion" INT 0 16777215;
BA_DEF_  "CANzero_SDOClientName" STRING ;
BA_DEF_  "CANzero_NMTMasterName" STRING ;
BA_DEF_ BU_  "CANzero_NodeID" HEX 0 63;
BA_DEF_ SG_  "CANzero_SDO_AccessType" ENUM  "Read Write","Read Only","Write Only";
BA_DEF_ SG_  "SystemSignalLongSymbol" STRING ;
BA_DEF_DEF_  "GenSigSendType" "Cyclic";
BA_DEF_DEF_  "GenMsgSendType" "NoMsgSendType";
BA_DEF_DEF_  "BusType" "";
BA_DEF_DEF_  "DBName" "";
BA_DEF_DEF_  "GenMsgCycleTime" 100;
BA_DEF_DEF_  "GenMsgDelayTime" 1;
BA_DEF_DEF_  "GenMsgNrOfRepetitions" 1;
BA_DEF_DEF_  "GenSigStartValue" 0;
BA_DEF_DEF_  "CANzero_ProtocolVersion" "";
BA_DEF_DEF_  "CANzero_DBCVersion" 0;
BA_DEF_DEF_  "CANzero_SDOClientName" "Master";
BA_DEF_DEF_  "CANzero_NMTMasterName" "Master";
BA_DEF_DEF_  "CANzero_NodeID" 0;
BA_DEF_DEF_  "CANzero_SDO_AccessType" "Read Write";
BA_DEF_DEF_  "SystemSignalLongSymbol" "";
BA_ "BusType" "CAN";
BA_ "CANzero_ProtocolVersion" "V1.0";
BA_ "CANzero_DBCVersion" 263;
BA_ "CANzero_SDOClientName" "TelemetryNode";
BA_ "DBName" "pod2022";
BA_ "CANzero_NodeID" BU_ TelemetryNode 34;
BA_ "CANzero_NodeID" BU_ SensorF 1;
BA_ "CANzero_NodeID" BU_ SensorR 2;
BA_ "CANzero_NodeID" BU_ BrakeF 17;
BA_ "CANzero_NodeID" BU_ BrakeR 18;
BA_ "CANzero_NodeID" BU_ PDU 26;
BA_ "CANzero_NodeID" BU_ HVCU 10;
BA_ "CANzero_NodeID" BU_ HVTU 25;
BA_ "CANzero_NodeID" BU_ MDB1 33;
BA_ "CANzero_NodeID" BU_ MDB2 35;
BA_ "CANzero_NodeID" BU_ MDB3 39;
BA_ "CANzero_NodeID" BU_ MDB4 40;
BA_ "CANzero_NodeID" BU_ MDB5 41;
BA_ "CANzero_NodeID" BU_ MDB6 49;
BA_ "CANzero_NodeID" BU_ Track 50;
BA_ "CANzero_NodeID" BU_ CLU 20;
BA_ "GenSigStartValue" SG_ 1041 BrakeF_TX_Pressure_Reservoir 400;
BA_ "GenSigStartValue" SG_ 1089 SensorF_TX_BatteryTemp 600;
BA_ "GenSigStartValue" SG_ 1153 SensorF_Cooling_Temp 600;
BA_ "GenSigStartValue" SG_ 1153 SensorF_LIMT_Stator_4 266.666666666667;
BA_ "GenSigStartValue" SG_ 1153 SensorF_LIMT_Stator_3 266.666666666667;
BA_ "GenSigStartValue" SG_ 1153 SensorF_LIMT_Stator_2 266.666666666667;
BA_ "GenSigStartValue" SG_ 1153 SensorF_LIMT_Stator_1 266.666666666667;
BA_ "GenSigStartValue" SG_ 1154 SensorR_LIMT_Coil_3 50;
BA_ "GenSigStartValue" SG_ 1154 SensorR_LIMT_Coil_2 50;
BA_ "GenSigStartValue" SG_ 1154 SensorR_LIMT_Coil_1 50;
BA_ "GenSigStartValue" SG_ 1106 BrakeR_TX_Pressure_Tank 400;
BA_ "GenSigStartValue" SG_ 1106 BrakeR_TX_Pressure_Retract 400;
BA_ "GenSigStartValue" SG_ 1106 BrakeR_TX_Pressure_Act 400;
BA_ "GenSigStartValue" SG_ 602 PDU_LPCh9_Dutycycle 200;
BA_ "GenSigStartValue" SG_ 602 PDU_LPCh8_Dutycycle 200;
BA_ "GenSigStartValue" SG_ 602 PDU_LPCh3_Dutycycle 200;
BA_ "GenSigStartValue" SG_ 602 PDU_LPCh2_Dutycycle 200;
BA_ "GenSigStartValue" SG_ 602 PDU_LPCh10_Dutycycle 200;
BA_ "GenSigStartValue" SG_ 602 PDU_LPCh1_Dutycycle 200;
BA_ "GenSigStartValue" SG_ 730 PDU_HPCh4_Dutycycle 200;
BA_ "GenSigStartValue" SG_ 730 PDU_HPCh3_Dutycycle 200;
BA_ "GenSigStartValue" SG_ 730 PDU_HPCh2_Dutycycle 200;
BA_ "GenSigStartValue" SG_ 730 PDU_HPCh1_Dutycycle 200;
BA_ "GenMsgCycleTime" BO_ 1456 10;
BA_ "GenMsgSendType" BO_ 1456 0;
BA_ "GenSigStartValue" SG_ 1299 SCIMO_MOT2_A3 100;
BA_ "GenSigStartValue" SG_ 1299 SCIMO_MOT2_A2 100;
BA_ "GenSigStartValue" SG_ 1299 SCIMO_MOT2_A1 100;
BA_ "GenMsgCycleTime" BO_ 1280 10;
BA_ "GenMsgSendType" BO_ 1280 0;
BA_ "GenMsgSendType" BO_ 1296 0;
BA_ "GenMsgCycleTime" BO_ 1296 10;
BA_ "SystemSignalLongSymbol" SG_ 2578777089 EMUS_ContactorControl_ContactorS "EMUS_ContactorControl_ContactorState";
VAL_ 57 CLU_TX_ActionRequest 4 "SET_AIRGAP" 3 "STOP" 2 "START" 1 "PREPARE" 0 "NONE" ;
VAL_ 592 CLU_LevitationState 7 "INCONSISTANT" 6 "ERROR" 5 "LEVI" 4 "LEVI_START" 3 "READY" 2 "PRECHARGE" 1 "IDLE" 0 "OFF" ;
VAL_ 293 MDB6_State 8 "LEVI_AIR_GAP_CHANGE" 14 "ERROR_AIRGAP" 13 "ERROR_OVERTEMP" 12 "ERROR_OVERVOLT" 11 "ERROR_OVERCURRENT" 10 "ERROR" 20 "ERROR_CALCTIME" 19 "ERROR_CHIPTEMP" 18 "ERROR_CURRE_CALIB" 17 "ERROR_CAN" 16 "ERROR_AIRGAP_SEN" 7 "LEVI_UNSTABLE" 6 "LEVI_END" 5 "LEVI_RUN" 4 "LEVI_START" 3 "READY" 2 "PRECHARGE" 1 "IDLE" 0 "INIT" ;
VAL_ 288 MDB5_State 8 "LEVI_AIR_GAP_CHANGE" 15 "ERROR_AIRGAP_SEN" 14 "ERROR_AIRGAP" 13 "ERROR_OVERTEMP" 12 "ERROR_OVERVOLT" 11 "ERROR_OVERCURRENT" 10 "ERROR" 19 "ERROR_CALCTIME" 18 "ERROR_CHIPTEMP" 17 "ERROR_CURRE_CALIB" 16 "ERROR_CAN" 7 "LEVI_UNSTABLE" 6 "LEVI_END" 5 "LEVI_RUN" 4 "LEVI_START" 3 "READY" 2 "PRECHARGE" 1 "IDLE" 0 "INIT" ;
VAL_ 277 MDB4_State 8 "LEVI_AIR_GAP_CHANGE" 15 "ERROR_AIRGAP_SEN" 14 "ERROR_AIRGAP" 13 "ERROR_OVERTEMP" 12 "ERROR_OVERVOLT" 11 "ERROR_OVERCURRENT" 10 "ERROR" 19 "ERROR_CALCTIME" 18 "ERROR_CHIPTEMP" 17 "ERROR_CURRE_CALIB" 16 "ERROR_CAN" 7 "LEVI_UNSTABLE" 6 "LEVI_END" 5 "LEVI_RUN" 4 "LEVI_START" 3 "READY" 2 "PRECHARGE" 1 "IDLE" 0 "INIT" ;
VAL_ 272 MDB3_State 8 "LEVI_AIR_GAP_CHANGE" 18 "ERROR_CHIPTEMP" 17 "ERROR_CURRE_CALIB" 16 "ERROR_CAN" 15 "ERROR_AIRGAP_SEN" 14 "ERROR_AIRGAP" 13 "ERROR_OVERTEMP" 12 "ERROR_OVERVOLT" 11 "ERROR_OVERCURRENT" 10 "ERROR" 19 "ERROR_CALCTIME" 7 "LEVI_UNSTABLE" 6 "LEVI_END" 5 "LEVI_RUN" 4 "LEVI_START" 3 "READY" 2 "PRECHARGE" 1 "IDLE" 0 "INIT" ;
VAL_ 261 MDB2_State 8 "LEVI_AIR_GAP_CHANGE" 15 "ERROR_AIRGAP_SEN" 14 "ERROR_AIRGAP" 13 "ERROR_OVERTEMP" 12 "ERROR_OVERVOLT" 11 "ERROR_OVERCURRENT" 10 "ERROR" 19 "ERROR_CALCTIME" 18 "ERROR_CHIPTEMP" 17 "ERROR_CURRE_CALIB" 16 "ERROR_CAN" 7 "LEVI_UNSTABLE" 6 "LEVI_END" 5 "LEVI_RUN" 4 "LEVI_START" 3 "READY" 2 "PRECHARGE" 1 "IDLE" 0 "INIT" ;
VAL_ 256 MDB1_State 8 "LEVI_AIR_GAP_CHANGE" 15 "ERROR_AIRGAP_SEN" 14 "ERROR_AIRGAP" 13 "ERROR_OVERTEMP" 12 "ERROR_OVERVOLT" 11 "ERROR_OVERCURRENT" 10 "ERROR" 19 "ERROR_CALCTIME" 18 "ERROR_CHIPTEMP" 17 "ERROR_CURRE_CALIB" 16 "ERROR_CAN" 7 "LEVI_UNSTABLE" 6 "LEVI_END" 5 "LEVI_RUN" 4 "LEVI_START" 3 "READY" 2 "PRECHARGE" 1 "IDLE" 0 "INIT" ;
VAL_ 2684354556 OpticalSensor_TX_LEDStatus 2 "FLASHING" 1 "ON" 0 "OFF" ;
VAL_ 2 CANzero_NMT_Node 0 "All" 1 "SensorF" 2 "SensorR" 17 "BrakeF" 18 "BrakeR" 26 "PDU" 10 "HVCU" 25 "HVTU" 34 "TelemetryNode" 33 "MDB1" 35 "MDB2" 39 "MDB3" 40 "MDB4" 41 "MDB5" 49 "MDB6" 50 "Track" 20 "CLU" ;
VAL_ 2 CANzero_NMT_State 1 "Start Remote Node" 2 "Stop Remote Node" 128 "Enter Pre-Operational" 129 "Reset" ;
VAL_ 385 SensorF_TX_PodState 14 "Pod Startup" 13 "Pod Pushable" 12 "Pod Safe to Approch" 11 "Pod End Of Run" 10 "Pod Engage Brakes" 9 "Pod Rolling" 8 "Pod Stop Levitation" 7 "Pod Disengage Brakes" 6 "Pod Crusing" 5 "Pod Stable Levitation" 4 "Pod Start Levitation" 3 "Pod Ready to Launch" 2 "Pod Launch Preparation" 1 "Pod Idle" 0 "Pod Off" ;
VAL_ 513 SensorF_TX_PreopHVCUT 1 "Transition" 0 "No Transitions" ;
VAL_ 513 SensorF_TX_PreopPDUT 1 "Transition" 0 "No Transitions" ;
VAL_ 513 SensorF_TX_PreopBrakeRT 1 "Transition" 0 "No Transitions" ;
VAL_ 513 SensorF_TX_PreopBrakeFT 1 "Transition" 0 "No Transitions" ;
VAL_ 513 SensorF_TX_PreopSensorRT 1 "Transition" 0 "No Transitions" ;
VAL_ 513 SensorF_TX_EnableSensorRT 1 "Transition" 0 "No Transitions" ;
VAL_ 513 SensorF_TX_EnablePDUT 1 "Transition" 0 "No Transitions" ;
VAL_ 513 SensorF_TX_EnableHVCUT 1 "Transition" 0 "No Transitions" ;
VAL_ 513 SensorF_TX_EnableBrakeRT 1 "Transition" 0 "No Transitions" ;
VAL_ 513 SensorF_TX_EnableBrakeFT 1 "Transition" 0 "No Transitions" ;
VAL_ 513 SensorF_TX_SetHVTransition 1 "Transition" 0 "No Transitions" ;
VAL_ 513 SensorF_TX_PreopTransition 1 "Transition" 0 "No Transitions" ;
VAL_ 513 SensorF_TX_LaunchStartTransition 1 "Transition" 0 "No Transitions" ;
VAL_ 513 SensorF_TX_LaunchSetupTransition 1 "Transition" 0 "No Transitions" ;
VAL_ 513 SensorF_TX_HWEnableTransition 1 "Transition" 0 "No Transitions" ;
VAL_ 513 SensorF_TX_ErrorResetTransition 1 "Transition" 0 "No Transitions" ;
VAL_ 513 SensorF_TX_EnableTransition 1 "Transition" 0 "No Transitions" ;
VAL_ 513 SensorF_TX_BrakesTransition 1 "Transition" 0 "No Transitions" ;
VAL_ 1409 SensorF_SDO_RespCode 5 "ERR: Out of range" 4 "ERR: No access in this state" 3 "ERR: Read only object" 2 "ERR: Write only object" 1 "ERR: Non existing object" 0 "OK" ;
VAL_ 1409 SensorF_SDO_ID 0 "Reserved" ;
VAL_ 1473 SensorF_SDO_ID 0 "Reserved" ;
VAL_ 1537 SensorF_SDO_ID 0 "Reserved" ;
VAL_ 1793 SensorF_NodeState 0 "Bootup" 4 "Stopped" 5 "Operational" 127 "Pre-Operational" ;
VAL_ 514 SensorR_TX_ErrorFlag 1 "Error" 0 "No Error" ;
VAL_ 514 SensorR_TX_Enabled 1 "Enabled" 0 "Disabled" ;
VAL_ 514 SensorR_TX_TrajectorySet 2 "Invalid set" 1 "Set" 0 "Not set" ;
VAL_ 514 SensorR_TX_RunState 4 "Idle not ready" 3 "Launch Abort" 2 "Finished" 1 "Ready to Launch" 0 "Launching" ;
VAL_ 706 SensorR_RX_ErrorReset 1 "Reset" 0 "No Reset" ;
VAL_ 706 SensorR_RX_Enable 1 "Enable" 0 "Disable" ;
VAL_ 706 SensorR_RX_LaunchComm 2 "No Start" 1 "Abort Launch" 0 "Start Launch" ;
VAL_ 1410 SensorR_SDO_RespCode 5 "ERR: Out of range" 4 "ERR: No access in this state" 3 "ERR: Read only object" 2 "ERR: Write only object" 1 "ERR: Non existing object" 0 "OK" ;
VAL_ 1410 SensorR_SDO_ID 0 "Reserved" ;
VAL_ 1474 SensorR_SDO_ID 0 "Reserved" ;
VAL_ 1538 SensorR_SDO_ID 0 "Reserved" ;
VAL_ 1794 SensorR_NodeState 0 "Bootup" 4 "Stopped" 5 "Operational" 127 "Pre-Operational" ;
VAL_ 401 BrakeF_TX_SDC_Input 1 "Closed" 0 "Open" ;
VAL_ 401 BrakeF_TX_ErrorFlag 1 "Error" 0 "No Error" ;
VAL_ 401 BrakeF_TX_Enabled 1 "Enabled" 0 "Disabled" ;
VAL_ 401 BrakeF_TX_Status 2 "EngagedService" 1 "EngagedEmergency" 0 "Disengaged" ;
VAL_ 465 BrakeF_RX_Engage 2 "EngageService" 1 "EngageEmergency" 0 "Disengage" ;
VAL_ 465 BrakeF_RX_Enable 1 "Enable" 0 "Disable" ;
VAL_ 465 BrakeF_RX_ErrorReset 1 "Reset" 0 "No Reset" ;
VAL_ 1425 BrakeF_SDO_RespCode 5 "ERR: Out of range" 4 "ERR: No access in this state" 3 "ERR: Read only object" 2 "ERR: Write only object" 1 "ERR: Non existing object" 0 "OK" ;
VAL_ 1425 BrakeF_SDO_ID 0 "Reserved" ;
VAL_ 1489 BrakeF_SDO_ID 0 "Reserved" ;
VAL_ 1553 BrakeF_SDO_ID 0 "Reserved" ;
VAL_ 1809 BrakeF_NodeState 0 "Bootup" 4 "Stopped" 5 "Operational" 127 "Pre-Operational" ;
VAL_ 402 BrakeR_TX_SDC_Input 1 "Closed" 0 "Open" ;
VAL_ 402 BrakeR_TX_ErrorFlag 1 "Error" 0 "No Error" ;
VAL_ 402 BrakeR_TX_Enabled 1 "Enabled" 0 "Disabled" ;
VAL_ 402 BrakeR_TX_Status 2 "EngagedService" 1 "EngagedEmergency" 0 "Disengaged" ;
VAL_ 466 BrakeR_RX_Engage 2 "EngageService" 1 "EngageEmergency" 0 "Disengage" ;
VAL_ 466 BrakeR_RX_Enable 1 "Enable" 0 "Disable" ;
VAL_ 466 BrakeR_RX_ErrorReset 1 "Reset" 0 "No Reset" ;
VAL_ 1426 BrakeR_SDO_RespCode 5 "ERR: Out of range" 4 "ERR: No access in this state" 3 "ERR: Read only object" 2 "ERR: Write only object" 1 "ERR: Non existing object" 0 "OK" ;
VAL_ 1426 BrakeR_SDO_ID 0 "Reserved" ;
VAL_ 1490 BrakeR_SDO_ID 0 "Reserved" ;
VAL_ 1554 BrakeR_SDO_ID 0 "Reserved" ;
VAL_ 1810 BrakeR_NodeState 0 "Bootup" 4 "Stopped" 5 "Operational" 127 "Pre-Operational" ;
VAL_ 410 PDU_TX_PEHWEnabled 1 "Enabled" 0 "Disabled" ;
VAL_ 410 PDU_TX_ErrorFlag 1 "Error" 0 "No Error" ;
VAL_ 410 PDU_TX_Enabled 1 "Enabled" 0 "Disabled" ;
VAL_ 474 PDU_RX_PEHWEnable 1 "Enable" 0 "Disable" ;
VAL_ 474 PDU_RX_ErrorReset 1 "Reset" 0 "No Reset" ;
VAL_ 474 PDU_RX_Enable 1 "Enable" 0 "Disable" ;
VAL_ 1178 PDU_LPCh1_State 3 "External Voltage" 2 "Output Short Circuit" 1 "Status Change Pending" 0 "OK" ;
VAL_ 1434 PDU_SDO_RespCode 5 "ERR: Out of range" 4 "ERR: No access in this state" 3 "ERR: Read only object" 2 "ERR: Write only object" 1 "ERR: Non existing object" 0 "OK" ;
VAL_ 1434 PDU_SDO_ID 0 "Reserved" ;
VAL_ 1498 PDU_SDO_ID 0 "Reserved" ;
VAL_ 1562 PDU_SDO_ID 0 "Reserved" ;
VAL_ 1818 PDU_NodeState 0 "Bootup" 4 "Stopped" 5 "Operational" 127 "Pre-Operational" ;
VAL_ 394 HVCU_TX_Enabled 1 "Enabled" 0 "Disabled" ;
VAL_ 394 HVCU_TX_ErrorFlag 1 "Error" 0 "No Error" ;
VAL_ 394 HVCU_TX_Status 4 "Error" 3 "Shutdown" 2 "Startup" 1 "Activated" 0 "Deactivated" ;
VAL_ 394 HVCU_TX_InternalStatus 7 "Error" 6 "Disable SDC" 5 "Discharging" 4 "Active" 3 "Precharging" 2 "Enable SDC" 1 "Idle" 0 "Startup" ;
VAL_ 458 HVCU_RX_Charging 1 "Charging" 0 "Not Charging" ;
VAL_ 458 HVCU_RX_ErrorReset 1 "Reset" 0 "No Reset" ;
VAL_ 458 HVCU_RX_Activate 1 "Activate" 0 "Deactivate" ;
VAL_ 458 HVCU_RX_Enable 1 "Enable" 0 "Disable" ;
VAL_ 1418 HVCU_SDO_RespCode 5 "ERR: Out of range" 4 "ERR: No access in this state" 3 "ERR: Read only object" 2 "ERR: Write only object" 1 "ERR: Non existing object" 0 "OK" ;
VAL_ 1418 HVCU_SDO_ID 0 "Reserved" ;
VAL_ 1482 HVCU_SDO_ID 0 "Reserved" ;
VAL_ 1546 HVCU_SDO_ID 0 "Reserved" ;
VAL_ 1802 HVCU_NodeState 0 "Bootup" 4 "Stopped" 5 "Operational" 127 "Pre-Operational" ;
VAL_ 1408 SCIMO_FSM_State_MOT2 7 "permanent fault" 6 "fault" 5 "active" 4 "system check" 3 "ready" 2 "disabled" 1 "initial fault" 0 "reset" ;
VAL_ 1392 SCIMO_FSM_State_MOT1 7 "permanent fault" 6 "fault" 5 "active" 4 "system check" 3 "ready" 2 "disabled" 1 "initial fault" 0 "reset" ;
VAL_ 1312 SCIMO_warnNum_MOT2 1002 "Version" 1001 "Parameter Version" 102 "Comm2" 60 "U_ZK zu gross" 53 "Kennfeld Grenze" 52 "Spannungsgrenze" 51 "Torque Change" 50 "Max Torque" 33 "Drehzahllimit" 32 "PowerMin" 31 "PowerMax" 30 "Genauigkeit" 20 "Comm1" 2 "Commutation succedded" 0 "kein Warning" 402 "Comm5" 401 "Comm5" 302 "Comm4" 301 "Comm4" 202 "Comm3" 201 "Comm3" 104 "Uebertemperatur" 101 "Comm2" 21 "Comm1" 19 "Comm1" 18 "Comm1" 17 "Comm1" 16 "Comm1" 15 "Comm1" 14 "Comm1" 13 "Comm1" 12 "Comm1" 11 "Comm1" 10 "Comm1" 1 "Comm" ;
VAL_ 1312 SCIMO_warnNum_MOT1 1002 "Version" 1001 "Parameter Version" 102 "Comm2" 60 "U_ZK zu gross" 53 "Kennfeld Grenze" 52 "Spannungsgrenze" 51 "Torque Change" 50 "Max Torque" 33 "Drehzahllimit" 32 "PowerMin" 31 "PowerMax" 30 "Genauigkeit" 20 "Comm1" 2 "Commutation succedded" 0 "kein Warning" 402 "Comm5" 401 "Comm5" 302 "Comm4" 301 "Comm4" 202 "Comm3" 201 "Comm3" 104 "Uebertemperatur" 101 "Comm2" 21 "Comm1" 19 "Comm1" 18 "Comm1" 17 "Comm1" 16 "Comm1" 15 "Comm1" 14 "Comm1" 13 "Comm1" 12 "Comm1" 11 "Comm1" 10 "Comm1" 1 "Comm" ;
VAL_ 1312 SCIMO_errNum_MOT2 101 "Phasenueberstrom 4 Sample" 7 "Version" 121 "Unterdrehzahl" 120 "Ueberdrehzahl" 110 "Encoderfehler" 104 "Uebertemperatur" 103 "Summenueberstrom" 102 "Phasenueberstrom" 26 "Watchdog" 24 "Motor Temp" 21 "U_ZK zu gross" 20 "U_ZK zu klein" 10 "Encoder Fehler" 9 "Pulslock Fehler" 6 "Commutation" 5 "PS error" 4 "PS watchdog" 3 "Versorgung" 2 "Interpoloator Fehler" 1 "Parameter Fehler" 0 "Kein Fehler aktiv" ;
VAL_ 1312 SCIMO_errNum_MOT1 101 "Phasenueberstrom 4 Sample" 7 "Version" 121 "Unterdrehzahl" 120 "Ueberdrehzahl" 110 "Encoderfehler" 104 "Uebertemperatur" 103 "Summenueberstrom" 102 "Phasenueberstrom" 26 "Watchdog" 24 "Motor Temp" 21 "U_ZK zu gross" 20 "U_ZK zu klein" 10 "Encoder Fehler" 9 "Pulslock Fehler" 6 "Commutation" 5 "PS error" 4 "PS watchdog" 3 "Versorgung" 2 "Interpoloator Fehler" 1 "Parameter Fehler" 0 "Kein Fehler aktiv" ;
VAL_ 2578776064 EMUS_OverallParams_ChargingStage 0 "OFF" 1 "ON" ;
VAL_ 2578776064 EMUS_OverallParams_DCDC_Control 0 "OFF" 1 "ON" ;
VAL_ 2578776064 EMUS_OverallParams_BatteryFan 0 "OFF" 1 "ON" ;
VAL_ 2578776064 EMUS_OverallParams_HeaterEnable 0 "OFF" 1 "ON" ;
VAL_ 2578776064 EMUS_OverallParams_ChargerEnable 0 "OFF" 1 "ON" ;
VAL_ 2578776064 EMUS_OverallParams_LeakageSensor 0 "OFF" 1 "ON" ;
VAL_ 2578776064 EMUS_OverallParams_FastCharge 0 "OFF" 1 "ON" ;
VAL_ 2578776064 EMUS_OverallParams_ChargerMains 0 "OFF" 1 "ON" ;
VAL_ 2578776064 EMUS_OverallParams_IgnitionKey 0 "OFF" 1 "ON" ;
VAL_ 2578777090 EMUS_LoginLevel 0 "Guest" 1 "User" 2 "Admin" ;
VAL_ 2578777092 EMUS_Statistics_DataType 0 "Statistics Value" 1 "Additional Value" 2 "Statistics Timestamp" ;
VAL_ 2578777092 EMUS_Statistics_Identifier 0 "Total Disharge" 1 "Total Charge" 2 "Total Discharge Energy" 3 "Total Charge Energy" 4 "Total Discharge Time" 5 "Total Charge Time" 6 "Total Distance" 7 "Master Clear Count" 8 "Max Discharge Current" 9 "Max Charge Current" 10 "Min Cell Voltage" 11 "Max Cell Voltage" 12 "Max Cell Voltage Difference" 13 "Min Pack Voltage" 14 "Max Pack Voltage" 15 "Min Cell Module Temperature" 16 "Max Cell Module Temperature" 17 "Max Cell Module Temperature Difference" 18 "BMS Starts Count" 19 "Under Voltage Protection Count" 20 "Over Voltage Protection Count" 21 "Discharge Over Current Protection Count" 22 "Charge Over Current Protection Count" 23 "Cell Module Over Heat Protection Count" 24 "Leakage Protection Count" 25 "No Cell Communication Protection Count" 26 "Low Voltage Power Reduction Count" 27 "High Current Power Reduction Count" 28 "High Cell Module Temp Power Reduction Count" 29 "Charger Connected Count" 30 "Charger Disconnected Count" 31 "Pre Heat Stage Count" 32 "Pre Charge Stage Count" 33 "Main Charge Stage Count" 34 "Balancing Stage Count" 35 "Charging Finished Count" 36 "Charging Error Count" 37 "Charging Retry Count" 38 "Trips Count" 39 "Charge Restarts Count" 40 "Cell Over Heat Protection Count" 41 "High Cell Temperature Power Reduction Count" 42 "Min Cell Temperature" 43 "Max Cell Temperature Count" 44 "Max Cell Temperature Difference" ;
VAL_ 2578777093 EMUS_Events_Data_MSB 0 "No event" 1 "BMS Started" 2 "Lost Communication To Cells" 3 "Established Communication To Cells" 4 "Cells Voltage Critically Low" 5 "Critical Low Voltage Recovered" 6 "Cells Voltage Critically High " 7 "Critical High Voltage Recovered" 8 "Discharge Current Critically High" 9 "Discharge Critically High Current Recovered" 10 "Charge Current Critically High" 11 "Charge Critically High Current Recovered" 12 "Cell Module Temperature Critically High" 13 "Critical High Cell Module Temperature Recovered" 14 "Leakage Detected" 15 "Leakage Recovered" 16 "Warning: Low Voltage - Reducing Power" 17 "Power Reduction Due To Low Voltage Recovered" 18 "Warning: High Current - Reducing Power" 19 "Power Reduction Due To High Current Recovered" 20 "Warning: High Cell Module Temperature - Reducing Power" 21 "Power Reduction Due To High Cell Module Temperature Recovered" 22 "Charger Connected" 23 "Charger Disconnected" 24 "Started Pre-Heating Stage" 25 "Started Pre-Charging Stage" 26 "Started Main-Charging Stage" 27 "Started Balancing Stage" 28 "Charging Finished" 29 "Charging Error Occured" 30 "Retrying Charging" 31 "Restarting Charging" 32 "Cell Temperature Critically High" 33 "Critically High Cell Temperature Recovered" 34 "Warning: High Cell Temperature - Reducing Power" 35 "Power Reduction Due To High Cell Temperature Recovered" ;
VAL_ 2578777093 EMUS_Events_DataType 0 "Event Info " 1 "Event timestamp" ;
VAL_ 1433 HVTU_SDO_RespCode 5 "ERR: Out of range" 4 "ERR: No access in this state" 3 "ERR: Read only object" 2 "ERR: Write only object" 1 "ERR: Non existing object" 0 "OK" ;
VAL_ 1433 HVTU_SDO_ID 0 "Reserved" ;
VAL_ 1497 HVTU_SDO_ID 0 "Reserved" ;
VAL_ 1561 HVTU_SDO_ID 0 "Reserved" ;
VAL_ 1817 HVTU_NodeState 0 "Bootup" 4 "Stopped" 5 "Operational" 127 "Pre-Operational" ;
VAL_ 482 TelemetryNode_RX_Shutdown 2 "Reboot" 1 "Shutdown" 0 "None" ;
VAL_ 1442 TelemetryNode_SDO_RespCode 5 "ERR: Out of range" 4 "ERR: No access in this state" 3 "ERR: Read only object" 2 "ERR: Write only object" 1 "ERR: Non existing object" 0 "OK" ;
VAL_ 1442 TelemetryNode_SDO_ID 0 "Reserved" ;
VAL_ 1506 TelemetryNode_SDO_ID 0 "Reserved" ;
VAL_ 1570 TelemetryNode_SDO_ID 0 "Reserved" ;
VAL_ 1826 TelemetryNode_NodeState 0 "Bootup" 4 "Stopped" 5 "Operational" 127 "Pre-Operational" ;
VAL_ 1441 MDB1_SDO_RespCode 5 "ERR: Out of range" 4 "ERR: No access in this state" 3 "ERR: Read only object" 2 "ERR: Write only object" 1 "ERR: Non existing object" 0 "OK" ;
VAL_ 1441 MDB1_SDO_ID 0 "Reserved" ;
VAL_ 1505 MDB1_SDO_ID 0 "Reserved" ;
VAL_ 1569 MDB1_SDO_ID 0 "Reserved" ;
VAL_ 1825 MDB1_NodeState 0 "Bootup" 4 "Stopped" 5 "Operational" 127 "Pre-Operational" ;
VAL_ 1443 MDB2_SDO_RespCode 5 "ERR: Out of range" 4 "ERR: No access in this state" 3 "ERR: Read only object" 2 "ERR: Write only object" 1 "ERR: Non existing object" 0 "OK" ;
VAL_ 1443 MDB2_SDO_ID 0 "Reserved" ;
VAL_ 1507 MDB2_SDO_ID 0 "Reserved" ;
VAL_ 1571 MDB2_SDO_ID 0 "Reserved" ;
VAL_ 1827 MDB2_NodeState 0 "Bootup" 4 "Stopped" 5 "Operational" 127 "Pre-Operational" ;
VAL_ 1447 MDB3_SDO_RespCode 5 "ERR: Out of range" 4 "ERR: No access in this state" 3 "ERR: Read only object" 2 "ERR: Write only object" 1 "ERR: Non existing object" 0 "OK" ;
VAL_ 1447 MDB3_SDO_ID 0 "Reserved" ;
VAL_ 1511 MDB3_SDO_ID 0 "Reserved" ;
VAL_ 1575 MDB3_SDO_ID 0 "Reserved" ;
VAL_ 1831 MDB3_NodeState 0 "Bootup" 4 "Stopped" 5 "Operational" 127 "Pre-Operational" ;
VAL_ 1448 MDB4_SDO_RespCode 5 "ERR: Out of range" 4 "ERR: No access in this state" 3 "ERR: Read only object" 2 "ERR: Write only object" 1 "ERR: Non existing object" 0 "OK" ;
VAL_ 1448 MDB4_SDO_ID 0 "Reserved" ;
VAL_ 1512 MDB4_SDO_ID 0 "Reserved" ;
VAL_ 1576 MDB4_SDO_ID 0 "Reserved" ;
VAL_ 1832 MDB4_NodeState 0 "Bootup" 4 "Stopped" 5 "Operational" 127 "Pre-Operational" ;
VAL_ 1449 MDB5_SDO_RespCode 5 "ERR: Out of range" 4 "ERR: No access in this state" 3 "ERR: Read only object" 2 "ERR: Write only object" 1 "ERR: Non existing object" 0 "OK" ;
VAL_ 1449 MDB5_SDO_ID 0 "Reserved" ;
VAL_ 1513 MDB5_SDO_ID 0 "Reserved" ;
VAL_ 1577 MDB5_SDO_ID 0 "Reserved" ;
VAL_ 1833 MDB5_NodeState 0 "Bootup" 4 "Stopped" 5 "Operational" 127 "Pre-Operational" ;
VAL_ 1457 MDB6_SDO_RespCode 5 "ERR: Out of range" 4 "ERR: No access in this state" 3 "ERR: Read only object" 2 "ERR: Write only object" 1 "ERR: Non existing object" 0 "OK" ;
VAL_ 1457 MDB6_SDO_ID 0 "Reserved" ;
VAL_ 1521 MDB6_SDO_ID 0 "Reserved" ;
VAL_ 1585 MDB6_SDO_ID 0 "Reserved" ;
VAL_ 1841 MDB6_NodeState 0 "Bootup" 4 "Stopped" 5 "Operational" 127 "Pre-Operational" ;
VAL_ 1458 Track_SDO_RespCode 5 "ERR: Out of range" 4 "ERR: No access in this state" 3 "ERR: Read only object" 2 "ERR: Write only object" 1 "ERR: Non existing object" 0 "OK" ;
VAL_ 1458 Track_SDO_ID 0 "Reserved" ;
VAL_ 1522 Track_SDO_ID 0 "Reserved" ;
VAL_ 1586 Track_SDO_ID 0 "Reserved" ;
VAL_ 1842 Track_NodeState 0 "Bootup" 4 "Stopped" 5 "Operational" 127 "Pre-Operational" ;
VAL_ 1428 CLU_SDO_RespCode 5 "ERR: Out of range" 4 "ERR: No access in this state" 3 "ERR: Read only object" 2 "ERR: Write only object" 1 "ERR: Non existing object" 0 "OK" ;
VAL_ 1428 CLU_SDO_ID 0 "Reserved" ;
VAL_ 1492 CLU_SDO_ID 0 "Reserved" ;
VAL_ 1556 CLU_SDO_ID 0 "Reserved" ;
VAL_ 1812 CLU_NodeState 0 "Bootup" 4 "Stopped" 5 "Operational" 127 "Pre-Operational" ;
